VERSION "DIPBNNNYNNNNNNNNNNNNNNNNNNNNNNNNNNNNNNNNNN/4>*%%/4/'%**4NNN///"

NS_ :

BS_:

BU_: Gateway_1 Gateway_0

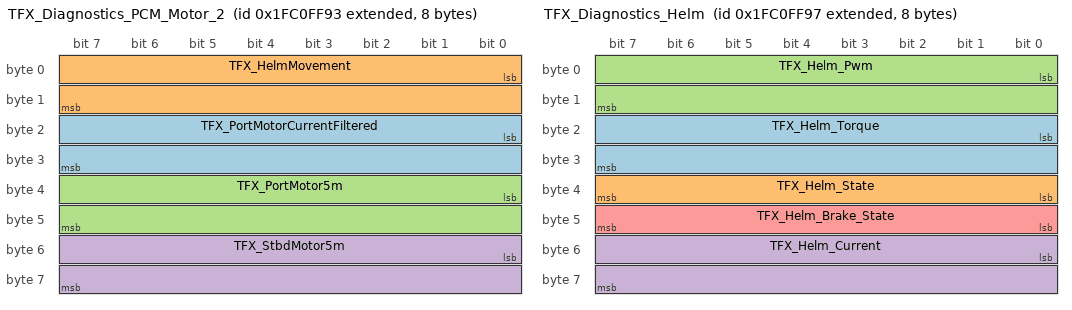
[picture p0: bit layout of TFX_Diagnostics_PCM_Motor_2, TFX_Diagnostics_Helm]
BO_ 2680225683 TFX_Diagnostics_PCM_Motor_2: 8 Vector__XXX
 SG_ TFX_PortMotorCurrentFiltered : 16|16@1- (0.1,0) [-3276.8|3276.7] "A" Vector__XXX
 SG_ TFX_HelmMovement : 0|16@1- (0.001,0) [-32.768|32.767] "°/ms" Vector__XXX
 SG_ TFX_PortMotor5m : 32|16@1- (1,0) [-500|500] "A^2" Vector__XXX
 SG_ TFX_StbdMotor5m : 48|16@1- (1,0) [-500|500] "A^2" Vector__XXX

BO_ 2680225680 TFX_Diagnostics_PCM_Power: 8 Vector__XXX
 SG_ TFX_PCM_Power_total : 32|32@1- (0.01,0) [0|0] "J" Vector__XXX
 SG_ TFX_PCM_Power : 0|32@1- (0.01,0) [0|1400] "W" Vector__XXX

BO_ 2680225687 TFX_Diagnostics_Helm: 8 Vector__XXX
 SG_ TFX_Helm_Torque : 16|16@1+ (0.01,0) [0|0] "in-lb" Vector__XXX
 SG_ TFX_Helm_State : 32|8@1+ (1,0) [0|0] "" Vector__XXX
 SG_ TFX_Helm_Pwm : 0|16@1+ (0.01,0) [0|0] "%" Vector__XXX
 SG_ TFX_Helm_Current : 48|16@1+ (0.001,0) [0|0] "A" Vector__XXX
 SG_ TFX_Helm_Brake_State : 40|8@1+ (1,0) [0|0] "" Vector__XXX

BO_ 2680225686 TFX_Diagnostics_Helm_Sensor: 8 Vector__XXX
 SG_ TFX_HelmSensor2_Sine : 32|16@1+ (1,0) [0|4096] "ADC" Vector__XXX
 SG_ TFX_HelmSensor2_Cosine : 48|16@1+ (1,0) [0|4096] "ADC" Vector__XXX
 SG_ TFX_HelmSensor1_Sine : 0|16@1+ (1,0) [0|4096] "ADC" Vector__XXX
 SG_ TFX_HelmSensor1_Cosine : 16|16@1+ (1,0) [0|4096] "ADC" Vector__XXX

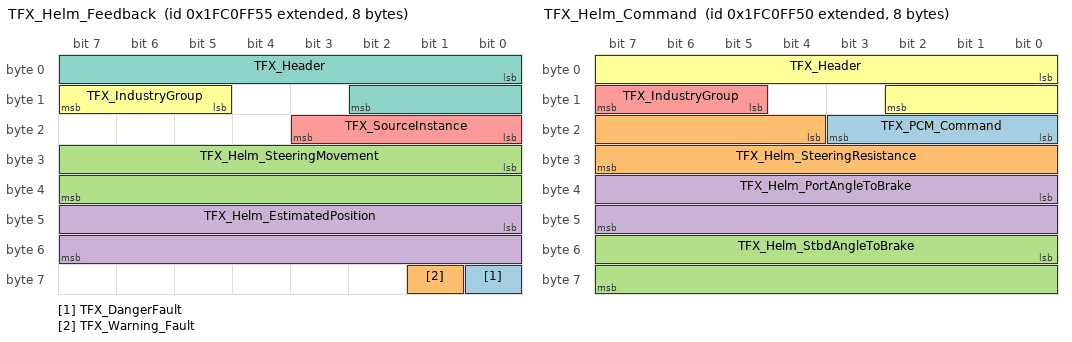
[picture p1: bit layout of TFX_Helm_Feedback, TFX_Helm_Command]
BO_ 2680225621 TFX_Helm_Feedback: 8 Vector__XXX
 SG_ TFX_DangerFault : 56|1@1+ (1,0) [0|0] "" Vector__XXX
 SG_ TFX_Warning_Fault : 57|1@1+ (1,0) [0|0] "" Vector__XXX
 SG_ TFX_Helm_SteeringMovement : 24|16@1- (0.01,0) [0|0] "°" Vector__XXX
 SG_ TFX_Helm_EstimatedPosition : 40|16@1- (0.1,0) [0|0] "°" Vector__XXX
 SG_ TFX_SourceInstance : 16|4@1+ (1,0) [0|0] "" Vector__XXX
 SG_ TFX_IndustryGroup : 13|3@1+ (1,0) [0|0] "" Vector__XXX
 SG_ TFX_Header : 0|11@1+ (1,0) [0|2047] "" Vector__XXX

BO_ 2680225616 TFX_Helm_Command: 8 Vector__XXX
 SG_ TFX_PCM_Command : 16|4@1+ (1,0) [0|0] "" Vector__XXX
 SG_ TFX_Helm_SteeringResistance : 20|12@1+ (0.1,0) [0|0] "%" Vector__XXX
 SG_ TFX_Helm_StbdAngleToBrake : 48|16@1- (0.1,0) [0|0] "°" Vector__XXX
 SG_ TFX_Helm_PortAngleToBrake : 32|16@1- (0.1,0) [0|0] "°" Vector__XXX
 SG_ TFX_IndustryGroup : 13|3@1+ (1,0) [0|0] "" Vector__XXX
 SG_ TFX_Header : 0|11@1+ (1,0) [0|2047] "" Vector__XXX

BO_ 2680225682 TFX_Diagnostics_PCM_Motor: 8 Vector__XXX
 SG_ TFX_PCM_StbdMotorPwm : 16|16@1- (0.01,0) [0|0] "%" Vector__XXX
 SG_ TFX_PCM_StbdMotorCurrent : 48|16@1- (0.01,0) [-327.68|327.67] "A" Vector__XXX
 SG_ TFX_PCM_PortMotorPwm : 0|16@1- (0.01,0) [0|0] "%" Vector__XXX
 SG_ TFX_PCM_PortMotorCurrent : 32|16@1- (0.01,0) [-327.68|327.67] "A" Vector__XXX

BO_ 2680225681 TFX_Diagnostics_PCM_Steering: 8 Vector__XXX
 SG_ TFX_PCM_StbdRudderFbk : 48|16@1- (0.01,0) [0|0] "°" Vector__XXX
 SG_ TFX_PCM_StbdRudderCmd : 16|16@1- (0.01,0) [0|0] "°" Vector__XXX
 SG_ TFX_PCM_PortRudderFbk : 32|16@1- (0.01,0) [0|0] "°" Vector__XXX
 SG_ TFX_PCM_PortRudderCmd : 0|16@1- (0.01,0) [0|0] "°" Vector__XXX

BO_ 2147610885 HeadingTrackControl: 21 Vector__XXX
 SG_ VesselHeading : 152|16@1+ (0.0001,0) [0|6.2831] "rad" Vector__XXX
 SG_ OffTrackLimit : 136|16@1- (1,0) [-32764|32764] "m" Vector__XXX
 SG_ RateOfTurnOrder : 120|16@1- (0.03,0) [-1|1] "rad/sec" Vector__XXX
 SG_ RadiusOfTurnOrder : 104|16@1- (1,0) [-32764|32764] "m" Vector__XXX
 SG_ OffHeadingLimit : 88|16@1+ (0.0001,0) [0|6.2831] "rad" Vector__XXX
 SG_ RudderLimit : 72|16@1+ (0.0057296,0) [0|50] "°" Vector__XXX
 SG_ Track : 56|16@1+ (0.0001,0) [0|6.2831] "rad" Vector__XXX
 SG_ HeadingToSteer : 40|16@1+ (0.0001,0) [0|6.2831] "rad" Vector__XXX
 SG_ CommandedRudderAngle : 24|16@1- (0.0001,0) [-3.415|3.1415] "rad" Vector__XXX
 SG_ CommandedRudderDirection : 21|3@1+ (1,0) [0|0] "" Vector__XXX
 SG_ HeadingReference : 14|2@1+ (1,0) [0|0] "" Vector__XXX
 SG_ TurnMode : 11|3@1+ (1,0) [0|0] "" Vector__XXX
 SG_ SteerigMode : 8|3@1+ (1,0) [0|0] "" Vector__XXX
 SG_ Override : 6|2@1+ (1,0) [0|0] "" Vector__XXX
 SG_ OffTrackLimitExceeded : 4|2@1+ (1,0) [0|0] "" Vector__XXX
 SG_ OffheadingLimitExceeded : 2|2@1+ (1,0) [0|0] "" Vector__XXX
 SG_ RudderLimitExceeded : 0|2@1+ (1,0) [0|0] "" Vector__XXX

BO_ 2680225679 TFX_Diagnostics_VC_SetPt_RPM: 8 Vector__XXX
 SG_ TFX_VC_RPMCmd_SCtr : 48|16@1+ (0.25,0) [0|6000] "RPM" Vector__XXX
 SG_ TFX_VC_RPMCmd_PCtr : 32|16@1+ (0.25,0) [0|6000] "RPM" Vector__XXX
 SG_ TFX_VC_RPMCmd_Stbd : 16|16@1+ (0.25,0) [0|6000] "RPM" Vector__XXX
 SG_ TFX_VC_RPMCmd_Port : 0|16@1+ (0.25,0) [0|6000] "RPM" Vector__XXX

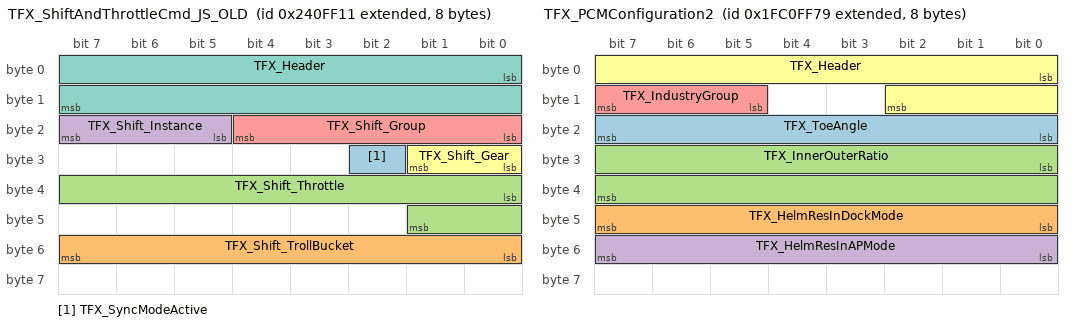
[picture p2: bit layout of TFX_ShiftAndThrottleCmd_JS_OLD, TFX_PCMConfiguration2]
BO_ 2185297681 TFX_ShiftAndThrottleCmd_JS_OLD: 8 Vector__XXX
 SG_ TFX_SyncModeActive : 26|1@1+ (1,0) [0|0] "" Vector__XXX
 SG_ TFX_Shift_TrollBucket : 48|8@1- (1,0) [0|0] "" Vector__XXX
 SG_ TFX_Shift_Throttle : 32|10@1+ (0.1,0) [0|0] "%" Vector__XXX
 SG_ TFX_Shift_Instance : 21|3@1+ (1,0) [0|0] "" Vector__XXX
 SG_ TFX_Shift_Group : 16|5@1+ (1,0) [0|0] "" Vector__XXX
 SG_ TFX_Shift_Gear : 24|2@1+ (1,0) [0|0] "" Vector__XXX
 SG_ TFX_Header : 0|16@1+ (1,0) [0|0] "" Vector__XXX

BO_ 2680225657 TFX_PCMConfiguration2: 8 Vector__XXX
 SG_ TFX_ToeAngle : 16|8@1- (0.1,0) [-12.8|12.7] "deg" Vector__XXX
 SG_ TFX_HelmResInDockMode : 40|8@1+ (1,0) [0|0] "" Vector__XXX
 SG_ TFX_InnerOuterRatio : 24|16@1+ (0.01,0) [0|655.35] "" Vector__XXX
 SG_ TFX_HelmResInAPMode : 48|8@1+ (1,0) [0|0] "" Vector__XXX
 SG_ TFX_IndustryGroup : 13|3@1+ (1,0) [0|0] "" Vector__XXX
 SG_ TFX_Header : 0|11@1+ (1,0) [0|2047] "" Vector__XXX

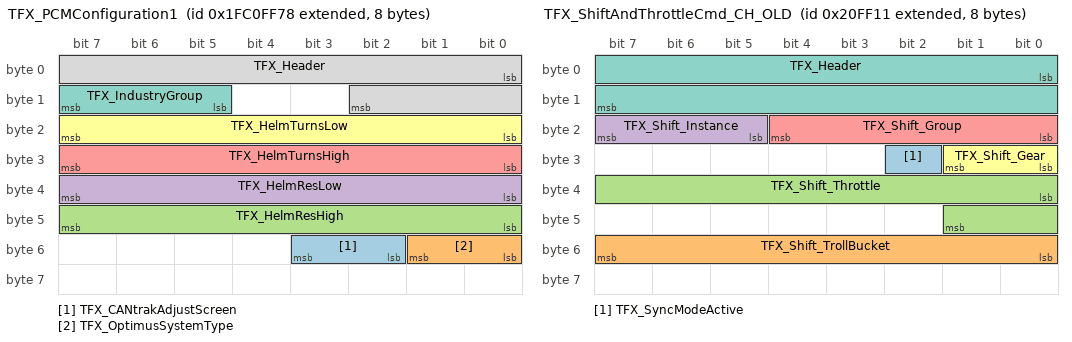
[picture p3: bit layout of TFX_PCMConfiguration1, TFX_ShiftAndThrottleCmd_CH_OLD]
BO_ 2680225656 TFX_PCMConfiguration1: 8 Vector__XXX
 SG_ TFX_CANtrakAdjustScreen : 50|2@1+ (1,0) [0|0] "" Vector__XXX
 SG_ TFX_OptimusSystemType : 48|2@1+ (1,0) [0|0] "" Vector__XXX
 SG_ TFX_HelmResHigh : 40|8@1+ (1,0) [0|0] "" Vector__XXX
 SG_ TFX_HelmResLow : 32|8@1+ (1,0) [0|0] "" Vector__XXX
 SG_ TFX_HelmTurnsHigh : 24|8@1+ (0.1,0) [0|25.5] "Turns" Vector__XXX
 SG_ TFX_HelmTurnsLow : 16|8@1+ (0.1,0) [0|25.5] "Turns" Vector__XXX
 SG_ TFX_IndustryGroup : 13|3@1+ (1,0) [0|0] "" Vector__XXX
 SG_ TFX_Header : 0|11@1+ (1,0) [0|2047] "" Vector__XXX

BO_ 2149646097 TFX_ShiftAndThrottleCmd_CH_OLD: 8 Vector__XXX
 SG_ TFX_SyncModeActive : 26|1@1+ (1,0) [0|0] "" Vector__XXX
 SG_ TFX_Shift_TrollBucket : 48|8@1- (1,0) [0|0] "" Vector__XXX
 SG_ TFX_Shift_Throttle : 32|10@1+ (0.1,0) [0|0] "%" Vector__XXX
 SG_ TFX_Shift_Instance : 21|3@1+ (1,0) [0|0] "" Vector__XXX
 SG_ TFX_Shift_Group : 16|5@1+ (1,0) [0|0] "" Vector__XXX
 SG_ TFX_Shift_Gear : 24|2@1+ (1,0) [0|0] "" Vector__XXX
 SG_ TFX_Header : 0|16@1+ (1,0) [0|0] "" Vector__XXX

BO_ 2680225678 TFX_Diagnostics_ClosedLoop: 8 Vector__XXX
 SG_ TFX_PrtRPMError : 0|16@1- (0.25,0) [-5000|5000] "RPM" Vector__XXX
 SG_ TFX_StbdThrtlAdjust : 48|16@1- (0.1,0) [0|100] "%" Vector__XXX
 SG_ TFX_StbdRPMError : 16|16@1- (0.25,0) [-5000|5000] "RPM" Vector__XXX
 SG_ TFX_PrtThrtlAdjust : 32|16@1- (0.1,0) [0|100] "%" Vector__XXX

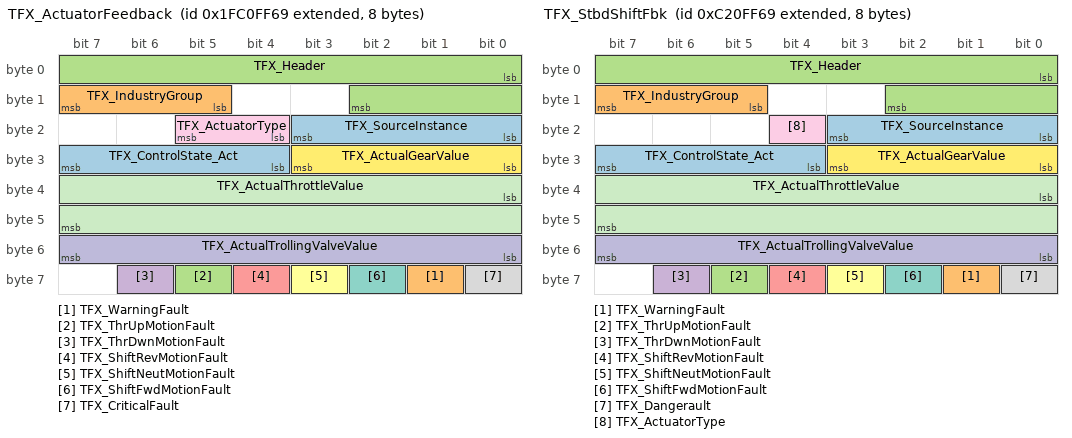
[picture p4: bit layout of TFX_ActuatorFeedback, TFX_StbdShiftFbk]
BO_ 2680225641 TFX_ActuatorFeedback: 8 Vector__XXX
 SG_ TFX_ControlState_Act : 28|4@1+ (1,0) [0|0] "" Vector__XXX
 SG_ TFX_WarningFault : 57|1@1+ (1,0) [0|0] "" Vector__XXX
 SG_ TFX_ThrUpMotionFault : 61|1@1+ (1,0) [0|0] "" Vector__XXX
 SG_ TFX_ThrDwnMotionFault : 62|1@1+ (1,0) [0|0] "" Vector__XXX
 SG_ TFX_ShiftRevMotionFault : 60|1@1+ (1,0) [0|0] "" Vector__XXX
 SG_ TFX_ShiftNeutMotionFault : 59|1@1+ (1,0) [0|0] "" Vector__XXX
 SG_ TFX_ShiftFwdMotionFault : 58|1@1+ (1,0) [0|0] "" Vector__XXX
 SG_ TFX_CriticalFault : 56|1@1+ (1,0) [0|0] "" Vector__XXX
 SG_ TFX_ActuatorType : 20|2@1+ (1,0) [0|3] "" Vector__XXX
 SG_ TFX_ActualTrollingValveValue : 48|8@1+ (1,0) [0|100] "%" Vector__XXX
 SG_ TFX_ActualThrottleValue : 32|16@1+ (0.1,0) [0|100] "%" Vector__XXX
 SG_ TFX_ActualGearValue : 24|4@1- (1,0) [0|0] "" Vector__XXX
 SG_ TFX_SourceInstance : 16|4@1+ (1,0) [0|0] "" Vector__XXX
 SG_ TFX_IndustryGroup : 13|3@1+ (1,0) [0|0] "" Vector__XXX
 SG_ TFX_Header : 0|11@1+ (1,0) [0|2047] "" Vector__XXX

BO_ 2350972777 TFX_StbdShiftFbk: 8 Vector__XXX
 SG_ TFX_ControlState_Act : 28|4@1+ (1,0) [0|0] "" Vector__XXX
 SG_ TFX_WarningFault : 57|1@1+ (1,0) [0|0] "" Vector__XXX
 SG_ TFX_ThrUpMotionFault : 61|1@1+ (1,0) [0|0] "" Vector__XXX
 SG_ TFX_ThrDwnMotionFault : 62|1@1+ (1,0) [0|0] "" Vector__XXX
 SG_ TFX_ShiftRevMotionFault : 60|1@1+ (1,0) [0|0] "" Vector__XXX
 SG_ TFX_ShiftNeutMotionFault : 59|1@1+ (1,0) [0|0] "" Vector__XXX
 SG_ TFX_ShiftFwdMotionFault : 58|1@1+ (1,0) [0|0] "" Vector__XXX
 SG_ TFX_Dangerault : 56|1@1+ (1,0) [0|0] "" Vector__XXX
 SG_ TFX_ActuatorType : 20|1@1+ (1,0) [0|0] "" Vector__XXX
 SG_ TFX_ActualTrollingValveValue : 48|8@1+ (1,0) [0|100] "%" Vector__XXX
 SG_ TFX_ActualThrottleValue : 32|16@1+ (0.1,0) [0|100] "%" Vector__XXX
 SG_ TFX_ActualGearValue : 24|4@1- (1,0) [0|2] "" Vector__XXX
 SG_ TFX_SourceInstance : 16|4@1+ (1,0) [0|0] "" Vector__XXX
 SG_ TFX_IndustryGroup : 13|3@1+ (1,0) [0|0] "" Vector__XXX
 SG_ TFX_Header : 0|11@1+ (1,0) [0|2047] "" Vector__XXX

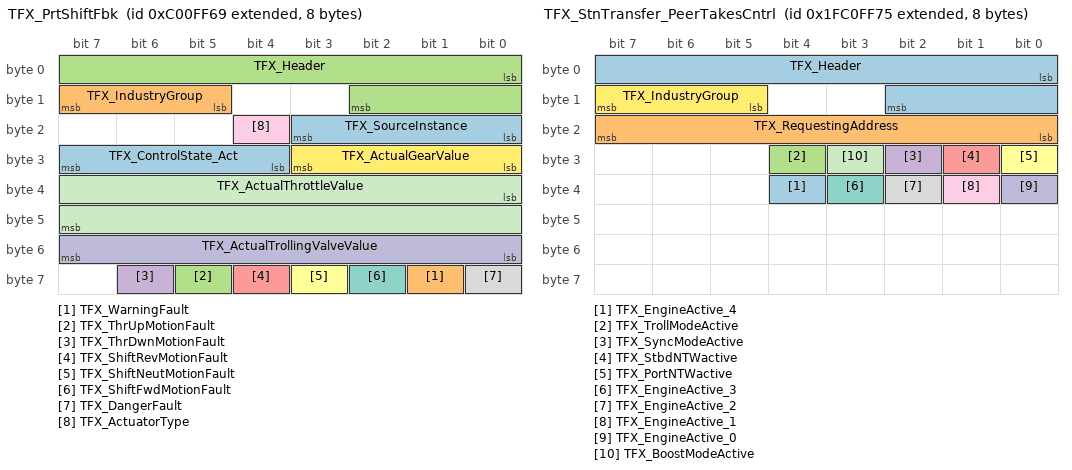
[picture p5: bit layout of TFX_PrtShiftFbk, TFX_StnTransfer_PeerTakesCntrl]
BO_ 2348875625 TFX_PrtShiftFbk: 8 Vector__XXX
 SG_ TFX_ControlState_Act : 28|4@1+ (1,0) [0|0] "" Vector__XXX
 SG_ TFX_WarningFault : 57|1@1+ (1,0) [0|0] "" Vector__XXX
 SG_ TFX_ThrUpMotionFault : 61|1@1+ (1,0) [0|0] "" Vector__XXX
 SG_ TFX_ThrDwnMotionFault : 62|1@1+ (1,0) [0|0] "" Vector__XXX
 SG_ TFX_ShiftRevMotionFault : 60|1@1+ (1,0) [0|0] "" Vector__XXX
 SG_ TFX_ShiftNeutMotionFault : 59|1@1+ (1,0) [0|0] "" Vector__XXX
 SG_ TFX_ShiftFwdMotionFault : 58|1@1+ (1,0) [0|0] "" Vector__XXX
 SG_ TFX_DangerFault : 56|1@1+ (1,0) [0|0] "" Vector__XXX
 SG_ TFX_ActuatorType : 20|1@1+ (1,0) [0|0] "" Vector__XXX
 SG_ TFX_ActualTrollingValveValue : 48|8@1+ (1,0) [0|100] "%" Vector__XXX
 SG_ TFX_ActualThrottleValue : 32|16@1+ (0.1,0) [0|100] "%" Vector__XXX
 SG_ TFX_ActualGearValue : 24|4@1- (1,0) [0|2] "" Vector__XXX
 SG_ TFX_SourceInstance : 16|4@1+ (1,0) [0|0] "" Vector__XXX
 SG_ TFX_IndustryGroup : 13|3@1+ (1,0) [0|0] "" Vector__XXX
 SG_ TFX_Header : 0|11@1+ (1,0) [0|2047] "" Vector__XXX

BO_ 2680225697 TFX_Diagnostics_ThrActs: 8 Vector__XXX
 SG_ TFX_StbdThrtlFbk : 48|16@1+ (0.1,0) [0|100] "%" Vector__XXX
 SG_ TFX_PrtThrtlFbk : 32|16@1+ (0.1,0) [0|100] "%" Vector__XXX
 SG_ TFX_StbdThrtlCmd : 16|16@1+ (0.1,0) [0|100] "%" Vector__XXX
 SG_ TFX_PrtThrtlCmd : 0|16@1+ (0.1,0) [0|100] "%" Vector__XXX

BO_ 2680225653 TFX_StnTransfer_PeerTakesCntrl: 8 Vector__XXX
 SG_ TFX_EngineActive_4 : 36|1@1+ (1,0) [0|0] "" Vector__XXX
 SG_ TFX_RequestingAddress : 16|8@1+ (1,0) [0|0] "" Vector__XXX
 SG_ TFX_TrollModeActive : 28|1@1+ (1,0) [0|0] "" Vector__XXX
 SG_ TFX_SyncModeActive : 26|1@1+ (1,0) [0|0] "" Vector__XXX
 SG_ TFX_StbdNTWactive : 25|1@1+ (1,0) [0|0] "" Vector__XXX
 SG_ TFX_PortNTWactive : 24|1@1+ (1,0) [0|0] "" Vector__XXX
 SG_ TFX_EngineActive_3 : 35|1@1+ (1,0) [0|0] "" Vector__XXX
 SG_ TFX_EngineActive_2 : 34|1@1+ (1,0) [0|0] "" Vector__XXX
 SG_ TFX_EngineActive_1 : 33|1@1+ (1,0) [0|0] "" Vector__XXX
 SG_ TFX_EngineActive_0 : 32|1@1+ (1,0) [0|0] "" Vector__XXX
 SG_ TFX_BoostModeActive : 27|1@1+ (1,0) [0|0] "" Vector__XXX
 SG_ TFX_IndustryGroup : 13|3@1+ (1,0) [0|0] "" Vector__XXX
 SG_ TFX_Header : 0|11@1+ (1,0) [0|2047] "" Vector__XXX

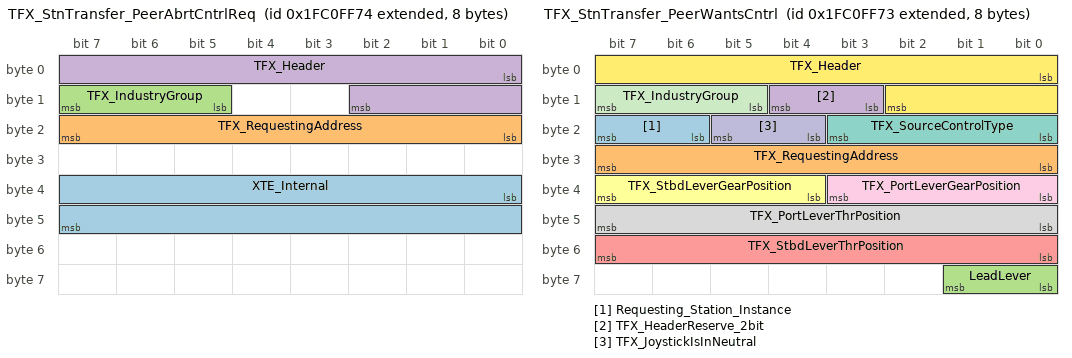
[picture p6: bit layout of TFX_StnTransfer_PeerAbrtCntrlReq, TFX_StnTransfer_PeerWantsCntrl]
BO_ 2680225652 TFX_StnTransfer_PeerAbrtCntrlReq: 8 Vector__XXX
 SG_ XTE_Internal : 32|16@1- (0.1,0) [0|200] "m" Vector__XXX
 SG_ TFX_RequestingAddress : 16|8@1+ (1,0) [0|0] "" Vector__XXX
 SG_ TFX_IndustryGroup : 13|3@1+ (1,0) [0|0] "" Vector__XXX
 SG_ TFX_Header : 0|11@1+ (1,0) [0|2047] "" Vector__XXX

BO_ 2680225651 TFX_StnTransfer_PeerWantsCntrl: 8 Vector__XXX
 SG_ Requesting_Station_Instance : 22|2@1+ (1,0) [0|0] "" Vector__XXX
 SG_ TFX_RequestingAddress : 24|8@1+ (1,0) [0|0] "" Vector__XXX
 SG_ LeadLever : 56|2@1+ (1,0) [0|0] "" Vector__XXX
 SG_ TFX_HeaderReserve_2bit : 11|2@1- (1,0) [0|0] "" Vector__XXX
 SG_ TFX_StbdLeverThrPosition : 48|8@1+ (1,0) [0|100] "%" Vector__XXX
 SG_ TFX_StbdLeverGearPosition : 36|4@1+ (1,0) [0|0] "" Vector__XXX
 SG_ TFX_SourceControlType : 16|4@1+ (1,0) [0|0] "" Vector__XXX
 SG_ TFX_PortLeverThrPosition : 40|8@1+ (1,0) [0|100] "%" Vector__XXX
 SG_ TFX_PortLeverGearPosition : 32|4@1+ (1,0) [0|0] "" Vector__XXX
 SG_ TFX_JoystickIsInNeutral : 20|2@1+ (1,0) [0|0] "" Vector__XXX
 SG_ TFX_IndustryGroup : 13|3@1+ (1,0) [0|0] "" Vector__XXX
 SG_ TFX_Header : 0|11@1+ (1,0) [0|2047] "" Vector__XXX

BO_ 2680225649 TFX_ActuatorStatus: 8 Vector__XXX
 SG_ TFX_TachometerSignalInvalid : 46|1@1+ (1,0) [0|0] "" Vector__XXX
 SG_ TFX_ShiftOutputFault_B : 45|1@1+ (1,0) [0|0] "" Vector__XXX
 SG_ TFX_ShiftOutputFault_A : 44|1@1+ (1,0) [0|0] "" Vector__XXX
 SG_ TFX_PosSensorShrtToGndFault : 39|1@1+ (1,0) [0|0] "" Vector__XXX
 SG_ TFX_PosSensorOpenFault : 40|1@1+ (1,0) [0|0] "" Vector__XXX
 SG_ TFX_PosSensorNotCalibratedFault : 41|1@1+ (1,0) [0|0] "" Vector__XXX
 SG_ TFX_MotorOverCurrentFault : 37|1@1+ (1,0) [0|0] "" Vector__XXX
 SG_ TFX_MotorOpenCircuitFault : 38|1@1+ (1,0) [0|0] "" Vector__XXX
 SG_ TFX_CHorJoystickHrtBtLoss : 47|1@1+ (1,0) [0|0] "" Vector__XXX
 SG_ TFX_BatteryVoltageTooLowFault : 42|1@1+ (1,0) [0|0] "" Vector__XXX
 SG_ TFX_BatteryVoltageTooHighFault : 43|1@1+ (1,0) [0|0] "" Vector__XXX
 SG_ TFX_ThrUpMotionFault : 35|1@1+ (1,0) [0|0] "" Vector__XXX
 SG_ TFX_ThrDwnMotionFault : 36|1@1+ (1,0) [0|0] "" Vector__XXX
 SG_ TFX_ShiftRevMotionFault : 34|1@1+ (1,0) [0|0] "" Vector__XXX
 SG_ TFX_ShiftNeutMotionFault : 33|1@1+ (1,0) [0|0] "" Vector__XXX
 SG_ TFX_ShiftFwdMotionFault : 32|1@1+ (1,0) [0|0] "" Vector__XXX
 SG_ TFX_ActuatorType : 20|1@1+ (1,0) [0|0] "" Vector__XXX
 SG_ TFX_ControlState : 24|4@1+ (1,0) [0|0] "" Vector__XXX
 SG_ TFX_SourceInstance : 16|4@1+ (1,0) [0|0] "" Vector__XXX
 SG_ TFX_IndustryGroup : 13|3@1+ (1,0) [0|0] "" Vector__XXX
 SG_ TFX_Header : 0|11@1+ (1,0) [0|2047] "" Vector__XXX

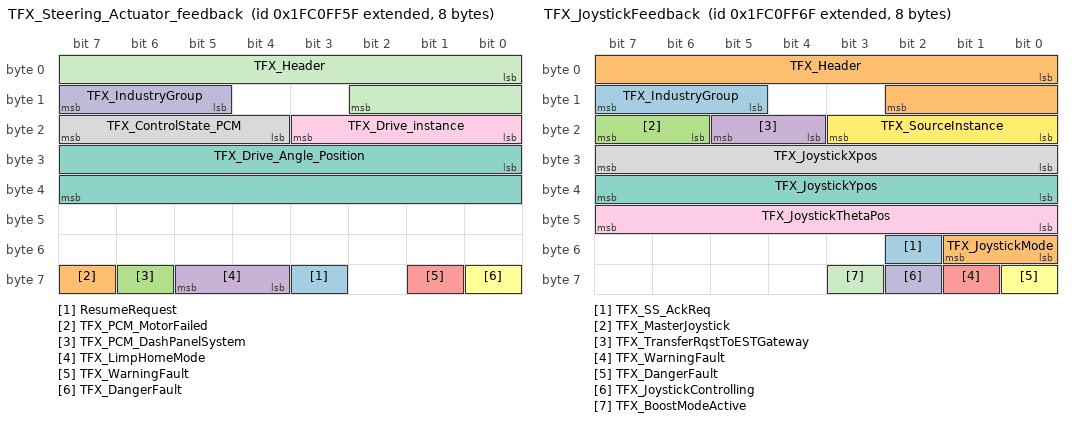
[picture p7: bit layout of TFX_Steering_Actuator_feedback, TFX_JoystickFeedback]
BO_ 2680225631 TFX_Steering_Actuator_feedback: 8 Vector__XXX
 SG_ ResumeRequest : 59|1@1+ (1,0) [0|1] "" Vector__XXX
 SG_ TFX_PCM_MotorFailed : 63|1@1+ (1,0) [0|0] "" Vector__XXX
 SG_ TFX_PCM_DashPanelSystem : 62|1@1+ (1,0) [0|0] "" Vector__XXX
 SG_ TFX_LimpHomeMode : 60|2@1+ (1,0) [0|0] "" Vector__XXX
 SG_ TFX_WarningFault : 57|1@1+ (1,0) [0|0] "" Vector__XXX
 SG_ TFX_DangerFault : 56|1@1+ (1,0) [0|0] "" Vector__XXX
 SG_ TFX_Drive_Angle_Position : 24|16@1- (0.01,0) [-30|30] "deg" Vector__XXX
 SG_ TFX_ControlState_PCM : 20|4@1+ (1,0) [0|0] "" Vector__XXX
 SG_ TFX_Drive_instance : 16|4@1+ (1,0) [0|0] "" Vector__XXX
 SG_ TFX_IndustryGroup : 13|3@1+ (1,0) [0|0] "" Vector__XXX
 SG_ TFX_Header : 0|11@1+ (1,0) [0|2047] "" Vector__XXX

BO_ 2680225647 TFX_JoystickFeedback: 8 Vector__XXX
 SG_ TFX_SS_AckReq : 50|1@1+ (1,0) [0|0] "" Vector__XXX
 SG_ TFX_JoystickMode : 48|2@1+ (1,0) [0|0] "" Vector__XXX
 SG_ TFX_MasterJoystick : 22|2@1+ (1,0) [0|0] "" Vector__XXX
 SG_ TFX_TransferRqstToESTGateway : 20|2@1+ (1,0) [0|3] "" Vector__XXX
 SG_ TFX_WarningFault : 57|1@1+ (1,0) [0|0] "" Vector__XXX
 SG_ TFX_DangerFault : 56|1@1+ (1,0) [0|0] "" Vector__XXX
 SG_ TFX_JoystickYpos : 32|8@1- (1,0) [-100|100] "%" Vector__XXX
 SG_ TFX_JoystickXpos : 24|8@1- (1,0) [-100|100] "%" Vector__XXX
 SG_ TFX_JoystickThetaPos : 40|8@1- (1,0) [-100|100] "%" Vector__XXX
 SG_ TFX_JoystickControlling : 58|1@1+ (1,0) [0|0] "" Vector__XXX
 SG_ TFX_BoostModeActive : 59|1@1+ (1,0) [0|0] "" Vector__XXX
 SG_ TFX_SourceInstance : 16|4@1+ (1,0) [0|0] "" Vector__XXX
 SG_ TFX_IndustryGroup : 13|3@1+ (1,0) [0|0] "" Vector__XXX
 SG_ TFX_Header : 0|11@1+ (1,0) [0|2047] "" Vector__XXX

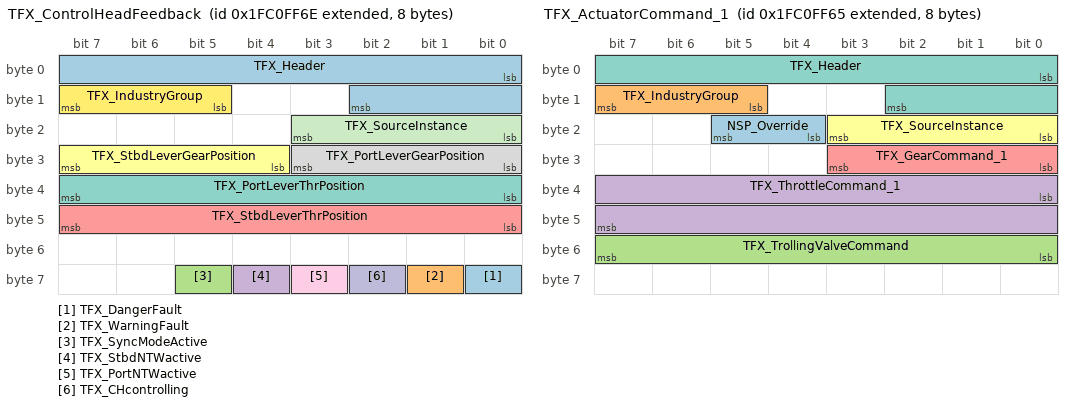
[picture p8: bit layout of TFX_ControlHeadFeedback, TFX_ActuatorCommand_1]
BO_ 2680225646 TFX_ControlHeadFeedback: 8 Vector__XXX
 SG_ TFX_DangerFault : 56|1@1+ (1,0) [0|0] "" Vector__XXX
 SG_ TFX_WarningFault : 57|1@1+ (1,0) [0|0] "" Vector__XXX
 SG_ TFX_SyncModeActive : 61|1@1+ (1,0) [0|0] "" Vector__XXX
 SG_ TFX_StbdNTWactive : 60|1@1+ (1,0) [0|0] "" Vector__XXX
 SG_ TFX_StbdLeverThrPosition : 40|8@1+ (1,0) [0|100] "%" Vector__XXX
 SG_ TFX_StbdLeverGearPosition : 28|4@1+ (1,0) [0|0] "" Vector__XXX
 SG_ TFX_PortLeverThrPosition : 32|8@1+ (1,0) [0|100] "%" Vector__XXX
 SG_ TFX_PortLeverGearPosition : 24|4@1+ (1,0) [0|0] "" Vector__XXX
 SG_ TFX_PortNTWactive : 59|1@1+ (1,0) [0|0] "" Vector__XXX
 SG_ TFX_CHcontrolling : 58|1@1+ (1,0) [0|0] "" Vector__XXX
 SG_ TFX_SourceInstance : 16|4@1+ (1,0) [0|0] "" Vector__XXX
 SG_ TFX_IndustryGroup : 13|3@1+ (1,0) [0|0] "" Vector__XXX
 SG_ TFX_Header : 0|11@1+ (1,0) [0|0] "" Vector__XXX

BO_ 2680225637 TFX_ActuatorCommand_1: 8 Vector__XXX
 SG_ NSP_Override : 20|2@1+ (1,0) [0|0] "" Vector__XXX
 SG_ TFX_IndustryGroup : 13|3@1+ (1,0) [0|0] "" Vector__XXX
 SG_ TFX_TrollingValveCommand : 48|8@1+ (1,0) [0|0] "%" Vector__XXX
 SG_ TFX_ThrottleCommand_1 : 32|16@1+ (0.1,0) [0|100] "%" Vector__XXX
 SG_ TFX_GearCommand_1 : 24|4@1+ (1,0) [0|2] "" Vector__XXX
 SG_ TFX_SourceInstance : 16|4@1+ (1,0) [0|15] "" Vector__XXX
 SG_ TFX_Header : 0|11@1+ (1,0) [0|2047] "" Vector__XXX

BO_ 2680225696 TFX_Diagnostics_ShftActs: 8 Vector__XXX
 SG_ TFX_StbdShftFbk : 24|8@1+ (1,0) [0|0] "" Vector__XXX
 SG_ TFX_PrtShftFbk : 16|8@1+ (1,0) [0|0] "" Vector__XXX
 SG_ TFX_StbdShftCmd : 8|8@1+ (1,0) [0|0] "" Vector__XXX
 SG_ TFX_PrtShftCmd : 0|8@1+ (1,0) [0|0] "" Vector__XXX

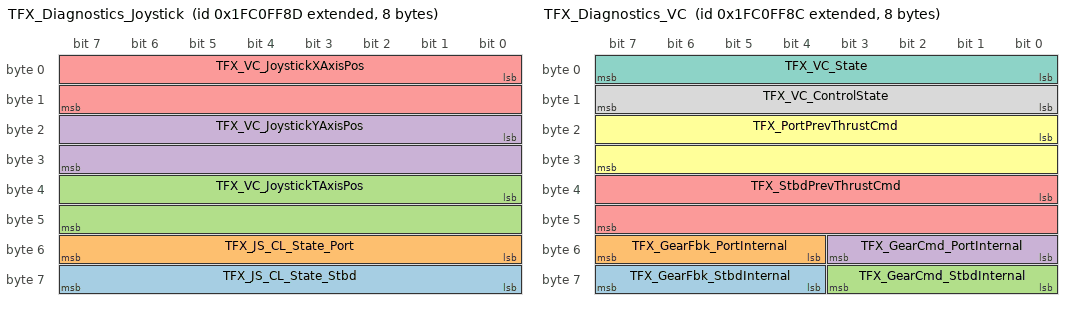
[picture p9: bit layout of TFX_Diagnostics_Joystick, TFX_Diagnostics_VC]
BO_ 2680225677 TFX_Diagnostics_Joystick: 8 Vector__XXX
 SG_ TFX_JS_CL_State_Stbd : 56|8@1+ (1,0) [0|0] "" Vector__XXX
 SG_ TFX_JS_CL_State_Port : 48|8@1+ (1,0) [0|0] "" Vector__XXX
 SG_ TFX_VC_JoystickTAxisPos : 32|16@1- (0.01,0) [-100|100] "%" Vector__XXX
 SG_ TFX_VC_JoystickYAxisPos : 16|16@1- (0.01,0) [-100|100] "%" Vector__XXX
 SG_ TFX_VC_JoystickXAxisPos : 0|16@1- (0.01,0) [-100|100] "%" Vector__XXX

BO_ 2680225676 TFX_Diagnostics_VC: 8 Vector__XXX
 SG_ TFX_GearFbk_StbdInternal : 60|4@1+ (1,0) [0|2] "" Vector__XXX
 SG_ TFX_GearFbk_PortInternal : 52|4@1+ (1,0) [0|2] "" Vector__XXX
 SG_ TFX_GearCmd_StbdInternal : 56|4@1+ (1,0) [0|2] "" Vector__XXX
 SG_ TFX_GearCmd_PortInternal : 48|4@1+ (1,0) [0|2] "" Vector__XXX
 SG_ TFX_StbdPrevThrustCmd : 32|16@1- (0.01,0) [-327.68|327.67] "%" Vector__XXX
 SG_ TFX_PortPrevThrustCmd : 16|16@1- (0.01,0) [-327.68|327.67] "%" Vector__XXX
 SG_ TFX_VC_State : 0|8@1+ (1,0) [0|0] "" Vector__XXX
 SG_ TFX_VC_ControlState : 8|8@1+ (1,0) [0|0] "" Vector__XXX

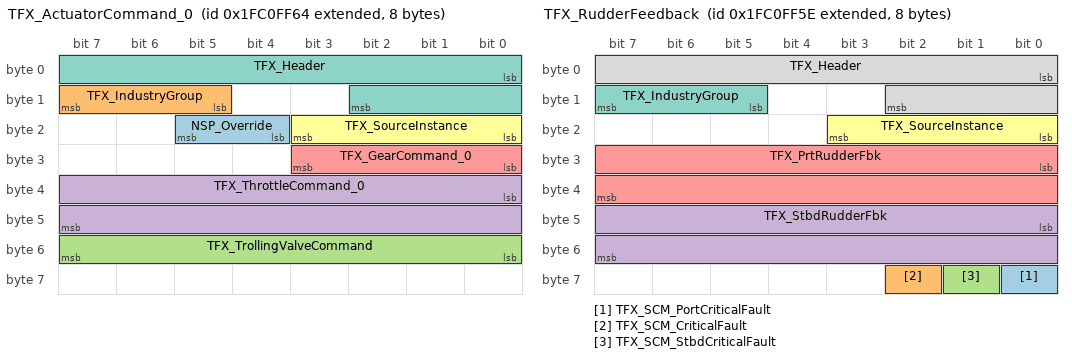
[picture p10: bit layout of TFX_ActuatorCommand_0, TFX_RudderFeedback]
BO_ 2680225636 TFX_ActuatorCommand_0: 8 Vector__XXX
 SG_ NSP_Override : 20|2@1+ (1,0) [0|0] "" Vector__XXX
 SG_ TFX_IndustryGroup : 13|3@1+ (1,0) [0|0] "" Vector__XXX
 SG_ TFX_TrollingValveCommand : 48|8@1+ (1,0) [0|0] "%" Vector__XXX
 SG_ TFX_ThrottleCommand_0 : 32|16@1+ (0.1,0) [0|100] "%" Vector__XXX
 SG_ TFX_GearCommand_0 : 24|4@1+ (1,0) [0|2] "" Vector__XXX
 SG_ TFX_SourceInstance : 16|4@1+ (1,0) [0|15] "" Vector__XXX
 SG_ TFX_Header : 0|11@1+ (1,0) [0|2047] "" Vector__XXX

BO_ 2680225630 TFX_RudderFeedback: 8 Vector__XXX
 SG_ TFX_SCM_PortCriticalFault : 56|1@1- (1,0) [0|0] "" Vector__XXX
 SG_ TFX_SCM_CriticalFault : 58|1@1- (1,0) [0|0] "" Vector__XXX
 SG_ TFX_SCM_StbdCriticalFault : 57|1@1- (1,0) [0|0] "" Vector__XXX
 SG_ TFX_StbdRudderFbk : 40|16@1- (0.01,0) [-30|30] "deg" Vector__XXX
 SG_ TFX_PrtRudderFbk : 24|16@1- (0.01,0) [-30|30] "deg" Vector__XXX
 SG_ TFX_SourceInstance : 16|4@1+ (1,0) [0|0] "" Vector__XXX
 SG_ TFX_IndustryGroup : 13|3@1+ (1,0) [0|0] "" Vector__XXX
 SG_ TFX_Header : 0|11@1+ (1,0) [0|0] "" Vector__XXX

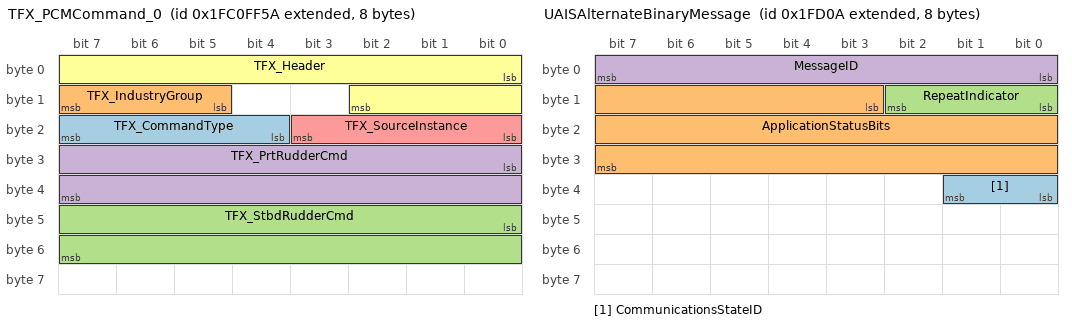
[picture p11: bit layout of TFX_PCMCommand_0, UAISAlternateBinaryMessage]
BO_ 2680225626 TFX_PCMCommand_0: 8 Vector__XXX
 SG_ TFX_CommandType : 20|4@1+ (1,0) [0|0] "" Vector__XXX
 SG_ TFX_IndustryGroup : 13|3@1+ (1,0) [0|0] "" Vector__XXX
 SG_ TFX_StbdRudderCmd : 40|16@1- (0.01,0) [-30|30] "deg" Vector__XXX
 SG_ TFX_PrtRudderCmd : 24|16@1- (0.01,0) [-30|30] "deg" Vector__XXX
 SG_ TFX_SourceInstance : 16|4@1+ (1,0) [0|0] "" Vector__XXX
 SG_ TFX_Header : 0|11@1+ (1,0) [0|0] "" Vector__XXX

BO_ 2147614226 VesselSpeedComponents: 12 Vector__XXX
 SG_ SternSpeedGroundRef : 80|16@1- (0.001,0) [-32.764|32.764] "m/s" Vector__XXX
 SG_ SternSpeedWaterRef : 64|16@1- (0.001,0) [-32.764|32.764] "m/s" Vector__XXX
 SG_ TransSpeedGroundRef : 48|16@1- (0.001,0) [-32.764|32.764] "m/s" Vector__XXX
 SG_ LongSpeedGroundRef : 32|16@1- (0.001,0) [-32.764|32.764] "m/s" Vector__XXX
 SG_ TransSpeedWaterRef : 16|16@1- (0.001,0) [-32.764|32.764] "m/s" Vector__XXX
 SG_ LongSpeedWaterRef : 0|16@1- (0.001,0) [-32.764|32.764] "m/s" Vector__XXX

BO_ 2147614225 DirectionData: 14 Vector__XXX
 SG_ DriftSpeed : 96|16@1+ (0.01,0) [0|655.32] "m/s" Vector__XXX
 SG_ CurrentFlowDirection : 80|16@1+ (0.0001,0) [0|6.2831] "rad" Vector__XXX
 SG_ Speed : 64|16@1+ (0.01,0) [0|655.32] "m/s" Vector__XXX
 SG_ Heading : 48|16@1+ (0.0001,0) [0|6.2831] "rad" Vector__XXX
 SG_ SpeedOverGround : 32|16@1+ (0.0001,0) [0|655.32] "m/s" Vector__XXX
 SG_ CourseOverGround : 16|16@1+ (0.0001,0) [0|6.2831] "rad" Vector__XXX
 SG_ SeqID : 8|8@1+ (1,0) [0|252] "" Vector__XXX
 SG_ SetCOGheadingRef : 4|2@1+ (1,0) [0|0] "" Vector__XXX
 SG_ DataMode : 0|4@1+ (1,0) [0|0] "" Vector__XXX

BO_ 2147614224 SmallCraftStatus: 8 Vector__XXX
 SG_ StarboardTrimTab : 8|8@1- (1,0) [-124|124] "%" Vector__XXX
 SG_ PortTrimTab : 0|8@1- (1,0) [-124|124] "%" Vector__XXX

BO_ 2147613972 MooredBuoyStationData: 42 Vector__XXX
 SG_ WaterTemperature : 256|16@1+ (0.01,0) [0|655.32] "degK" Vector__XXX
 SG_ AirTemperature : 240|16@1+ (0.01,0) [0|655.32] "degK" Vector__XXX
 SG_ PressureTendencyRate : 224|16@1- (10,0) [-327.64|327.64] "Pa/hr" Vector__XXX
 SG_ AtmosphericPressure : 208|16@1+ (100,0) [0|6553200] "Pa" Vector__XXX
 SG_ DominantWavePeriod : 192|16@1+ (0.01,0) [0|655.32] "seconds" Vector__XXX
 SG_ WaveHeight : 176|16@1+ (0.01,0) [0|655.32] "m" Vector__XXX
 SG_ WindGusts : 160|16@1+ (0.01,0) [0|655.32] "m/s" Vector__XXX
 SG_ WindReference : 152|3@1+ (1,0) [0|0] " " Vector__XXX
 SG_ WindDirection : 136|16@1+ (0.01,0) [0|6.2831] "rad" Vector__XXX
 SG_ WindSpeed : 120|16@1+ (0.01,0) [0|655.32] "m/s" Vector__XXX
 SG_ StationLocationLongitude : 88|32@1- (1E-007,0) [-180|180] "degrees" Vector__XXX
 SG_ StationLocationLatitude : 56|32@1- (1E-007,0) [-90|90] "degrees" Vector__XXX
 SG_ MeasurementTime : 24|32@1+ (0.0001,0) [0|86401] "seconds" Vector__XXX
 SG_ MeasurementDate : 8|16@1+ (1,0) [0|65532] "days" Vector__XXX
 SG_ Mode : 0|4@1+ (1,0) [0|0] "" Vector__XXX

BO_ 2147613971 MeteorologicalStationData: 49 Vector__XXX
 SG_ AirTemperature : 192|16@1+ (0.01,0) [0|655.32] "degK" Vector__XXX
 SG_ AtmosphericPressure : 176|16@1+ (100,0) [0|6553200] "Pa" Vector__XXX
 SG_ WindGusts : 160|16@1+ (0.01,0) [0|655.32] "m/s" Vector__XXX
 SG_ WindReference : 152|3@1+ (1,0) [0|0] " " Vector__XXX
 SG_ WindDirection : 136|16@1+ (0.01,0) [0|6.2831] "rad" Vector__XXX
 SG_ WindSpeed : 120|16@1+ (0.01,0) [0|655.32] "m/s" Vector__XXX
 SG_ StationLocationLongitude : 88|32@1- (1E-007,0) [-180|180] "degrees" Vector__XXX
 SG_ StationLocationLatitude : 56|32@1- (1E-007,0) [-90|90] "degrees" Vector__XXX
 SG_ MeasurementTime : 24|32@1+ (0.0001,0) [0|86401] "seconds" Vector__XXX
 SG_ MeasurementDate : 8|16@1+ (1,0) [0|65532] "days" Vector__XXX
 SG_ Mode : 0|4@1+ (1,0) [0|0] "" Vector__XXX

BO_ 2147613970 CurrentStationData: 48 Vector__XXX
 SG_ WaterTemperature : 184|16@1+ (0.01,0) [0|655.32] "degK" Vector__XXX
 SG_ CurrentFlowDirection : 168|16@1+ (0.0001,0) [0|6.2831] "rad" Vector__XXX
 SG_ CurrentSpeed : 152|16@1+ (0.01,0) [0|655.32] "m/s" Vector__XXX
 SG_ MeasurementDepth : 120|32@1+ (0.01,0) [0|429500] "m" Vector__XXX
 SG_ StationLocationLongitude : 88|32@1- (1E-007,0) [-180|180] "degrees" Vector__XXX
 SG_ StationLocationLatitude : 56|32@1- (1E-007,0) [-90|90] "degrees" Vector__XXX
 SG_ MeasurementTime : 24|32@1+ (0.0001,0) [0|86401] "seconds" Vector__XXX
 SG_ MeasurementDate : 8|16@1+ (1,0) [0|65532] "days" Vector__XXX
 SG_ State : 4|3@1+ (1,0) [0|0] "" Vector__XXX
 SG_ Mode : 0|4@1+ (1,0) [0|0] "" Vector__XXX

BO_ 2147613969 SalinityStationData: 44 Vector__XXX
 SG_ WaterTemperature : 152|16@1+ (0.01,0) [0|655.32] "degK" Vector__XXX
 SG_ Salinity : 120|32@1- (1,0) [0|0] "" Vector__XXX
 SG_ StationLocationLongitude : 88|32@1- (1E-007,0) [-180|180] "degrees" Vector__XXX
 SG_ StationLocationLatitude : 56|32@1- (1E-007,0) [-90|90] "degrees" Vector__XXX
 SG_ MeasurementTime : 24|32@1+ (0.0001,0) [0|86401] "seconds" Vector__XXX
 SG_ MeasurementDate : 8|16@1+ (1,0) [0|65532] "days" Vector__XXX
 SG_ Mode : 0|4@1+ (1,0) [0|0] "" Vector__XXX

BO_ 2147613968 TideStationData: 42 Vector__XXX
 SG_ TideLevelStandardDeviation : 136|16@1+ (0.01,0) [0|655.32] "m" Vector__XXX
 SG_ TideLevel : 120|16@1+ (0.001,0) [-32764|32764] "m" Vector__XXX
 SG_ StationLocationLongitude : 88|32@1- (1E-007,0) [-180|180] "degrees" Vector__XXX
 SG_ StationLocationLatitude : 56|32@1- (1E-007,0) [-90|90] "degrees" Vector__XXX
 SG_ MeasurementTime : 24|32@1+ (0.0001,0) [0|86401] "seconds" Vector__XXX
 SG_ MeasurementDate : 8|16@1+ (1,0) [0|65532] "days" Vector__XXX
 SG_ TideTendency : 4|2@1+ (1,0) [0|0] "" Vector__XXX
 SG_ Mode : 0|4@1+ (1,0) [0|0] "" Vector__XXX

BO_ 2147613962 UAISAlternateBinaryMessage: 8 Vector__XXX
 SG_ CommunicationsStateID : 32|2@1+ (1,0) [0|0] "" Vector__XXX
 SG_ ApplicationStatusBits : 11|21@1+ (1,0) [0|0] "" Vector__XXX
 SG_ RepeatIndicator : 8|3@1+ (1,0) [0|0] "" Vector__XXX
 SG_ MessageID : 0|8@1+ (1,0) [0|252] "" Vector__XXX

BO_ 2147613961 UAISVTSTargetMessage: 14 Vector__XXX
 SG_ TargetIDInternationMaritimeOrg : 80|32@1+ (1,0) [0|4294967292] "" Vector__XXX
 SG_ TargetIDMariMobileServiceID : 48|32@1+ (1,0) [0|4294967292] "" Vector__XXX
 SG_ SourceMariMobileServiceID : 16|32@1+ (1,0) [0|4294967292] "" Vector__XXX
 SG_ UAISSpareBitsA : 11|2@1+ (1,0) [0|0] "" Vector__XXX
 SG_ RepeatIndicator : 8|3@1+ (1,0) [0|0] "" Vector__XXX
 SG_ MessageID : 0|8@1+ (1,0) [0|252] "" Vector__XXX

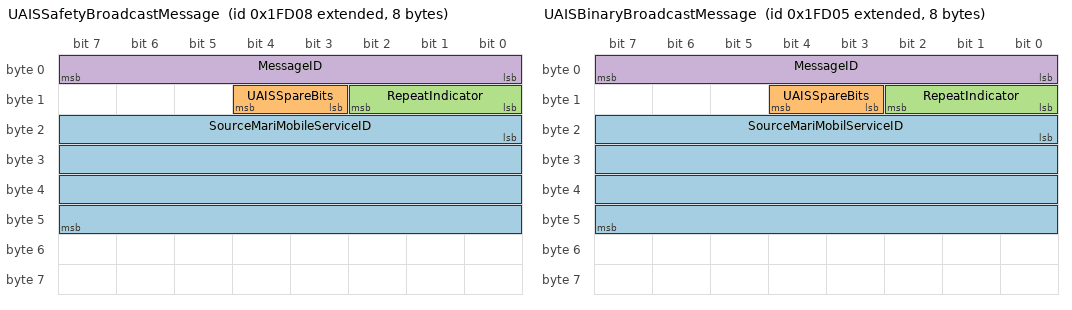
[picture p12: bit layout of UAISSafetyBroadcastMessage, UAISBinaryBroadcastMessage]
BO_ 2147613960 UAISSafetyBroadcastMessage: 8 Vector__XXX
 SG_ SourceMariMobileServiceID : 16|32@1+ (1,0) [0|4294967292] "" Vector__XXX
 SG_ UAISSpareBits : 11|2@1+ (1,0) [0|0] "" Vector__XXX
 SG_ RepeatIndicator : 8|3@1+ (1,0) [0|0] "" Vector__XXX
 SG_ MessageID : 0|8@1+ (1,0) [0|252] "" Vector__XXX

BO_ 2147613959 UAISAddressedSafetyTextMessage: 11 Vector__XXX
 SG_ DestinationMariMobileServiceID : 56|32@1+ (1,0) [0|0] "" Vector__XXX
 SG_ SequenceNumber : 48|8@1+ (1,0) [0|252] "" Vector__XXX
 SG_ SourceMariMobileServiceID : 16|32@1+ (1,0) [0|4294967292] "" Vector__XXX
 SG_ UAISSpareBits : 11|2@1+ (1,0) [0|0] "" Vector__XXX
 SG_ RepeatIndicator : 8|3@1+ (1,0) [0|0] "" Vector__XXX
 SG_ MessageID : 0|8@1+ (1,0) [0|252] "" Vector__XXX

BO_ 2147613958 EnvironmentalParameters: 8 Vector__XXX
 SG_ AtmosphericPressure : 40|16@1+ (100,0) [0|6553200] "Pa" Vector__XXX
 SG_ OutsideAmbientAirTemp : 24|16@1+ (0.01,0) [0|655.32] "degK" Vector__XXX
 SG_ WaterTemperature : 8|16@1+ (0.01,0) [0|655.32] "degK" Vector__XXX
 SG_ SID : 0|8@1+ (1,0) [0|252] "" Vector__XXX

BO_ 2147613957 UAISBinaryBroadcastMessage: 8 Vector__XXX
 SG_ SourceMariMobilServiceID : 16|32@1+ (1,0) [0|4294967292] "" Vector__XXX
 SG_ UAISSpareBits : 11|2@1+ (1,0) [0|0] "" Vector__XXX
 SG_ RepeatIndicator : 8|3@1+ (1,0) [0|0] "" Vector__XXX
 SG_ MessageID : 0|8@1+ (1,0) [0|252] "" Vector__XXX

BO_ 2147613956 UAISAdressedBinaryMessage: 11 Vector__XXX
 SG_ DestinationMariMobileServiceID : 56|32@1+ (1,0) [0|0] "" Vector__XXX
 SG_ SequenceID : 48|8@1+ (1,0) [0|252] "" Vector__XXX
 SG_ SouceMariMobileServiceID : 16|32@1+ (1,0) [0|0] "" Vector__XXX
 SG_ UAISSpareBits : 11|2@1+ (1,0) [0|0] "" Vector__XXX
 SG_ RepeatIndicator : 8|3@1+ (1,0) [0|0] "" Vector__XXX
 SG_ MessageID : 0|8@1+ (1,0) [0|0] "" Vector__XXX

BO_ 2147613955 UAISShipStaticVoyageInformation: 17 Vector__XXX
 SG_ ShipCallSignal7 : 128|8@1+ (1,0) [0|0] "" Vector__XXX
 SG_ ShipCallSignal6 : 120|8@1+ (1,0) [0|0] "" Vector__XXX
 SG_ ShipCallSignal5 : 112|8@1+ (1,0) [0|0] "" Vector__XXX
 SG_ ShipCallSignal4 : 104|8@1+ (1,0) [0|0] "" Vector__XXX
 SG_ ShipCallSignal3 : 96|8@1+ (1,0) [0|0] "" Vector__XXX
 SG_ ShipCallSignal2 : 88|8@1+ (1,0) [0|0] "" Vector__XXX
 SG_ ShipCallSignal1 : 80|8@1+ (1,0) [0|0] "" Vector__XXX
 SG_ InternationlMaritimeOrgNumber : 48|32@1+ (1,0) [0|4294967292] "" Vector__XXX
 SG_ UAISSpareBits : 43|2@1+ (1,0) [0|0] "" Vector__XXX
 SG_ RepeatIndicator : 40|3@1+ (1,0) [0|0] "" Vector__XXX
 SG_ MaritimeMobileServiceIDNumber : 8|32@1+ (1,0) [0|4294967292] "" Vector__XXX
 SG_ MessageID : 0|8@1+ (1,0) [0|252] "" Vector__XXX

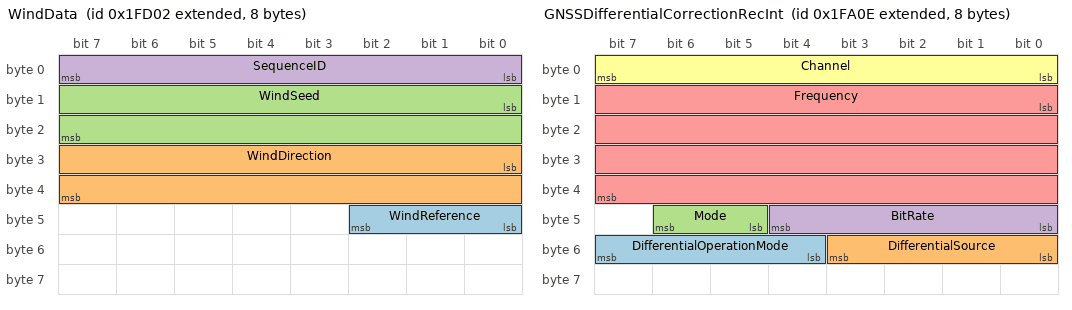
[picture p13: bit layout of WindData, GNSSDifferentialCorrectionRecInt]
BO_ 2147613954 WindData: 8 Vector__XXX
 SG_ WindReference : 40|3@1+ (1,0) [0|7] "" Vector__XXX
 SG_ WindDirection : 24|16@1+ (0.0001,0) [0|6.2831] "rad" Vector__XXX
 SG_ WindSeed : 8|16@1+ (0.01,0) [0|655.32] "m/s" Vector__XXX
 SG_ SequenceID : 0|8@1+ (1,0) [0|252] "" Vector__XXX

BO_ 2147613702 LoranCSignalData: 15 Vector__XXX
 SG_ StationASF : 88|32@1- (1E-009,0) [-2.14|2.14] "seconds" Vector__XXX
 SG_ StationECD : 56|32@1- (1E-009,0) [-2.14|2.14] "seconds" Vector__XXX
 SG_ StationSNR : 40|16@1- (0.01,0) [-327.64|327.64] "dB" Vector__XXX
 SG_ StationIdentifier : 32|8@1+ (1,0) [0|0] "" Vector__XXX
 SG_ GroupRepetitionRate : 0|32@1- (1E-009,0) [-2.14|2.14] "seconds" Vector__XXX

BO_ 2147613701 LoranCRangeData: 32 Vector__XXX
 SG_ Mode : 248|4@1+ (1,0) [0|0] "" Vector__XXX
 SG_ StationStatusZ : 244|4@1+ (1,0) [0|0] "" Vector__XXX
 SG_ StationStatusY : 240|4@1+ (1,0) [0|0] "" Vector__XXX
 SG_ StationStatusX : 236|4@1+ (1,0) [0|0] "" Vector__XXX
 SG_ StationStatusW : 232|4@1+ (1,0) [0|0] "" Vector__XXX
 SG_ StationStatusV : 228|4@1+ (1,0) [0|0] "" Vector__XXX
 SG_ StationStatusMaster : 224|4@1+ (1,0) [0|0] "" Vector__XXX
 SG_ ZSecondaryRange : 192|32@1- (1E-009,0) [-2.14|2.14] "seconds" Vector__XXX
 SG_ YSecondaryRange : 160|32@1- (1E-009,0) [-2.14|2.14] "seconds" Vector__XXX
 SG_ XSecondaryRange : 128|32@1- (1E-009,0) [-2.14|2.14] "seconds" Vector__XXX
 SG_ WSecondaryRange : 96|32@1- (1E-009,0) [-2.14|2.14] "seconds" Vector__XXX
 SG_ VSecondaryRange : 64|32@1- (1E-009,0) [-2.14|2.14] "seconds" Vector__XXX
 SG_ MasterRange : 32|32@1- (1E-009,0) [-2.14|2.14] "seconds" Vector__XXX
 SG_ GroupRepetitionInterval : 0|32@1- (1E-009,0) [-2.14|2.14] "seconds" Vector__XXX

BO_ 2147613700 LoranCTDData: 32 Vector__XXX
 SG_ Mode : 248|4@1+ (1,0) [0|0] "" Vector__XXX
 SG_ StationStatusZ : 244|4@1+ (1,0) [0|0] "" Vector__XXX
 SG_ StationStatusY : 240|4@1+ (1,0) [0|0] "" Vector__XXX
 SG_ StationStatusX : 236|4@1+ (1,0) [0|0] "" Vector__XXX
 SG_ StationStatusW : 232|4@1+ (1,0) [0|0] "" Vector__XXX
 SG_ StationStatusV : 228|4@1+ (1,0) [0|0] "" Vector__XXX
 SG_ StationStatusMaster : 224|4@1+ (1,0) [0|0] "" Vector__XXX
 SG_ ZSecondaryTD : 192|32@1- (1E-009,0) [-2.14|2.14] "seconds" Vector__XXX
 SG_ YSecondaryTD : 160|32@1- (1E-009,0) [-2.14|2.14] "seconds" Vector__XXX
 SG_ XSecondaryTD : 128|32@1- (1E-009,0) [-2.14|2.14] "seconds" Vector__XXX
 SG_ WSecondaryTD : 96|32@1- (1E-009,0) [-2.14|2.14] "seconds" Vector__XXX
 SG_ VSecondaryTD : 64|32@1- (1E-009,0) [-2.14|2.14] "seconds" Vector__XXX
 SG_ MasterRange : 32|32@1- (1E-009,0) [-2.14|2.14] "seconds" Vector__XXX
 SG_ GroupRepetitionInterval : 0|32@1- (1E-009,0) [-2.14|2.14] "seconds" Vector__XXX

BO_ 2147613456 DSCCallInformation: 21 Vector__XXX
 SG_ ProposedTxFrequencyChannel6 : 160|8@1+ (1,0) [0|0] "" Vector__XXX
 SG_ ProposedTxFrequencyChannel5 : 152|8@1+ (1,0) [0|0] "" Vector__XXX
 SG_ ProposedTxFrequencyChannel4 : 144|8@1+ (1,0) [0|0] "" Vector__XXX
 SG_ ProposedTxFrequencyChannel3 : 136|8@1+ (1,0) [0|0] "" Vector__XXX
 SG_ ProposedTxFrequencyChannel2 : 128|8@1+ (1,0) [0|0] "" Vector__XXX
 SG_ ProposedTxFrequencyChannel1 : 120|8@1+ (1,0) [0|0] "" Vector__XXX
 SG_ ProposedRxFrequencyChannel6 : 112|8@1+ (1,0) [0|0] "" Vector__XXX
 SG_ ProposedRxFrequencyChannel5 : 104|8@1+ (1,0) [0|0] "" Vector__XXX
 SG_ ProposedRxFrequencyChannel4 : 96|8@1+ (1,0) [0|0] "" Vector__XXX
 SG_ ProposedRxFrequencyChannel3 : 88|8@1+ (1,0) [0|0] "" Vector__XXX
 SG_ ProposedRxFrequencyChannel2 : 80|8@1+ (1,0) [0|0] "" Vector__XXX
 SG_ ProposedRxFrequencyChannel1 : 72|8@1+ (1,0) [0|0] "" Vector__XXX
 SG_ SubsequentCommunicationMode : 64|8@1+ (1,0) [0|0] "" Vector__XXX
 SG_ NatureOfDistress : 56|8@1+ (1,0) [0|0] "" Vector__XXX
 SG_ DSCMessageAddress5 : 48|8@1+ (1,0) [0|0] "" Vector__XXX
 SG_ DSCMessageAddress4 : 40|8@1+ (1,0) [0|0] "" Vector__XXX
 SG_ DSCMessageAddress3 : 32|8@1+ (1,0) [0|0] "" Vector__XXX
 SG_ DSCMessageAddress2 : 24|8@1+ (1,0) [0|0] "" Vector__XXX
 SG_ DSCMessageAddress1 : 16|8@1+ (1,0) [0|0] "" Vector__XXX
 SG_ DSCCategorySymbol : 8|8@1+ (1,0) [0|0] "" Vector__XXX
 SG_ DSCFormatSymbol : 0|8@1+ (1,0) [0|0] "" Vector__XXX

BO_ 2147613447 RadioFrequency: 19 Vector__XXX
 SG_ ChannelBandwidth : 136|16@1+ (1,0) [0|65532] "Hz" Vector__XXX
 SG_ Mode : 128|8@1+ (1,0) [0|0] "" Vector__XXX
 SG_ TxPower : 112|16@1+ (1,0) [0|65532] "Watts" Vector__XXX
 SG_ RadioChannel6 : 104|8@1+ (1,0) [0|0] "Hz" Vector__XXX
 SG_ RadioChannel5 : 96|8@1+ (1,0) [0|0] "Hz" Vector__XXX
 SG_ RadioChannel4 : 88|8@1+ (1,0) [0|0] "Hz" Vector__XXX
 SG_ RadioChannel3 : 80|8@1+ (1,0) [0|0] "Hz" Vector__XXX
 SG_ RadioChannel2 : 72|8@1+ (1,0) [0|0] "Hz" Vector__XXX
 SG_ RadioChannel1 : 64|8@1+ (1,0) [0|0] "Hz" Vector__XXX
 SG_ TxFrequency : 32|32@1+ (10,0) [0|327040] "Hz" Vector__XXX
 SG_ RxFrequency : 0|32@1+ (10,0) [0|327040] "Hz" Vector__XXX

BO_ 2147613204 GLONASSAlmanacData: 26 Vector__XXX
 SG_ tnAtau : 196|12@1+ (1,0) [0|0] "" Vector__XXX
 SG_ tcA : 168|28@1+ (1,0) [0|0] "" Vector__XXX
 SG_ inADelta : 144|24@1+ (1,0) [0|0] "" Vector__XXX
 SG_ nALambda : 120|24@1+ (1,0) [0|0] "" Vector__XXX
 SG_ tnA : 96|24@1+ (1,0) [0|0] "" Vector__XXX
 SG_ TnADelta : 72|24@1+ (1,0) [0|0] "" Vector__XXX
 SG_ nAOmega : 56|16@1+ (1,0) [0|0] "" Vector__XXX
 SG_ DOTDeltaTnA : 48|8@1+ (1,0) [0|0] "" Vector__XXX
 SG_ nAEpsilon : 32|16@1+ (1,0) [0|0] "" Vector__XXX
 SG_ HnA : 27|5@1+ (1,0) [0|0] "" Vector__XXX
 SG_ CnA : 26|1@1+ (1,0) [0|0] "" Vector__XXX
 SG_ NA : 8|16@1+ (1,0) [0|65532] "" Vector__XXX
 SG_ PRN : 0|8@1+ (1,0) [0|252] "" Vector__XXX

BO_ 2147613199 GNSSDiffCorrReceiverSignal: 20 Vector__XXX
 SG_ SatelliteServiceIDNumber : 144|16@1+ (1,0) [0|0] "" Vector__XXX
 SG_ TimeSinceLastSatDiffSync : 128|16@1+ (0.01,0) [0|655.32] "seconds" Vector__XXX
 SG_ DifferentialSource : 124|4@1+ (1,0) [0|0] "" Vector__XXX
 SG_ UsedAsCorrectionSource : 120|2@1+ (1,0) [0|0] "" Vector__XXX
 SG_ BitRate : 112|5@1+ (1,0) [0|0] "" Vector__XXX
 SG_ StationID : 100|12@1+ (1,0) [0|0] "" Vector__XXX
 SG_ StationType : 96|4@1+ (1,0) [0|0] "" Vector__XXX
 SG_ Frequency : 64|32@1- (10,0) [0|327040] "Hz" Vector__XXX
 SG_ SignalSNR : 48|16@1- (0.01,0) [-327.64|327.64] "dB" Vector__XXX
 SG_ SignalStrength : 16|32@1- (0.01,0) [-327.64|327.64] "uV/m" Vector__XXX
 SG_ Channel : 8|8@1+ (1,0) [0|252] "" Vector__XXX
 SG_ SID : 0|8@1+ (1,0) [0|252] "" Vector__XXX

BO_ 2147613198 GNSSDifferentialCorrectionRecInt: 8 Vector__XXX
 SG_ DifferentialOperationMode : 52|4@1+ (1,0) [0|0] "" Vector__XXX
 SG_ DifferentialSource : 48|4@1+ (1,0) [0|0] "" Vector__XXX
 SG_ Mode : 45|2@1+ (1,0) [0|0] "" Vector__XXX
 SG_ BitRate : 40|5@1+ (1,0) [0|0] "" Vector__XXX
 SG_ Frequency : 8|32@1+ (1,0) [0|327040] "Hz" Vector__XXX
 SG_ Channel : 0|8@1+ (1,0) [0|252] "" Vector__XXX

BO_ 2147613197 DGNSSCorrections: 16 Vector__XXX
 SG_ IOD : 120|8@1+ (1,0) [0|252] "" Vector__XXX
 SG_ UDRE : 104|16@1+ (0.01,0) [0|655.32] "m" Vector__XXX
 SG_ RRC : 88|16@1+ (0.0001,0) [-3.2764|3.2764] "m/s" Vector__XXX
 SG_ PRC : 56|32@1+ (0.0001,0) [-214700|214700] "m" Vector__XXX
 SG_ SatelliteID : 48|8@1+ (1,0) [0|252] "" Vector__XXX
 SG_ StationHealth : 40|4@1+ (1,0) [0|15] "" Vector__XXX
 SG_ TimeOfCorrections : 24|16@1+ (0.1,0) [0|6553.2] "sec" Vector__XXX
 SG_ ReferenceStationType : 20|4@1+ (1,0) [0|15] "" Vector__XXX
 SG_ ReferenceStationID : 8|12@1+ (1,0) [0|0] "" Vector__XXX
 SG_ SequenceID : 0|8@1+ (1,0) [0|252] "" Vector__XXX

BO_ 2147613195 GNSSPseudorangeErrorStatistic: 15 Vector__XXX
 SG_ StdDevAltitudeError : 104|16@1+ (0.01,0) [0|655.32] "m" Vector__XXX
 SG_ StdDevLongitudeError : 88|16@1+ (0.01,0) [0|655.32] "m" Vector__XXX
 SG_ StdDevLatitudeError : 72|16@1+ (0.01,0) [0|655.32] "m" Vector__XXX
 SG_ OrientationOfErrorEllipse : 56|16@1+ (0.0001,0) [0|6.2831] "rad" Vector__XXX
 SG_ StdDevMinorErrorEllipse : 40|16@1+ (0.01,0) [0|655.32] "m" Vector__XXX
 SG_ StdDevMajorErrorEllipse : 24|16@1+ (0.01,0) [0|655.32] "m" Vector__XXX
 SG_ RmsStdDevOfRangeInputs : 8|16@1+ (0.01,0) [0|655.32] "m" Vector__XXX
 SG_ SequenceID : 0|8@1+ (1,0) [0|252] "" Vector__XXX

BO_ 2147613194 GNSSRAIMSettings: 8 Vector__XXX
 SG_ PseudorangeResidualFilteringTime : 32|16@1+ (1,0) [0|65532] "sec" Vector__XXX
 SG_ ProbabilityOfMissedDetection : 24|8@1- (1,0) [-124|124] "%" Vector__XXX
 SG_ ProbabilityOfFalseAlarm : 16|8@1- (1,0) [-124|124] "%" Vector__XXX
 SG_ RadialPositionErrorMaxThresshold : 0|16@1+ (0.01,0) [0|655.32] "m" Vector__XXX

BO_ 2147613193 GNSSRAIMOutput: 13 Vector__XXX
 SG_ StdDeviationOfBias : 88|16@1+ (0.01,0) [-327.64|327.64] "m" Vector__XXX
 SG_ EstimateOfPseudorangeBias : 72|16@1+ (0.01,0) [-327.64|327.64] "m" Vector__XXX
 SG_ ProbatilityOfMissedDetection : 56|16@1+ (0.01,0) [-327.64|327.64] "m" Vector__XXX
 SG_ SVIDofMostLikelyFailedSat : 48|8@1+ (1,0) [0|252] "" Vector__XXX
 SG_ AltitudeExpectedError : 32|16@1+ (0.01,0) [-327.64|327.64] "m" Vector__XXX
 SG_ LatitudeExpectedError : 16|16@1+ (0.01,0) [-327.64|327.64] "m" Vector__XXX
 SG_ LatitudeExpectedError : 10|6@1+ (1,0) [0|0] "" Vector__XXX
 SG_ IntegrityFlag : 8|2@1+ (1,0) [0|3] "" Vector__XXX
 SG_ SequenceID : 0|8@1+ (1,0) [0|252] "" Vector__XXX

BO_ 2147613190 GNSSPseudorangeNoiseStatistics: 15 Vector__XXX
 SG_ STDAltitudeError : 104|16@1+ (0.01,0) [0|655.32] "m" Vector__XXX
 SG_ STDLongitudeError : 88|16@1+ (0.01,0) [0|655.32] "m" Vector__XXX
 SG_ STDLatitudeError : 72|16@1+ (0.01,0) [0|655.32] "m" Vector__XXX
 SG_ OrientationMajorAxis : 56|16@1+ (0.0001,0) [0|6.2831] "rad" Vector__XXX
 SG_ STDMinorAxis : 40|16@1+ (0.01,0) [0|655.32] "m" Vector__XXX
 SG_ STDMajorAxis : 24|16@1+ (0.01,0) [0|655.32] "m" Vector__XXX
 SG_ RMSOfPositionUncertainty : 8|16@1+ (0.01,0) [0|655.32] "m" Vector__XXX
 SG_ SID : 0|8@1+ (1,0) [0|252] "" Vector__XXX

BO_ 2147613189 GPSAlmanacData: 26 Vector__XXX
 SG_ ClockParameter2 : 195|11@1+ (1,0) [0|0] "" Vector__XXX
 SG_ ClockParameter1 : 184|11@1+ (1,0) [0|0] "" Vector__XXX
 SG_ MeanAnomaly : 160|24@1+ (1,0) [0|0] "" Vector__XXX
 SG_ LongitudeOfAscensionNode : 136|24@1+ (1,0) [0|0] "" Vector__XXX
 SG_ ArgumentOfPerigee : 112|24@1+ (1,0) [0|0] "" Vector__XXX
 SG_ RootSemiMajorAxis : 88|24@1+ (1,0) [0|0] "" Vector__XXX
 SG_ RateOfRightAscension : 72|16@1+ (1,0) [0|0] "" Vector__XXX
 SG_ InclinationAngle : 56|16@1+ (1,0) [0|0] "" Vector__XXX
 SG_ AlmanacReferenceTime : 48|8@1+ (1,0) [0|0] "" Vector__XXX
 SG_ Eccentricity : 32|16@1+ (1,0) [0|0] "" Vector__XXX
 SG_ SVHealthBits : 24|8@1+ (1,0) [0|0] "" Vector__XXX
 SG_ GPSWeekNumber : 8|16@1+ (1,0) [0|65532] "" Vector__XXX
 SG_ PRN : 0|8@1+ (1,0) [0|252] "" Vector__XXX

BO_ 2147613188 GNNSSatsInView: 24 Vector__XXX
 SG_ PNRStatus2 : 160|4@1+ (1,0) [0|0] "" Vector__XXX
 SG_ SNR2 : 144|16@1- (0.01,0) [-327.64|327.64] "dB" Vector__XXX
 SG_ Azimuth2 : 128|16@1+ (0.0001,0) [0|6.283] "rad" Vector__XXX
 SG_ Elevation2 : 112|16@1- (0.0001,0) [-3.14159|3.14159] "rad" Vector__XXX
 SG_ PRN2 : 104|8@1+ (1,0) [0|252] "" Vector__XXX
 SG_ PNRStatus1 : 96|4@1+ (1,0) [0|0] "" Vector__XXX
 SG_ RangeResiduals1 : 80|16@1+ (1E-005,0) [-21470|21470] "m" Vector__XXX
 SG_ SNR1 : 64|16@1- (0.01,0) [-327.64|327.64] "dB" Vector__XXX
 SG_ Azimuth1 : 48|16@1+ (0.0001,0) [0|6.283] "rad" Vector__XXX
 SG_ Elevation1 : 32|16@1- (0.0001,0) [-3.14159|3.14159] "rad" Vector__XXX
 SG_ NumberOfSVs : 16|8@1+ (1,0) [0|252] "" Vector__XXX
 SG_ Mode : 8|2@1+ (1,0) [0|3] "" Vector__XXX
 SG_ SID : 0|8@1+ (1,0) [0|250] "" Vector__XXX

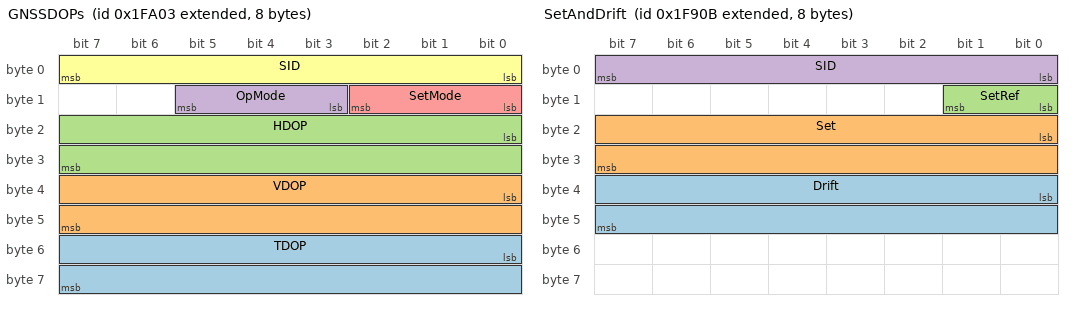
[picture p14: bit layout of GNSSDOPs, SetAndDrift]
BO_ 2147613187 GNSSDOPs: 8 Vector__XXX
 SG_ TDOP : 48|16@1- (0.01,0) [-327.64|327.64] "" Vector__XXX
 SG_ VDOP : 32|16@1- (0.01,0) [-327.64|327.64] "" Vector__XXX
 SG_ HDOP : 16|16@1- (0.01,0) [-327.64|327.64] "" Vector__XXX
 SG_ OpMode : 11|3@1+ (1,0) [0|0] "" Vector__XXX
 SG_ SetMode : 8|3@1+ (1,0) [0|0] "" Vector__XXX
 SG_ SID : 0|8@1+ (1,0) [0|250] "" Vector__XXX

BO_ 2147613186 GNNSControlStatus: 16 Vector__XXX
 SG_ UseAntennaAltitudeFor2DMode : 120|2@1+ (1,0) [0|3] "" Vector__XXX
 SG_ AntennaAltitudeFor2DMode : 88|32@1- (0.01,0) [-21470000|21470000] "m" Vector__XXX
 SG_ MaxCorrectionAge : 72|16@1+ (0.01,0) [0|655.32] "seconds" Vector__XXX
 SG_ PositionVelocityFilter : 70|2@1+ (1,0) [0|0] "" Vector__XXX
 SG_ DGNSSMode : 67|3@1+ (1,0) [0|0] "" Vector__XXX
 SG_ GNNSMode : 64|3@1+ (1,0) [0|0] "" Vector__XXX
 SG_ SNRMask : 48|16@1- (0.01,0) [-327.64|327.64] "dB" Vector__XXX
 SG_ PDOPSwitch : 32|16@1- (0.01,0) [-327.64|327.64] "" Vector__XXX
 SG_ PDOPMask : 16|16@1- (0.01,0) [-327.64|327.64] "" Vector__XXX
 SG_ SVElevation : 0|16@1- (0.0001,0) [-6.2831|6.2831] "rad" Vector__XXX

BO_ 2147612950 BearingAndDistanceBetweenMarks: 17 Vector__XXX
 SG_ DestinationMarkId : 104|32@1+ (1,0) [0|4294967292] "" Vector__XXX
 SG_ OriginMarkId : 72|32@1+ (1,0) [0|4294967292] "" Vector__XXX
 SG_ DestinationMarkType : 68|4@1+ (1,0) [0|15] "" Vector__XXX
 SG_ OriginMarkType : 64|4@1+ (1,0) [0|15] "" Vector__XXX
 SG_ Distance : 32|32@1+ (0.01,0) [0|429500000] "" Vector__XXX
 SG_ Bearing_OrigToDest : 16|16@1+ (0.0001,0) [0|6.2831] "rad" Vector__XXX
 SG_ CalculationType : 10|2@1- (1,0) [0|0] "" Vector__XXX
 SG_ BearingRef : 8|2@1+ (1,0) [0|0] "" Vector__XXX
 SG_ SID : 0|8@1+ (1,0) [0|250] "" Vector__XXX

BO_ 2147612949 TimeToFromMark: 10 Vector__XXX
 SG_ MarkID : 48|32@1+ (1,0) [0|4294967292] "" Vector__XXX
 SG_ MarkType : 40|4@1+ (1,0) [0|0] "" Vector__XXX
 SG_ TimeElapsed : 8|32@1- (0.001,0) [0|2148000] "seconds" Vector__XXX
 SG_ SID : 0|8@1+ (1,0) [0|252] "" Vector__XXX

BO_ 2147612939 SetAndDrift: 8 Vector__XXX
 SG_ Drift : 32|16@1+ (0.01,0) [0|655.32] "m/s" Vector__XXX
 SG_ Set : 16|16@1+ (0.0001,0) [0|6.2831] "rad" Vector__XXX
 SG_ SetRef : 8|2@1+ (1,0) [0|0] "" Vector__XXX
 SG_ SID : 0|8@1+ (1,0) [0|252] "" Vector__XXX

BO_ 2147612932 NavigationData: 34 Vector__XXX
 SG_ WaypointClosingVelocity : 256|16@1+ (0.01,0) [0|655.32] "m/s" Vector__XXX
 SG_ DestWaypointLongitude : 224|32@1- (1E-007,0) [-180|180] "deg" Vector__XXX
 SG_ DestWaypointLatitude : 192|32@1- (1E-007,0) [-90|90] "deg" Vector__XXX
 SG_ DestWaypointNumber : 160|32@1+ (1,0) [0|2704] "" Vector__XXX
 SG_ OrigWaypointNumber : 128|32@1+ (1,0) [0|2704] "" Vector__XXX
 SG_ Bearing_PosToDest : 112|16@1+ (0.0001,0) [0|6.2831] "rad" Vector__XXX
 SG_ Bearing_OrigToDest : 96|16@1+ (0.0001,0) [0|6.2831] "rad" Vector__XXX
 SG_ ETADate : 80|16@1+ (1,0) [0|65532] "days" Vector__XXX
 SG_ ETA_Time : 48|32@1+ (0.0001,0) [0|86401] "seconds" Vector__XXX
 SG_ CalculationType : 46|2@1+ (1,0) [0|0] "" Vector__XXX
 SG_ ArrivalCircleEnterd : 44|2@1+ (1,0) [0|0] "" Vector__XXX
 SG_ PerpendCrossed : 42|2@1+ (1,0) [0|0] "" Vector__XXX
 SG_ CourseBearingRef : 40|2@1+ (1,0) [0|0] "" Vector__XXX
 SG_ DistanceToDestWaypoint : 8|32@1+ (0.01,0) [0|429500] "m" Vector__XXX
 SG_ SID : 0|8@1+ (1,0) [0|252] "" Vector__XXX

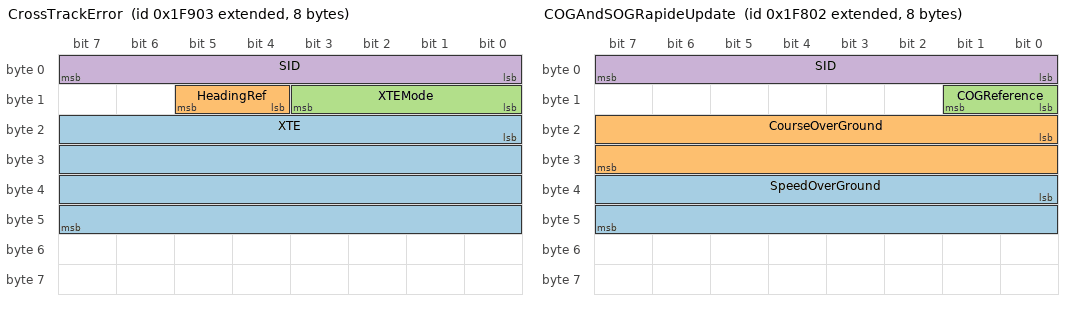
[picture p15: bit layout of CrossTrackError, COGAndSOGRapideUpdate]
BO_ 2147612931 CrossTrackError: 8 Vector__XXX
 SG_ XTE : 16|32@1- (0.01,0) [-21470000|21470000] "m" Vector__XXX
 SG_ HeadingRef : 12|2@1+ (1,0) [0|0] "" Vector__XXX
 SG_ XTEMode : 8|4@1+ (1,0) [0|0] "" Vector__XXX
 SG_ SID : 0|8@1+ (1,0) [0|252] "" Vector__XXX

BO_ 2147612693 UserDatumSettings: 40 Vector__XXX
 SG_ DatumName : 288|32@1+ (1,0) [0|0] "" Vector__XXX
 SG_ EllipsoidFlateningInverse : 256|32@1- (0.01,0) [0|0] "m" Vector__XXX
 SG_ EllipsoidSemiMajorAxis : 224|32@1- (1,0) [-21470000|21470000] "" Vector__XXX
 SG_ Scale : 192|32@1- (1,0) [0|0] "" Vector__XXX
 SG_ RotationZ : 160|32@1- (1,0) [0|0] "rad" Vector__XXX
 SG_ RotationY : 128|32@1- (1,0) [0|0] "rad" Vector__XXX
 SG_ RotationX : 96|32@1- (1,0) [0|0] "rad" Vector__XXX
 SG_ DeltaZ : 64|32@1- (0.01,0) [-21470000|21470000] "m" Vector__XXX
 SG_ DeltaY : 32|32@1- (0.01,0) [-21470000|21470000] "m" Vector__XXX
 SG_ DeltaX : 0|32@1- (0.01,0) [-21470000|21470000] "m" Vector__XXX

BO_ 2147612692 Datum: 20 Vector__XXX
 SG_ ReferenceDatum : 128|32@1- (1,0) [0|0] " " Vector__XXX
 SG_ DeltaAltitude : 96|32@1- (0.01,0) [-21470000|21470000] "m" Vector__XXX
 SG_ DeltaLongitude : 64|32@1- (1E-007,0) [-180|180] "deg" Vector__XXX
 SG_ DeltaLatitude : 32|32@1- (1E-007,0) [-90|90] "deg" Vector__XXX
 SG_ LocalDatum : 0|32@1+ (1,0) [0|0] "" Vector__XXX

BO_ 2147612681 TimeAndDate: 8 Vector__XXX
 SG_ LocalOffsetMinutes : 48|16@1- (1,0) [-32764|32764] "minutes" Vector__XXX
 SG_ TimeOfDay : 16|32@1+ (0.0001,0) [0|86401] "seconds" Vector__XXX
 SG_ Date : 0|16@1+ (1,0) [0|65532] "day" Vector__XXX

BO_ 2147612677 GNNSPositionData: 51 Vector__XXX
 SG_ AgeOfDGNSSRefStation2 : 392|16@1+ (0.01,0) [0|655.32] "seconds" Vector__XXX
 SG_ RefStationId2 : 380|12@1+ (1,0) [0|0] "" Vector__XXX
 SG_ RefStationType2 : 376|4@1+ (1,0) [0|0] "" Vector__XXX
 SG_ AgeOfDGNSSRefStation1 : 360|16@1+ (0.01,0) [0|655.32] "seconds" Vector__XXX
 SG_ RefStationId1 : 348|12@1+ (1,0) [0|0] "" Vector__XXX
 SG_ RefStationType1 : 344|4@1+ (1,0) [0|0] "" Vector__XXX
 SG_ NumberOfReferenceStations : 336|8@1+ (1,0) [0|252] "" Vector__XXX
 SG_ GeoidalSeparation : 304|32@1- (0.01,0) [-21470000|21470000] "m" Vector__XXX
 SG_ PDOP : 288|16@1- (0.01,0) [-327.64|327.64] "" Vector__XXX
 SG_ HDOP : 272|16@1- (0.01,0) [-327.64|327.64] "" Vector__XXX
 SG_ NumberOfSVs : 264|8@1+ (1,0) [0|252] "" Vector__XXX
 SG_ GNSSIntegrity : 256|2@1+ (1,0) [0|3] "" Vector__XXX
 SG_ MethodGNSS : 252|4@1+ (1,0) [0|15] "" Vector__XXX
 SG_ TypeOfSystem : 248|4@1+ (1,0) [0|15] "" Vector__XXX
 SG_ AltitudeHigh : 216|32@1- (4294.967295,0) [-1705215488|1705215488] "m" Vector__XXX
 SG_ AltitudeLow : 184|32@1+ (1E-006,0) [0|4294] "m" Vector__XXX
 SG_ LongitudeHigh : 152|32@1- (4.29497E-007,0) [-180|180] "deg" Vector__XXX
 SG_ LatitudeLow : 56|32@1+ (1E-016,0) [0|4.294E-007] "deg" Vector__XXX
 SG_ LatitudeHigh : 88|32@1- (4.29497E-007,0) [-90|90] "deg" Vector__XXX
 SG_ LongitudeLow : 120|32@1+ (1E-016,0) [0|4.294E-007] "deg" Vector__XXX
 SG_ PositionTime : 24|32@1+ (0.0001,0) [0|86401] "seconds" Vector__XXX
 SG_ PositionDate : 8|16@1+ (1,0) [0|65532] "days" Vector__XXX
 SG_ SID : 0|8@1+ (1,0) [0|252] "" Vector__XXX

BO_ 2147612674 COGAndSOGRapideUpdate: 8 Vector__XXX
 SG_ SpeedOverGround : 32|16@1+ (0.01944,0) [0|1274.0004] "kts" Vector__XXX
 SG_ CourseOverGround : 16|16@1+ (0.00573,0) [0|375.51555] "deg" Vector__XXX
 SG_ COGReference : 8|2@1+ (1,0) [0|0] "" Vector__XXX
 SG_ SID : 0|8@1+ (1,0) [0|252] "" Vector__XXX

BO_ 2147612673 PositionRapidUpdate: 8 Vector__XXX
 SG_ Longitude : 32|32@1- (1E-007,0) [-180|180] "deg" Vector__XXX
 SG_ Latitude : 0|32@1- (1E-007,0) [-180|180] "deg" Vector__XXX

BO_ 2147612173 UAISUTCTimeAndDateReport: 24 Vector__XXX
 SG_ ChannelNumber : 176|16@1+ (1,0) [-32764|32764] "" Vector__XXX
 SG_ UAISSpareBits : 164|12@1+ (1,0) [0|0] "" Vector__XXX
 SG_ CommunicationState : 160|4@1+ (1,0) [0|0] "" Vector__XXX
 SG_ Latitude : 128|32@1- (1E-007,0) [-90|90] "deg" Vector__XXX
 SG_ Longitude : 96|32@1- (1E-007,0) [-180|180] "deg" Vector__XXX
 SG_ Date : 80|16@1+ (1,0) [0|65532] "day" Vector__XXX
 SG_ TimeOfDay : 48|32@1+ (0.0001,0) [0|86401] "seconds" Vector__XXX
 SG_ MaritimeMobileServiceIDNumber : 16|32@1+ (1,0) [0|4294967292] "" Vector__XXX
 SG_ PositionAccuracy : 15|1@1+ (1,0) [0|0] "" Vector__XXX
 SG_ RepeatIndicator : 12|3@1+ (1,0) [0|0] "" Vector__XXX
 SG_ ElectronicPositionFixingDevice : 8|4@1+ (1,0) [0|0] "" Vector__XXX
 SG_ MessageID : 0|8@1+ (1,0) [0|252] "" Vector__XXX

BO_ 2147612172 UAISPositionReport: 29 Vector__XXX
 SG_ ChannelNumber : 216|16@1- (1,0) [-32764|32764] "" Vector__XXX
 SG_ UAISReserveBits : 213|3@1+ (1,0) [0|0] "" Vector__XXX
 SG_ PositionalMode : 209|4@1+ (1,0) [0|0] "" Vector__XXX
 SG_ RepeatIndicator : 206|3@1+ (1,0) [0|0] "" Vector__XXX
 SG_ RegionalApplicationID : 202|4@1+ (1,0) [0|0] "" Vector__XXX
 SG_ CommunicationsState : 198|4@1+ (1,0) [0|0] "" Vector__XXX
 SG_ HeadingSource : 194|4@1+ (1,0) [0|0] "" Vector__XXX
 SG_ HeadingReference : 192|2@1+ (1,0) [0|0] "" Vector__XXX
 SG_ TimeOfDay : 160|32@1+ (0.0001,0) [0|86401] "seconds" Vector__XXX
 SG_ Heading : 144|16@1+ (0.0001,0) [0|6.2831] "rad" Vector__XXX
 SG_ CourseOverGround : 128|16@1+ (0.0001,0) [0|6.2831] "rad" Vector__XXX
 SG_ Latitude : 96|32@1- (1E-007,0) [-90|90] "deg" Vector__XXX
 SG_ Longitude : 64|32@1- (1E-007,0) [-180|180] "deg" Vector__XXX
 SG_ RateOfTurn : 48|16@1- (0.0003125,0) [-1|1] "rad/sec" Vector__XXX
 SG_ PositionAccuracy : 47|1@1+ (1,0) [0|0] "" Vector__XXX
 SG_ NavigationStatus : 44|3@1+ (1,0) [0|0] "" Vector__XXX
 SG_ DataAvailable : 42|2@1+ (1,0) [0|0] "" Vector__XXX
 SG_ DataTerminalEquipmentAvailable : 40|2@1+ (1,0) [0|0] "" Vector__XXX
 SG_ MaritimeMobileServiceIdNumber : 8|32@1+ (1,0) [0|4294967292] "" Vector__XXX
 SG_ MessageID : 0|8@1+ (1,0) [0|252] "" Vector__XXX

BO_ 2147612168 TrackedTargetData: 30 Vector__XXX
 SG_ ReferenceTarget : 224|16@1+ (1,0) [0|65532] "" Vector__XXX
 SG_ Name : 208|16@1+ (1,0) [0|65532] "" Vector__XXX
 SG_ UTCofFix : 176|32@1+ (0.0001,0) [0|65532] "" Vector__XXX
 SG_ TCPA : 144|32@1+ (0.001,0) [-2148000|2148000] "s" Vector__XXX
 SG_ CPA : 112|32@1+ (0.01,0) [-2.147|2.147] "m" Vector__XXX
 SG_ Speed : 96|16@1+ (0.01,0) [0|655.32] "m/s" Vector__XXX
 SG_ Course : 80|16@1+ (0.0001,0) [0|6.2831] "rad" Vector__XXX
 SG_ Distance : 48|32@1+ (0.01,0) [-21470000|21470000] "m" Vector__XXX
 SG_ Bearing : 32|16@1+ (0.0001,0) [0|6.2831] "rad" Vector__XXX
 SG_ BearingReference : 28|2@1+ (1,0) [0|3] "" Vector__XXX
 SG_ Acquision : 27|1@1+ (1,0) [0|0] "" Vector__XXX
 SG_ ReportedTarget : 26|1@1+ (1,0) [0|1] "" Vector__XXX
 SG_ TrackStatus : 24|2@1+ (1,0) [0|3] "" Vector__XXX
 SG_ TargetId : 8|16@1+ (1,0) [0|65532] "" Vector__XXX
 SG_ SequenceID : 0|8@1+ (1,0) [0|252] "" Vector__XXX

BO_ 2147611923 DistanceLog: 14 Vector__XXX
 SG_ DistanceSinceLastReset : 80|32@1+ (1,0) [0|32704] "m" Vector__XXX
 SG_ TotalCumulativeDistance : 48|32@1+ (1,0) [0|32704] "" Vector__XXX
 SG_ MeasurementTime : 16|32@1+ (0.0001,0) [0|86401] "s" Vector__XXX
 SG_ MeasurementDate : 0|16@1+ (1,0) [0|65532] "" Vector__XXX

BO_ 2147611915 WaterDepth: 8 Vector__XXX
 SG_ Offset : 40|16@1- (0.001,0) [-32.764|32.764] "m" Vector__XXX
 SG_ WaterDepthTransducer : 8|32@1+ (0.01,0) [0|429500] "m" Vector__XXX
 SG_ SID : 0|8@1+ (1,0) [0|252] "" Vector__XXX

BO_ 2147611907 Speed: 8 Vector__XXX
 SG_ SpeedGroundReferenced : 24|16@1+ (0.01,0) [0|655.32] "m/s" Vector__XXX
 SG_ SpeedWaterReferenced : 8|16@1+ (0.01,0) [0|655.32] "m/s" Vector__XXX
 SG_ SID : 0|8@1+ (1,0) [0|252] "" Vector__XXX

BO_ 2147611156 BatteryStatus: 8 Vector__XXX
 SG_ BatteryCaseTemp : 40|16@1+ (0.01,0) [0|655.32] "degK" Vector__XXX
 SG_ BatteryCurrent : 24|16@1- (0.1,0) [-3276.4|3276.4] "Amps" Vector__XXX
 SG_ BatteryPotential : 8|16@1- (0.1,0) [-327.64|327.64] "Volts" Vector__XXX
 SG_ BatteryInstance : 0|8@1+ (1,0) [0|252] "" Vector__XXX

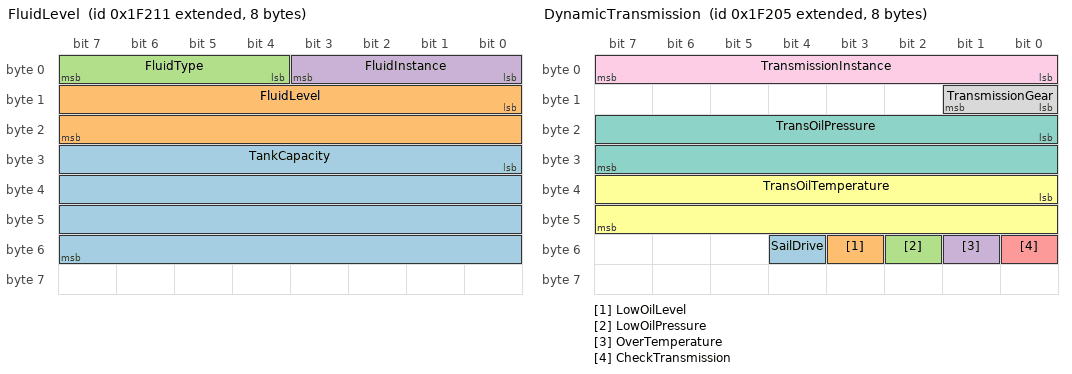
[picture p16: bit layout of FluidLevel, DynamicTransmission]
BO_ 2147611153 FluidLevel: 8 Vector__XXX
 SG_ TankCapacity : 24|32@1+ (0.0001,0) [0|0] "m3" Vector__XXX
 SG_ FluidLevel : 8|16@1+ (0.004,0) [-124|124] "%" Vector__XXX
 SG_ FluidType : 4|4@1+ (1,0) [0|15] "" Vector__XXX
 SG_ FluidInstance : 0|4@1+ (1,0) [0|15] "" Vector__XXX

BO_ 2147611150 SwitchBankControl: 8 Vector__XXX
 SG_ Switch28 : 62|2@1+ (1,0) [0|3] "" Vector__XXX
 SG_ Switch27 : 60|2@1+ (1,0) [0|3] "" Vector__XXX
 SG_ Switch26 : 58|2@1+ (1,0) [0|3] "" Vector__XXX
 SG_ Switch25 : 56|2@1+ (1,0) [0|3] "" Vector__XXX
 SG_ Switch24 : 54|2@1+ (1,0) [0|3] "" Vector__XXX
 SG_ Switch23 : 52|2@1+ (1,0) [0|3] "" Vector__XXX
 SG_ Switch22 : 50|2@1+ (1,0) [0|3] "" Vector__XXX
 SG_ Switch21 : 48|2@1+ (1,0) [0|3] "" Vector__XXX
 SG_ Switch20 : 46|2@1+ (1,0) [0|3] "" Vector__XXX
 SG_ Switch19 : 44|2@1+ (1,0) [0|3] "" Vector__XXX
 SG_ Switch18 : 42|2@1+ (1,0) [0|3] "" Vector__XXX
 SG_ Switch17 : 40|2@1+ (1,0) [0|3] "" Vector__XXX
 SG_ Switch16 : 38|2@1+ (1,0) [0|3] "" Vector__XXX
 SG_ Switch15 : 36|2@1+ (1,0) [0|3] "" Vector__XXX
 SG_ Switch14 : 34|2@1+ (1,0) [0|3] "" Vector__XXX
 SG_ Switch13 : 32|2@1+ (1,0) [0|3] "" Vector__XXX
 SG_ Switch12 : 30|2@1+ (1,0) [0|3] "" Vector__XXX
 SG_ Switch11 : 28|2@1+ (1,0) [0|3] "" Vector__XXX
 SG_ Switch10 : 26|2@1+ (1,0) [0|3] "" Vector__XXX
 SG_ Switch9 : 24|2@1+ (1,0) [0|3] "" Vector__XXX
 SG_ Switch8 : 22|2@1+ (1,0) [0|3] "" Vector__XXX
 SG_ Switch7 : 20|2@1+ (1,0) [0|3] "" Vector__XXX
 SG_ Switch6 : 18|2@1+ (1,0) [0|3] "" Vector__XXX
 SG_ Switch5 : 16|2@1+ (1,0) [0|3] "" Vector__XXX
 SG_ Switch4 : 14|2@1+ (1,0) [0|3] "" Vector__XXX
 SG_ Switch3 : 12|2@1+ (1,0) [0|3] "" Vector__XXX
 SG_ Switch2 : 10|2@1+ (1,0) [0|3] "" Vector__XXX
 SG_ Switch1 : 8|2@1+ (1,0) [0|3] "" Vector__XXX
 SG_ SwitchBankInstance : 0|8@1+ (1,0) [0|0] "" Vector__XXX

BO_ 2147611149 BinarySwitchBankStatus: 8 Vector__XXX
 SG_ Indicator28 : 62|2@1+ (1,0) [0|1] "" Vector__XXX
 SG_ Indicator27 : 60|2@1+ (1,0) [0|1] "" Vector__XXX
 SG_ Indicator26 : 58|2@1+ (1,0) [0|1] "" Vector__XXX
 SG_ Indicator25 : 56|2@1+ (1,0) [0|1] "" Vector__XXX
 SG_ Indicator24 : 54|2@1+ (1,0) [0|1] "" Vector__XXX
 SG_ Indicator23 : 52|2@1+ (1,0) [0|1] "" Vector__XXX
 SG_ Indicator22 : 50|2@1+ (1,0) [0|1] "" Vector__XXX
 SG_ Indicator21 : 48|2@1+ (1,0) [0|1] "" Vector__XXX
 SG_ Indicator20 : 46|2@1+ (1,0) [0|1] "" Vector__XXX
 SG_ Indicator19 : 44|2@1+ (1,0) [0|1] "" Vector__XXX
 SG_ Indicator18 : 42|2@1+ (1,0) [0|1] "" Vector__XXX
 SG_ Indicator17 : 40|2@1+ (1,0) [0|1] "" Vector__XXX
 SG_ Indicator16 : 38|2@1+ (1,0) [0|1] "" Vector__XXX
 SG_ Indicator15 : 36|2@1+ (1,0) [0|1] "" Vector__XXX
 SG_ Indicator14 : 34|2@1+ (1,0) [0|1] "" Vector__XXX
 SG_ Indicator13 : 32|2@1+ (1,0) [0|1] "" Vector__XXX
 SG_ Indicator12 : 30|2@1+ (1,0) [0|1] "" Vector__XXX
 SG_ Indicator11 : 28|2@1+ (1,0) [0|1] "" Vector__XXX
 SG_ Indicator10 : 26|2@1+ (1,0) [0|1] "" Vector__XXX
 SG_ Indicator9 : 24|2@1+ (1,0) [0|1] "" Vector__XXX
 SG_ Indicator8 : 22|2@1+ (1,0) [0|1] "" Vector__XXX
 SG_ Indicator7 : 20|2@1+ (1,0) [0|1] "" Vector__XXX
 SG_ Indicator6 : 18|2@1+ (1,0) [0|1] "" Vector__XXX
 SG_ Indicator5 : 16|2@1+ (1,0) [0|1] "" Vector__XXX
 SG_ Indicator4 : 14|2@1+ (1,0) [0|1] "" Vector__XXX
 SG_ Indicator3 : 12|2@1+ (1,0) [0|1] "" Vector__XXX
 SG_ Indicator2 : 10|2@1+ (1,0) [0|1] "" Vector__XXX
 SG_ Indicator1 : 8|2@1+ (1,0) [0|1] "" Vector__XXX
 SG_ IndicatorBankInstance : 0|8@1+ (1,0) [0|0] "" Vector__XXX

BO_ 2147611146 EngineParameters: 8 Vector__XXX
 SG_ VIN : 24|16@1+ (1,0) [0|0] "" Vector__XXX
 SG_ RatedEngineSpeed : 8|16@1+ (0.25,0) [0|16383] "rpm" Vector__XXX
 SG_ EngineInstance : 0|8@1+ (1,0) [0|255] "" Vector__XXX

BO_ 2147611145 TripParameters: 8 Vector__XXX
 SG_ TripFuelUsed : 40|16@1+ (0.001,0) [0|65.532] "cu m" Vector__XXX
 SG_ TripRunTime : 8|32@1+ (0.001,0) [0|4295000] "seconds" Vector__XXX
 SG_ EngineInstance : 0|8@1+ (1,0) [0|255] "" Vector__XXX

BO_ 2147611141 DynamicTransmission: 8 Vector__XXX
 SG_ SailDrive : 52|1@1+ (1,0) [0|1] "" Vector__XXX
 SG_ LowOilLevel : 51|1@1+ (1,0) [0|1] "" Vector__XXX
 SG_ LowOilPressure : 50|1@1+ (1,0) [0|1] "" Vector__XXX
 SG_ OverTemperature : 49|1@1+ (1,0) [0|1] "" Vector__XXX
 SG_ CheckTransmission : 48|1@1+ (1,0) [0|1] "" Vector__XXX
 SG_ TransOilTemperature : 32|16@1+ (0.1,0) [0|6553.2] "degK" Vector__XXX
 SG_ TransOilPressure : 16|16@1+ (100,0) [0|6553200] "Pa" Vector__XXX
 SG_ TransmissionGear : 8|2@1+ (1,0) [0|3] "" Vector__XXX
 SG_ TransmissionInstance : 0|8@1+ (1,0) [0|255] "" Vector__XXX

BO_ 2147611137 EngineParameterDynamic: 22 Vector__XXX
 SG_ EngineEmergencyStopMode : 175|1@1+ (1,0) [0|1] "" Vector__XXX
 SG_ ThrottlePositionSensor : 174|1@1+ (1,0) [0|1] "" Vector__XXX
 SG_ EGRSystem : 173|1@1+ (1,0) [0|1] "" Vector__XXX
 SG_ RevLimitExceeded : 172|1@1+ (1,0) [0|1] "" Vector__XXX
 SG_ HightBoostPressure : 171|1@1+ (1,0) [0|1] "" Vector__XXX
 SG_ PreheatIndicator : 170|1@1+ (1,0) [0|1] "" Vector__XXX
 SG_ ChargeIndicator : 169|1@1+ (1,0) [0|1] "" Vector__XXX
 SG_ WaterInFuel : 168|1@1+ (1,0) [0|1] "" Vector__XXX
 SG_ WaterFlow : 167|1@1+ (1,0) [0|1] "" Vector__XXX
 SG_ LowCoolantLevel : 166|1@1+ (1,0) [0|1] "" Vector__XXX
 SG_ LowSystemVoltage : 165|1@1+ (1,0) [0|1] "" Vector__XXX
 SG_ LowFuelPressure : 164|1@1+ (1,0) [0|1] "" Vector__XXX
 SG_ LowOilLevel : 163|1@1+ (1,0) [0|1] "" Vector__XXX
 SG_ LowOilPressure : 162|1@1+ (1,0) [0|1] "" Vector__XXX
 SG_ OverTemperature : 161|1@1+ (1,0) [0|1] "" Vector__XXX
 SG_ CheckEngine : 160|1@1+ (1,0) [0|1] "" Vector__XXX
 SG_ EngineTiltTrime : 152|8@1+ (1,0) [-124|124] "%" Vector__XXX
 SG_ FuelPressure : 136|16@1+ (100,0) [0|6553200] "Pa" Vector__XXX
 SG_ EngineCoolantPressure : 120|16@1+ (100,0) [0|6553200] "Pa" Vector__XXX
 SG_ TotalEngineHours : 88|32@1+ (1,0) [0|32704000] "seconds" Vector__XXX
 SG_ FuelRate : 72|16@1- (0.0001,0) [-3.2764|3.2764] "cu-m/hr" Vector__XXX
 SG_ AlternatorPotential : 56|16@1- (0.1,0) [-327.64|327.64] "Volts" Vector__XXX
 SG_ EngineCoolantTemp : 40|16@1+ (0.01,0) [0|655.32] "degK" Vector__XXX
 SG_ EngineOilTemp : 24|16@1+ (0.1,0) [0|6553.2] "degK" Vector__XXX
 SG_ EngineOilPressure : 8|16@1+ (100,0) [0|6553200] "Pa" Vector__XXX
 SG_ EngineInstance : 0|8@1+ (1,0) [0|255] "" Vector__XXX

BO_ 2147611136 EngineParametersRapidUpdate: 8 Vector__XXX
 SG_ EngineTiltTrim : 40|8@1- (1,0) [0|0] "%" Vector__XXX
 SG_ EngineBoostPressure : 24|16@1+ (100,0) [0|6553200] "Pa" Vector__XXX
 SG_ EngineSpeed : 8|16@1+ (0.25,0) [0|16383] "RPM" Vector__XXX
 SG_ EngineInstance : 0|8@1+ (1,0) [0|255] "" Vector__XXX

BO_ 2147610905 Attitude: 8 Vector__XXX
 SG_ Roll : 40|16@1- (0.00573,0) [-187.76064|187.75491] "deg" Vector__XXX
 SG_ Pitch : 24|16@1- (0.00573,0) [-187.76064|187.75491] "deg" Vector__XXX
 SG_ Yaw : 8|16@1+ (0.00573,0) [0|375.51555] "deg" Vector__XXX
 SG_ SID : 0|8@1+ (1,0) [0|250] "" Vector__XXX

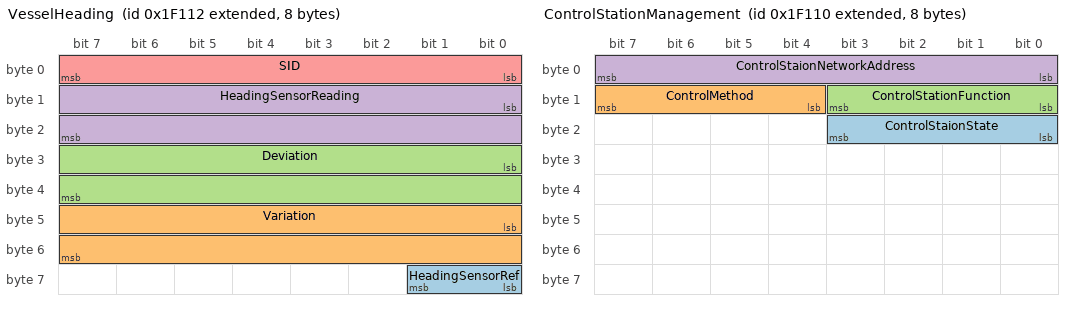
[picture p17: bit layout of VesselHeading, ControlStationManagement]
BO_ 2147610898 VesselHeading: 8 Vector__XXX
 SG_ HeadingSensorRef : 56|2@1+ (1,0) [0|3] "" Vector__XXX
 SG_ Variation : 40|16@1- (0.00573,0) [-187.76064|187.75491] "deg" Vector__XXX
 SG_ Deviation : 24|16@1- (0.00573,0) [-187.76064|187.75491] "deg" Vector__XXX
 SG_ HeadingSensorReading : 8|16@1+ (0.00573,0) [0|375.51555] "deg" Vector__XXX
 SG_ SID : 0|8@1+ (1,0) [0|252] "" Vector__XXX

BO_ 2147610896 ControlStationManagement: 8 Vector__XXX
 SG_ ControlStaionState : 16|4@1+ (1,0) [0|0] "" Vector__XXX
 SG_ ControlMethod : 12|4@1+ (1,0) [0|0] "" Vector__XXX
 SG_ ControlStationFunction : 8|4@1+ (1,0) [0|0] "" Vector__XXX
 SG_ ControlStaionNetworkAddress : 0|8@1+ (1,0) [0|0] "" Vector__XXX

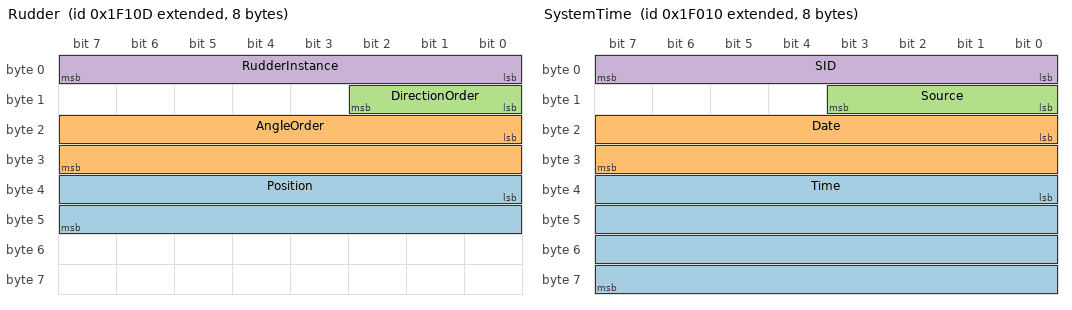
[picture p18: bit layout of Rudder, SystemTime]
BO_ 2147610893 Rudder: 8 Vector__XXX
 SG_ Position : 32|16@1- (0.0057296,0) [-50|50] "deg" Vector__XXX
 SG_ AngleOrder : 16|16@1- (0.0057296,0) [-50|50] "deg" Vector__XXX
 SG_ DirectionOrder : 8|3@1+ (1,0) [0|7] "" Vector__XXX
 SG_ RudderInstance : 0|8@1+ (1,0) [0|255] "" Vector__XXX

BO_ 2147610646 ConfigurationInformation: 38 Vector__XXX

BO_ 2147610644 ProductInformation: 134 Vector__XXX
 SG_ ProdInfo_SwVerCode_8 : 519|32@0- (1,0) [0|0] "" Vector__XXX
 SG_ ProdInfo_SwVerCode_7 : 487|32@0- (1,0) [0|0] "" Vector__XXX
 SG_ ProdInfo_SwVerCode_6 : 455|32@0- (1,0) [0|0] "" Vector__XXX
 SG_ ProdInfo_SwVerCode_5 : 423|32@0- (1,0) [0|0] "" Vector__XXX
 SG_ ProdInfo_SwVerCode_4 : 391|32@0- (1,0) [0|0] "" Vector__XXX
 SG_ ProdInfo_SwVerCode_3 : 359|32@0- (1,0) [0|0] "" Vector__XXX
 SG_ ProdInfo_SwVerCode_2 : 327|32@0- (1,0) [0|0] "" Vector__XXX
 SG_ ProdInfo_SwVerCode_1 : 295|32@0- (1,0) [0|0] "" Vector__XXX
 SG_ ProdInfo_SerialNum_8 : 1031|32@0- (1,0) [0|0] "" Vector__XXX
 SG_ ProdInfo_SerialNum_7 : 999|32@0- (1,0) [0|0] "" Vector__XXX
 SG_ ProdInfo_SerialNum_6 : 967|32@0- (1,0) [0|0] "" Vector__XXX
 SG_ ProdInfo_SerialNum_5 : 935|32@0- (1,0) [0|0] "" Vector__XXX
 SG_ ProdInfo_SerialNum_4 : 903|32@0- (1,0) [0|0] "" Vector__XXX
 SG_ ProdInfo_SerialNum_3 : 871|32@0- (1,0) [0|0] "" Vector__XXX
 SG_ ProdInfo_SerialNum_2 : 839|32@0- (1,0) [0|0] "" Vector__XXX
 SG_ ProdInfo_SerialNum_1 : 807|32@0- (1,0) [0|0] "" Vector__XXX
 SG_ ProdInfo_N2KCertLev : 1063|8@0- (1,0) [0|0] "" Vector__XXX
 SG_ ProdInfo_ModelVer_8 : 775|32@0- (1,0) [0|0] "" Vector__XXX
 SG_ ProdInfo_ModelVer_7 : 743|32@0- (1,0) [0|0] "" Vector__XXX
 SG_ ProdInfo_ModelVer_6 : 711|32@0- (1,0) [0|0] "" Vector__XXX
 SG_ ProdInfo_ModelVer_5 : 679|32@0- (1,0) [0|0] "" Vector__XXX
 SG_ ProdInfo_ModelVer_4 : 647|32@0- (1,0) [0|0] "" Vector__XXX
 SG_ ProdInfo_ModelVer_3 : 615|32@0- (1,0) [0|0] "" Vector__XXX
 SG_ ProdInfo_ModelVer_2 : 583|32@0- (1,0) [0|0] "" Vector__XXX
 SG_ ProdInfo_ModelVer_1 : 551|32@0- (1,0) [0|0] "" Vector__XXX
 SG_ ProdInfo_ModelID_8 : 263|32@0- (1,0) [0|0] "" Vector__XXX
 SG_ ProdInfo_ModelID_7 : 231|32@0- (1,0) [0|0] "" Vector__XXX
 SG_ ProdInfo_ModelID_6 : 199|32@0- (1,0) [0|0] "" Vector__XXX
 SG_ ProdInfo_ModelID_5 : 167|32@0- (1,0) [0|0] "" Vector__XXX
 SG_ ProdInfo_LoadEquiv : 1071|8@0- (1,0) [0|0] "" Vector__XXX
 SG_ ProdInfo_ModelID_4 : 135|32@0- (1,0) [0|0] "" Vector__XXX
 SG_ ProdInfo_ModelID_3 : 103|32@0- (1,0) [0|0] "" Vector__XXX
 SG_ ProdInfo_ModelID_2 : 71|32@0- (1,0) [0|0] "" Vector__XXX
 SG_ ProdInfo_ModelID_1 : 39|32@0- (1,0) [0|0] "" Vector__XXX
 SG_ ManufacturersProductCode : 16|16@1+ (1,0) [0|0] "" Vector__XXX
 SG_ NMEA2000Version : 0|16@1+ (1,0) [0|0] "" Vector__XXX

BO_ 2147610640 SystemTime: 8 Vector__XXX
 SG_ Time : 32|32@1+ (0.0001,0) [0|86401] "seconds" Vector__XXX
 SG_ Date : 16|16@1+ (1,0) [0|65532] "days" Vector__XXX
 SG_ Source : 8|4@1+ (1,0) [0|0] "" Vector__XXX
 SG_ SID : 0|8@1+ (1,0) [0|250] "" Vector__XXX

BO_ 2147610112 TxRxPGNListGroupFunction: 8 Vector__XXX
 SG_ FirstPGNSupported : 8|24@1- (1,0) [0|0] "" Vector__XXX
 SG_ TransmittedPGNGroupFunctionCode : 0|8@1- (1,0) [0|0] "" Vector__XXX

BO_ 2147609856 ReqComAckGroup: 15 Vector__XXX
 SG_ ValueofFirstRequestedParameter m0 : 96|8@1+ (1,0) [0|0] "" Vector__XXX
 SG_ FieldNumofReqParameter m0 : 88|8@1+ (1,0) [0|0] "" Vector__XXX
 SG_ NumPairsofReqParametersToFollow m0 : 80|8@1+ (1,0) [0|0] "" Vector__XXX
 SG_ TransmissionIntervalOffset m0 : 64|16@1+ (0.01,0) [0|0] "" Vector__XXX
 SG_ ValueOfFirstCommandParameter m1 : 56|8@1+ (1,0) [0|0] "" Vector__XXX
 SG_ FieldNumFirstCommandParameter m1 : 48|8@1+ (1,0) [0|0] "" Vector__XXX
 SG_ FirstParameterErrorCode m2 : 48|4@1+ (1,0) [0|0] "" Vector__XXX
 SG_ NumPairsCommandedParamFollow m1 : 40|8@1+ (1,0) [0|0] "" Vector__XXX
 SG_ NumberOfParameters m2 : 40|8@1+ (1,0) [0|252] "" Vector__XXX
 SG_ TransmissionIntervalErrorCode m2 : 36|4@1- (1,0) [0|0] "" Vector__XXX
 SG_ TransmissionInterval m0 : 32|32@1+ (0.001,0) [0|0] "" Vector__XXX
 SG_ PrioritySetting m1 : 32|4@1- (1,0) [0|0] "" Vector__XXX
 SG_ PGNErrorCode m2 : 32|4@1+ (1,0) [0|15] "" Vector__XXX
 SG_ CommandedPGN m1 : 8|24@1+ (1,0) [0|0] "" Vector__XXX
 SG_ RequestedPGN m0 : 8|24@1+ (1,0) [0|0] "" Vector__XXX
 SG_ AcknowledgedPGN m2 : 8|24@1+ (1,0) [0|0] "" Vector__XXX
 SG_ GroupFunctionCode M : 0|8@1+ (1,0) [0|0] "" Vector__XXX

BO_ 2147609088 RequestPGN2: 3 Vector__XXX
 SG_ RequestedPGN : 0|24@1+ (1,0) [0|16777200] "" Vector__XXX

BO_ 2147548888 CommandedAddress: 9 Vector__XXX
 SG_ AddressAssignment : 64|8@1+ (1,0) [0|255] "" Vector__XXX
 SG_ SelfConfigurableAddress : 63|1@1+ (1,0) [0|0] "" Vector__XXX
 SG_ IndustryGroup : 60|3@1+ (1,0) [0|0] "" Vector__XXX
 SG_ DeviceClassInstance : 56|4@1+ (1,0) [0|0] "" Vector__XXX
 SG_ DeviceClass : 49|7@1+ (1,0) [0|0] "" Vector__XXX
 SG_ Function : 40|8@1+ (1,0) [0|0] "" Vector__XXX
 SG_ FunctionInstance : 35|5@1+ (1,0) [0|0] "" Vector__XXX
 SG_ ECUInstance : 32|3@1+ (1,0) [0|0] "" Vector__XXX
 SG_ ManufacturerCode : 21|11@1+ (1,0) [0|0] "" Vector__XXX
 SG_ IdentityNumber : 0|21@1+ (1,0) [0|0] "" Vector__XXX

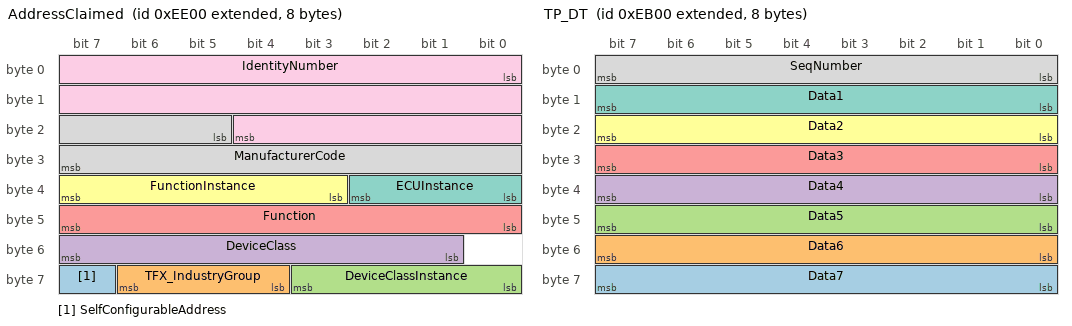
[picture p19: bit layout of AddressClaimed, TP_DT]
BO_ 2147544576 AddressClaimed: 8 Gateway_0
 SG_ SelfConfigurableAddress : 63|1@1+ (1,0) [0|0] "" Vector__XXX
 SG_ TFX_IndustryGroup : 60|3@1+ (1,0) [0|0] "" Vector__XXX
 SG_ DeviceClassInstance : 56|4@1+ (1,0) [0|0] "" Vector__XXX
 SG_ DeviceClass : 49|7@1+ (1,0) [0|0] "" Vector__XXX
 SG_ Function : 40|8@1+ (1,0) [0|0] "" Vector__XXX
 SG_ FunctionInstance : 35|5@1+ (1,0) [0|0] "" Vector__XXX
 SG_ ECUInstance : 32|3@1+ (1,0) [0|0] "" Vector__XXX
 SG_ ManufacturerCode : 21|11@1+ (1,0) [0|0] "" Vector__XXX
 SG_ IdentityNumber : 0|21@1+ (1,0) [0|0] "" Vector__XXX

BO_ 2147544064 TP_CM: 8 Vector__XXX
 SG_ PGNumber : 40|24@1+ (1,0) [0|0] "" Vector__XXX
 SG_ RtsNoPackets m16 : 24|8@1+ (1,0) [0|255] "" Vector__XXX
 SG_ AckNoPackets m19 : 24|8@1+ (1,0) [0|255] "" Vector__XXX
 SG_ NextPacket m17 : 16|8@1+ (1,0) [0|255] "" Vector__XXX
 SG_ RtsMsgSize m16 : 8|16@1+ (1,0) [0|1785] "" Vector__XXX
 SG_ SendPackets m17 : 8|8@1+ (1,0) [0|255] "" Vector__XXX
 SG_ AckMsgSize m19 : 8|16@1+ (1,0) [0|1785] "" Vector__XXX
 SG_ ControlByte M : 0|8@1+ (1,0) [0|255] "" Vector__XXX

BO_ 2147543808 TP_DT: 8 Vector__XXX
 SG_ Data7 : 56|8@1+ (1,0) [0|0] "" Vector__XXX
 SG_ Data6 : 48|8@1+ (1,0) [0|0] "" Vector__XXX
 SG_ Data5 : 40|8@1+ (1,0) [0|0] "" Vector__XXX
 SG_ Data4 : 32|8@1+ (1,0) [0|0] "" Vector__XXX
 SG_ Data3 : 24|8@1+ (1,0) [0|0] "" Vector__XXX
 SG_ Data2 : 16|8@1+ (1,0) [0|0] "" Vector__XXX
 SG_ Data1 : 8|8@1+ (1,0) [0|0] "" Vector__XXX
 SG_ SeqNumber : 0|8@1+ (1,0) [0|255] "" Vector__XXX

BO_ 2147543552 RequestPGN: 3 Vector__XXX
 SG_ RqstedPGN : 0|24@1+ (1,0) [0|16777200] "" Vector__XXX

BO_ 2147543040 ACKN: 8 Vector__XXX
 SG_ PGNumber : 40|24@1+ (1,0) [0|0] "" Vector__XXX
 SG_ CtrlByte : 0|8@1+ (1,0) [0|0] "" Vector__XXX

BO_TX_BU_ 2147544576 : Gateway_1,Gateway_0;

EV_ ev_Stbd_Gear: 0 [0|0] "" 0 1 DUMMY_NODE_VECTOR0 Vector__XXX;

EV_ ev_Port_Gear: 0 [0|0] "" 0 2 DUMMY_NODE_VECTOR0 Vector__XXX;

EV_ ev_Stbd_Rpm: 0 [0|0] "RPM" 0 3 DUMMY_NODE_VECTOR0 Vector__XXX;

EV_ ev_Port_Rpm: 0 [0|0] "RPM" 0 4 DUMMY_NODE_VECTOR0 Vector__XXX;

EV_ ev_Stbd_Lps: 1 [0|0] "V" 0 5 DUMMY_NODE_VECTOR0 Vector__XXX;

EV_ ev_Port_Lps: 1 [0|0] "V" 0 6 DUMMY_NODE_VECTOR0 Vector__XXX;
CM_ BO_ 2147610885 "Sends command to, and receives data from, heading control system.";
CM_ BO_ 2147614226 "This PGN provides a single transmission that accurately describes the speed of a vessel by component vectors.";
CM_ BO_ 2147614225 "The purpose of this PNG is to group three fundamental vectors related to vessel motion,
-speed and heading referenced to the water
-speed and course referenced to ground
-current speed and flow direction";
CM_ BO_ 2147614224 "Provides data on various small craft control surfaces and speed through the water.";
CM_ BO_ 2147613962 "Universal automatic indentification system (U.AIS) periodic alternate message.";
CM_ BO_ 2147613961 "Universal automatic identification system (U.AIS) VTS targets message.";
CM_ BO_ 2147613960 "Universal automatic identification system (U.AIS) safety related broadcast message.";
CM_ BO_ 2147613959 "Universal automatic identification system (U.AIS) adressed safety related message.";
CM_ BO_ 2147613958 "Local atmospheric environmental conditions.";
CM_ BO_ 2147613957 "Universal automatic identification system (U.AIS) binary broadcast message.";
CM_ BO_ 2147613956 "Universal automatic idenfication system (U.AIS) adressed binary message. This message conveys
application specific binary data.";
CM_ BO_ 2147613955 "Universal automatic identification system (U.AIS) ship static and voyage related date message.";
CM_ BO_ 2147613954 "Direction an dspeed of wind.";
CM_ BO_ 2147613700 "This provides time difference (TD) lines of position of Loran-C signals relative to a single group repetition interval.";
CM_ BO_ 2147613456 "This PGN provides digital selective calling (DSC) data according to ITU m.493-9 with optional expansion
according to ITU M.821-1.";
CM_ BO_ 2147613447 "This PGN provides status and control for a radiotelephone, connected to a NMEA2000 network.";
CM_ BO_ 2147613204 "THis PGN provides a singel transmission that contains relevant almanac data for GLONASS products.";
CM_ BO_ 2147613199 "GNSS differential correction receiver status tagged by sequence ID.";
CM_ BO_ 2147613198 "GNSS common differential correction receiver parameter status.";
CM_ BO_ 2147613197 "This PGN provides a means to pass differential GNSS corrections between NMEA2000 devices.";
CM_ BO_ 2147613195 "This parameter group is used to support receiver autonomous integrity monitoring (RAIM).";
CM_ BO_ 2147613194 "This PGN is used to report the control parameters for a GNSS receiver autonomous integrity monitoring (RAIM) process.";
CM_ BO_ 2147613193 "This PGN is used to provide the output from a GNSS receiver's receiver autonomoues intergrity monitoring (RAIM) process.";
CM_ BO_ 2147613190 "GNSS pseudorange measurement noise statistics can be translated in the postion domain in order to give
statistical measures of the quality of the position solution.";
CM_ BO_ 2147613188 "GNSS information of current satellites in vie tagged by sequence ID.";
CM_ SG_ 2147613188 Azimuth2 "Degrees clockwise relative to true north.";
CM_ SG_ 2147613188 Azimuth1 "Degrees clockwise relative to true north.";
CM_ SG_ 2147613188 Mode "Range residual used in position calculation or range residuals were calculated after the position.";
CM_ BO_ 2147613187 "This PGN provides a single transmission containing GNSS sttus and dilution of precision components (DOP)
that indicate the contribution of satellite geometry to the overall positioning error.";
CM_ BO_ 2147613186 "129817";
CM_ BO_ 2147612950 "Bearing and distance from origin mark to the destination mark, calculated at the origin mark,
for any two arbitrary generic marks.";
CM_ SG_ 2147612950 DestinationMarkType "Destination mark type";
CM_ SG_ 2147612950 OriginMarkType "Origin mark type";
CM_ BO_ 2147612949 "Time to go to or elapsed from a generic mark, that by be non-fixed.";
CM_ BO_ 2147612939 "The set and drift effect on the vessel is the direction and the speed of a current.";
CM_ BO_ 2147612932 "This PGN provides essential navigation data for a route following.";
CM_ SG_ 2147612932 DistanceToDestWaypoint "Distance to destination waypoint";
CM_ BO_ 2147612931 "This PGN provides the magnitude of position error perpendicular to the desired course.";
CM_ BO_ 2147612693 "Transformation parameters for converting from WGS-84 to other datums.";
CM_ SG_ 2147612693 DatumName "4-character code for the datum currently being output for the position solution.";
CM_ BO_ 2147612692 "Local geodetic datum and datum offets from a reference point.";
CM_ BO_ 2147612681 "This PGN has a single transmission that provides:
-UTC time
-UTC date
-Local offset";
CM_ BO_ 2147612677 "This PGN conveys a comprehensive set of global navigation satellite system (GNSS) parameters,
including position information";
CM_ SG_ 2147612677 PDOP "Position (?) Dilution of Position";
CM_ SG_ 2147612677 HDOP "Horizontal Dilution Of Precision";
CM_ SG_ 2147612677 GNSSIntegrity "GNSS Integrity";
CM_ SG_ 2147612677 MethodGNSS "Quality GNSS";
CM_ SG_ 2147612677 TypeOfSystem "Type of system";
CM_ BO_ 2147612674 "Thie PGN is a singe fram PGN that provides course over ground (COG)
and speed over ground (SOG).";
CM_ BO_ 2147612173 "Universal automatic identification system (U.AIS) time and date report message.";
CM_ BO_ 2147612172 "Universal automatic identification system (U.AIS) position report message.";
CM_ BO_ 2147612168 "Message for reporting status and target data from tracking radar external devices.";
CM_ BO_ 2147611923 "This PGN provides the cumulative voyage distance traveled since the last reset.";
CM_ BO_ 2147611915 "Water depth relative to the transducer and offset of the measuring transducer.";
CM_ BO_ 2147611907 "The purpose of this PGN is to provide a singel transmission that describes the motion of a vessel.";
CM_ SG_ 2147611907 SpeedGroundReferenced "Speed ground referenced";
CM_ SG_ 2147611907 SpeedWaterReferenced "Speed water referenced";
CM_ BO_ 2147611156 "Provides parametric data for a specific battery, indicated by the battery instance field.";
CM_ BO_ 2147611153 "Fluid level contains an instance number, level of fluid, and type of fluid.";
CM_ SG_ 2147611153 FluidType "Type of fluid";
CM_ BO_ 2147611150 "Universal command to multiple banks of two-state devices";
CM_ BO_ 2147611149 "Universal status report for multible banks of two-state indicators.";
CM_ BO_ 2147611146 "Provides identification information and rated engine speed for the engine indicated by the engine instance field.";
CM_ BO_ 2147611145 "Trip engine hours and fuel consumption";
CM_ BO_ 2147611141 "Used to provide the operational state and internal operating parameters of a specific transmission,
indicated by the transmission.";
CM_ SG_ 2147611141 TransmissionGear "Transmission gear";
CM_ SG_ 2147611141 TransmissionInstance "Transmission instance";
CM_ BO_ 2147611137 "Used to provide real-time operational data and status relevant to a specific engine, indicated
by the engine instance field.";
CM_ BO_ 2147611136 "Provides data with a high update rate for a specific engine in a single frame message.";
CM_ BO_ 2147610905 "This PGN provides a single transmission that describes the position of a vessel relative to both horzontal
and vertical planes.";
CM_ BO_ 2147610898 "Heading sensor value with a flag for true or magnetic.";
CM_ BO_ 2147610893 "Rudder order command in direction or angle with current rudder angle reading.";
CM_ BO_ 2147610644 "130585";
CM_ BO_ 2147610640 "The purpose of this PGN is twofold:
-To provide a regular transmission of UTC time and date
-To provide syschronism for measurement data";
CM_ BO_ 2147548888 "IOS11783 defined this message to provide a mechanism for assigning a network address to a node.";
CM_ SG_ 2147548888 AddressAssignment "Network address";
CM_ BO_ 2147544576 "Address Claim";
CM_ BO_ 2147544064 "ISO11783 defines this group function PGN as part of the transpor tprotocol method used for transmitting
messages that have 9 or more data bytes.";
CM_ BO_ 2147543552 "ISO 11783 defines this message to provide a method for requesting the trnasmission of a PGN from a network device.";
BA_DEF_ BO_  "J1939PGDp" INT 0 1;
BA_DEF_ BO_  "J1939PGRepetitionType" ENUM  "always","when active","on request";
BA_DEF_ BO_  "J1939PGRepetitionCycle" INT 0 65535;
BA_DEF_ SG_  "SigType" STRING ;
BA_DEF_ BO_  "J1939PGPrio" INT 0 7;
BA_DEF_ BO_  "J1939PGDest" INT 0 255;
BA_DEF_ BO_  "SingleFrame" INT 0 1;
BA_DEF_DEF_  "J1939PGDp" 0;
BA_DEF_DEF_  "J1939PGRepetitionType" "always";
BA_DEF_DEF_  "J1939PGRepetitionCycle" 1000;
BA_DEF_DEF_  "SigType" "";
BA_DEF_DEF_  "J1939PGPrio" 6;
BA_DEF_DEF_  "J1939PGDest" 255;
BA_DEF_DEF_  "SingleFrame" 0;
BA_ "SingleFrame" BO_ 2680225683 1;
BA_ "SingleFrame" BO_ 2680225680 1;
BA_ "SingleFrame" BO_ 2680225687 1;
BA_ "SingleFrame" BO_ 2680225686 1;
BA_ "SingleFrame" BO_ 2680225621 1;
BA_ "J1939PGPrio" BO_ 2680225616 2;
BA_ "SingleFrame" BO_ 2680225616 1;
BA_ "SingleFrame" BO_ 2680225682 1;
BA_ "SingleFrame" BO_ 2680225681 1;
BA_ "J1939PGDp" BO_ 2147610885 1;
BA_ "J1939PGRepetitionCycle" BO_ 2147610885 250;
BA_ "J1939PGPrio" BO_ 2147610885 2;
BA_ "SingleFrame" BO_ 2680225679 1;
BA_ "SingleFrame" BO_ 2185297681 1;
BA_ "J1939PGRepetitionCycle" BO_ 2680225657 50;
BA_ "SingleFrame" BO_ 2680225657 1;
BA_ "J1939PGRepetitionCycle" BO_ 2680225656 50;
BA_ "SingleFrame" BO_ 2680225656 1;
BA_ "SingleFrame" BO_ 2149646097 1;
BA_ "J1939PGPrio" BO_ 2680225678 3;
BA_ "SingleFrame" BO_ 2680225678 1;
BA_ "J1939PGRepetitionCycle" BO_ 2680225641 10;
BA_ "J1939PGPrio" BO_ 2680225641 3;
BA_ "SingleFrame" BO_ 2680225641 1;
BA_ "J1939PGRepetitionCycle" BO_ 2350972777 10;
BA_ "J1939PGPrio" BO_ 2350972777 3;
BA_ "SingleFrame" BO_ 2350972777 1;
BA_ "J1939PGRepetitionCycle" BO_ 2348875625 10;
BA_ "J1939PGPrio" BO_ 2348875625 3;
BA_ "SingleFrame" BO_ 2348875625 1;
BA_ "J1939PGPrio" BO_ 2680225697 3;
BA_ "SingleFrame" BO_ 2680225697 1;
BA_ "J1939PGRepetitionCycle" BO_ 2680225653 10;
BA_ "J1939PGPrio" BO_ 2680225653 5;
BA_ "SingleFrame" BO_ 2680225653 1;
BA_ "J1939PGRepetitionCycle" BO_ 2680225652 10;
BA_ "J1939PGPrio" BO_ 2680225652 5;
BA_ "SingleFrame" BO_ 2680225652 1;
BA_ "J1939PGRepetitionCycle" BO_ 2680225651 10;
BA_ "J1939PGPrio" BO_ 2680225651 5;
BA_ "SingleFrame" BO_ 2680225651 1;
BA_ "J1939PGRepetitionCycle" BO_ 2680225649 10;
BA_ "J1939PGPrio" BO_ 2680225649 7;
BA_ "SingleFrame" BO_ 2680225649 1;
BA_ "J1939PGRepetitionCycle" BO_ 2680225631 10;
BA_ "J1939PGPrio" BO_ 2680225631 2;
BA_ "SingleFrame" BO_ 2680225631 1;
BA_ "J1939PGRepetitionCycle" BO_ 2680225647 10;
BA_ "J1939PGPrio" BO_ 2680225647 5;
BA_ "SingleFrame" BO_ 2680225647 1;
BA_ "SingleFrame" BO_ 2680225646 1;
BA_ "J1939PGRepetitionCycle" BO_ 2680225637 10;
BA_ "J1939PGPrio" BO_ 2680225637 2;
BA_ "SingleFrame" BO_ 2680225637 1;
BA_ "J1939PGPrio" BO_ 2680225696 3;
BA_ "SingleFrame" BO_ 2680225696 1;
BA_ "J1939PGPrio" BO_ 2680225677 3;
BA_ "J1939PGRepetitionCycle" BO_ 2680225677 50;
BA_ "SingleFrame" BO_ 2680225677 1;
BA_ "J1939PGPrio" BO_ 2680225676 3;
BA_ "J1939PGRepetitionCycle" BO_ 2680225676 50;
BA_ "SingleFrame" BO_ 2680225676 1;
BA_ "SingleFrame" BO_ 2680225636 1;
BA_ "J1939PGRepetitionCycle" BO_ 2680225636 10;
BA_ "J1939PGPrio" BO_ 2680225636 2;
BA_ "SingleFrame" BO_ 2680225630 1;
BA_ "J1939PGRepetitionCycle" BO_ 2680225630 10;
BA_ "J1939PGPrio" BO_ 2680225630 3;
BA_ "SingleFrame" BO_ 2680225626 1;
BA_ "J1939PGRepetitionCycle" BO_ 2680225626 10;
BA_ "J1939PGPrio" BO_ 2680225626 3;
BA_ "J1939PGDp" BO_ 2147614226 1;
BA_ "J1939PGPrio" BO_ 2147614226 2;
BA_ "J1939PGRepetitionCycle" BO_ 2147614226 250;
BA_ "J1939PGDp" BO_ 2147614225 1;
BA_ "J1939PGPrio" BO_ 2147614225 3;
BA_ "J1939PGDp" BO_ 2147614224 1;
BA_ "SingleFrame" BO_ 2147614224 1;
BA_ "J1939PGPrio" BO_ 2147614224 2;
BA_ "J1939PGRepetitionCycle" BO_ 2147614224 200;
BA_ "J1939PGDp" BO_ 2147613972 1;
BA_ "J1939PGDp" BO_ 2147613971 1;
BA_ "J1939PGDp" BO_ 2147613970 1;
BA_ "J1939PGDp" BO_ 2147613969 1;
BA_ "J1939PGDp" BO_ 2147613968 1;
BA_ "J1939PGDp" BO_ 2147613962 1;
BA_ "J1939PGPrio" BO_ 2147613962 3;
BA_ "J1939PGPrio" BO_ 2147613961 3;
BA_ "J1939PGDp" BO_ 2147613960 1;
BA_ "J1939PGPrio" BO_ 2147613960 3;
BA_ "J1939PGDp" BO_ 2147613959 1;
BA_ "J1939PGPrio" BO_ 2147613959 3;
BA_ "J1939PGDp" BO_ 2147613958 1;
BA_ "SingleFrame" BO_ 2147613958 1;
BA_ "J1939PGPrio" BO_ 2147613958 5;
BA_ "J1939PGRepetitionCycle" BO_ 2147613958 500;
BA_ "J1939PGDp" BO_ 2147613957 1;
BA_ "J1939PGPrio" BO_ 2147613957 3;
BA_ "J1939PGDp" BO_ 2147613956 1;
BA_ "J1939PGPrio" BO_ 2147613956 3;
BA_ "J1939PGDp" BO_ 2147613955 1;
BA_ "J1939PGPrio" BO_ 2147613955 3;
BA_ "J1939PGDp" BO_ 2147613954 1;
BA_ "J1939PGPrio" BO_ 2147613954 2;
BA_ "SingleFrame" BO_ 2147613954 1;
BA_ "J1939PGRepetitionCycle" BO_ 2147613954 100;
BA_ "J1939PGDp" BO_ 2147613702 1;
BA_ "J1939PGPrio" BO_ 2147613702 3;
BA_ "J1939PGDp" BO_ 2147613701 1;
BA_ "J1939PGPrio" BO_ 2147613701 3;
BA_ "J1939PGDp" BO_ 2147613700 1;
BA_ "J1939PGPrio" BO_ 2147613700 3;
BA_ "J1939PGDp" BO_ 2147613456 1;
BA_ "J1939PGPrio" BO_ 2147613456 4;
BA_ "J1939PGDp" BO_ 2147613447 1;
BA_ "J1939PGPrio" BO_ 2147613447 3;
BA_ "J1939PGDp" BO_ 2147613204 1;
BA_ "J1939PGDp" BO_ 2147613199 1;
BA_ "J1939PGDp" BO_ 2147613198 1;
BA_ "SingleFrame" BO_ 2147613198 1;
BA_ "J1939PGDp" BO_ 2147613197 1;
BA_ "J1939PGDp" BO_ 2147613195 1;
BA_ "J1939PGDp" BO_ 2147613194 1;
BA_ "SingleFrame" BO_ 2147613194 1;
BA_ "J1939PGDp" BO_ 2147613193 1;
BA_ "J1939PGDp" BO_ 2147613190 1;
BA_ "J1939PGDp" BO_ 2147613189 1;
BA_ "J1939PGDp" BO_ 2147613188 1;
BA_ "J1939PGDp" BO_ 2147613187 1;
BA_ "SingleFrame" BO_ 2147613187 1;
BA_ "J1939PGDp" BO_ 2147613186 1;
BA_ "J1939PGDp" BO_ 2147612950 1;
BA_ "J1939PGDp" BO_ 2147612949 1;
BA_ "J1939PGPrio" BO_ 2147612949 3;
BA_ "J1939PGDp" BO_ 2147612939 1;
BA_ "SingleFrame" BO_ 2147612939 1;
BA_ "J1939PGPrio" BO_ 2147612939 3;
BA_ "J1939PGDp" BO_ 2147612932 1;
BA_ "J1939PGPrio" BO_ 2147612932 3;
BA_ "J1939PGDp" BO_ 2147612931 1;
BA_ "SingleFrame" BO_ 2147612931 1;
BA_ "J1939PGPrio" BO_ 2147612931 3;
BA_ "J1939PGDp" BO_ 2147612693 1;
BA_ "J1939PGDp" BO_ 2147612692 1;
BA_ "J1939PGRepetitionCycle" BO_ 2147612692 10000;
BA_ "J1939PGDp" BO_ 2147612681 1;
BA_ "SingleFrame" BO_ 2147612681 1;
BA_ "J1939PGPrio" BO_ 2147612681 3;
BA_ "J1939PGDp" BO_ 2147612677 1;
BA_ "J1939PGPrio" BO_ 2147612677 3;
BA_ "J1939PGDp" BO_ 2147612674 1;
BA_ "SingleFrame" BO_ 2147612674 1;
BA_ "J1939PGPrio" BO_ 2147612674 3;
BA_ "J1939PGRepetitionCycle" BO_ 2147612674 250;
BA_ "J1939PGDp" BO_ 2147612673 1;
BA_ "SingleFrame" BO_ 2147612673 1;
BA_ "J1939PGPrio" BO_ 2147612673 2;
BA_ "J1939PGRepetitionCycle" BO_ 2147612673 100;
BA_ "J1939PGDp" BO_ 2147612173 1;
BA_ "J1939PGPrio" BO_ 2147612173 3;
BA_ "J1939PGDp" BO_ 2147612172 1;
BA_ "J1939PGPrio" BO_ 2147612172 3;
BA_ "J1939PGDp" BO_ 2147612168 1;
BA_ "J1939PGPrio" BO_ 2147612168 2;
BA_ "J1939PGDp" BO_ 2147611923 1;
BA_ "J1939PGDp" BO_ 2147611915 1;
BA_ "SingleFrame" BO_ 2147611915 1;
BA_ "J1939PGPrio" BO_ 2147611915 3;
BA_ "J1939PGDp" BO_ 2147611907 1;
BA_ "SingleFrame" BO_ 2147611907 1;
BA_ "J1939PGPrio" BO_ 2147611907 2;
BA_ "J1939PGDp" BO_ 2147611156 1;
BA_ "SingleFrame" BO_ 2147611156 1;
BA_ "J1939PGRepetitionCycle" BO_ 2147611156 1500;
BA_ "J1939PGDp" BO_ 2147611153 1;
BA_ "SingleFrame" BO_ 2147611153 1;
BA_ "J1939PGRepetitionCycle" BO_ 2147611153 2500;
BA_ "J1939PGDp" BO_ 2147611150 1;
BA_ "SingleFrame" BO_ 2147611150 1;
BA_ "J1939PGPrio" BO_ 2147611150 3;
BA_ "J1939PGDp" BO_ 2147611149 1;
BA_ "SingleFrame" BO_ 2147611149 1;
BA_ "J1939PGPrio" BO_ 2147611149 3;
BA_ "J1939PGDp" BO_ 2147611146 1;
BA_ "J1939PGPrio" BO_ 2147611146 5;
BA_ "J1939PGDp" BO_ 2147611145 1;
BA_ "SingleFrame" BO_ 2147611145 1;
BA_ "J1939PGPrio" BO_ 2147611145 5;
BA_ "J1939PGDp" BO_ 2147611141 1;
BA_ "SingleFrame" BO_ 2147611141 1;
BA_ "J1939PGPrio" BO_ 2147611141 2;
BA_ "J1939PGRepetitionCycle" BO_ 2147611141 100;
BA_ "J1939PGDp" BO_ 2147611137 1;
BA_ "J1939PGPrio" BO_ 2147611137 2;
BA_ "J1939PGDp" BO_ 2147611136 1;
BA_ "J1939PGPrio" BO_ 2147611136 2;
BA_ "SingleFrame" BO_ 2147611136 1;
BA_ "J1939PGDp" BO_ 2147610905 1;
BA_ "SingleFrame" BO_ 2147610905 1;
BA_ "J1939PGPrio" BO_ 2147610905 3;
BA_ "J1939PGDp" BO_ 2147610898 1;
BA_ "SingleFrame" BO_ 2147610898 1;
BA_ "J1939PGPrio" BO_ 2147610898 2;
BA_ "J1939PGRepetitionCycle" BO_ 2147610898 100;
BA_ "J1939PGDp" BO_ 2147610896 1;
BA_ "SingleFrame" BO_ 2147610896 1;
BA_ "J1939PGPrio" BO_ 2147610896 3;
BA_ "J1939PGDp" BO_ 2147610893 1;
BA_ "SingleFrame" BO_ 2147610893 1;
BA_ "J1939PGPrio" BO_ 2147610893 3;
BA_ "J1939PGRepetitionCycle" BO_ 2147610893 100;
BA_ "J1939PGDp" BO_ 2147610646 1;
BA_ "J1939PGDp" BO_ 2147610644 1;
BA_ "J1939PGDp" BO_ 2147610640 1;
BA_ "SingleFrame" BO_ 2147610640 1;
BA_ "J1939PGPrio" BO_ 2147610640 3;
BA_ "J1939PGDp" BO_ 2147610112 1;
BA_ "SingleFrame" BO_ 2147610112 1;
BA_ "J1939PGDp" BO_ 2147609856 1;
BA_ "J1939PGPrio" BO_ 2147609856 3;
BA_ "J1939PGDp" BO_ 2147609088 1;
BA_ "SingleFrame" BO_ 2147609088 1;
BA_ "SingleFrame" BO_ 2147548888 1;
BA_ "SingleFrame" BO_ 2147544576 1;
BA_ "SingleFrame" BO_ 2147544064 1;
BA_ "J1939PGPrio" BO_ 2147544064 7;
BA_ "SingleFrame" BO_ 2147543808 1;
BA_ "J1939PGPrio" BO_ 2147543808 7;
BA_ "SingleFrame" BO_ 2147543552 1;
BA_ "SingleFrame" BO_ 2147543040 1;
BA_ "SigType" SG_ 2680225621 TFX_IndustryGroup "SPECIFIC";
BA_ "SigType" SG_ 2680225616 TFX_IndustryGroup "SPECIFIC";
BA_ "SigType" SG_ 2147610885 VesselHeading "RANGE";
BA_ "SigType" SG_ 2147610885 OffTrackLimit "RANGE";
BA_ "SigType" SG_ 2147610885 RateOfTurnOrder "RANGE";
BA_ "SigType" SG_ 2147610885 RadiusOfTurnOrder "RANGE";
BA_ "SigType" SG_ 2147610885 OffHeadingLimit "RANGE";
BA_ "SigType" SG_ 2147610885 RudderLimit "RANGE";
BA_ "SigType" SG_ 2147610885 Track "RANGE";
BA_ "SigType" SG_ 2147610885 HeadingToSteer "RANGE";
BA_ "SigType" SG_ 2147610885 CommandedRudderAngle "RANGE";
BA_ "SigType" SG_ 2147610885 CommandedRudderDirection "DISCRETE";
BA_ "SigType" SG_ 2147610885 HeadingReference "DISCRETE";
BA_ "SigType" SG_ 2147610885 TurnMode "DISCRETE";
BA_ "SigType" SG_ 2147610885 SteerigMode "DISCRETE";
BA_ "SigType" SG_ 2147610885 Override "DISCRETE";
BA_ "SigType" SG_ 2147610885 OffTrackLimitExceeded "DISCRETE";
BA_ "SigType" SG_ 2147610885 OffheadingLimitExceeded "DISCRETE";
BA_ "SigType" SG_ 2147610885 RudderLimitExceeded "DISCRETE";
BA_ "SigType" SG_ 2680225679 TFX_VC_RPMCmd_SCtr "RANGE";
BA_ "SigType" SG_ 2680225679 TFX_VC_RPMCmd_PCtr "RANGE";
BA_ "SigType" SG_ 2680225679 TFX_VC_RPMCmd_Stbd "RANGE";
BA_ "SigType" SG_ 2680225679 TFX_VC_RPMCmd_Port "RANGE";
BA_ "SigType" SG_ 2680225657 TFX_IndustryGroup "SPECIFIC";
BA_ "SigType" SG_ 2680225656 TFX_IndustryGroup "SPECIFIC";
BA_ "SigType" SG_ 2680225678 TFX_PrtRPMError "*";
BA_ "SigType" SG_ 2680225678 TFX_StbdRPMError "*";
BA_ "SigType" SG_ 2680225641 TFX_IndustryGroup "SPECIFIC";
BA_ "SigType" SG_ 2350972777 TFX_IndustryGroup "SPECIFIC";
BA_ "SigType" SG_ 2348875625 TFX_IndustryGroup "SPECIFIC";
BA_ "SigType" SG_ 2680225653 TFX_IndustryGroup "SPECIFIC";
BA_ "SigType" SG_ 2680225652 TFX_IndustryGroup "SPECIFIC";
BA_ "SigType" SG_ 2680225651 TFX_IndustryGroup "SPECIFIC";
BA_ "SigType" SG_ 2680225649 TFX_IndustryGroup "SPECIFIC";
BA_ "SigType" SG_ 2680225631 ResumeRequest "DISCRETE";
BA_ "SigType" SG_ 2680225631 TFX_IndustryGroup "SPECIFIC";
BA_ "SigType" SG_ 2680225647 TFX_IndustryGroup "SPECIFIC";
BA_ "SigType" SG_ 2680225646 TFX_IndustryGroup "SPECIFIC";
BA_ "SigType" SG_ 2680225637 TFX_IndustryGroup "SPECIFIC";
BA_ "SigType" SG_ 2680225636 TFX_IndustryGroup "SPECIFIC";
BA_ "SigType" SG_ 2680225630 TFX_StbdRudderFbk "RANGE";
BA_ "SigType" SG_ 2680225630 TFX_PrtRudderFbk "RANGE";
BA_ "SigType" SG_ 2680225630 TFX_IndustryGroup "SPECIFIC";
BA_ "SigType" SG_ 2680225626 TFX_IndustryGroup "SPECIFIC";
BA_ "SigType" SG_ 2680225626 TFX_StbdRudderCmd "RANGE";
BA_ "SigType" SG_ 2680225626 TFX_PrtRudderCmd "RANGE";
BA_ "SigType" SG_ 2147614226 SternSpeedGroundRef "RANGE";
BA_ "SigType" SG_ 2147614226 SternSpeedWaterRef "RANGE";
BA_ "SigType" SG_ 2147614226 TransSpeedGroundRef "RANGE";
BA_ "SigType" SG_ 2147614226 LongSpeedGroundRef "RANGE";
BA_ "SigType" SG_ 2147614226 TransSpeedWaterRef "RANGE";
BA_ "SigType" SG_ 2147614226 LongSpeedWaterRef "RANGE";
BA_ "SigType" SG_ 2147614225 DriftSpeed "RANGE";
BA_ "SigType" SG_ 2147614225 CurrentFlowDirection "RANGE";
BA_ "SigType" SG_ 2147614225 Speed "RANGE";
BA_ "SigType" SG_ 2147614225 Heading "RANGE";
BA_ "SigType" SG_ 2147614225 SpeedOverGround "RANGE";
BA_ "SigType" SG_ 2147614225 CourseOverGround "RANGE";
BA_ "SigType" SG_ 2147614225 SeqID "SPECIFIC";
BA_ "SigType" SG_ 2147614225 SetCOGheadingRef "DISCRETE";
BA_ "SigType" SG_ 2147614225 DataMode "DISCRETE";
BA_ "SigType" SG_ 2147614224 StarboardTrimTab "RANGE";
BA_ "SigType" SG_ 2147614224 PortTrimTab "RANGE";
BA_ "SigType" SG_ 2147613972 WaterTemperature "RANGE";
BA_ "SigType" SG_ 2147613972 AirTemperature "RANGE";
BA_ "SigType" SG_ 2147613972 PressureTendencyRate "RANGE";
BA_ "SigType" SG_ 2147613972 AtmosphericPressure "RANGE";
BA_ "SigType" SG_ 2147613972 DominantWavePeriod "RANGE";
BA_ "SigType" SG_ 2147613972 WaveHeight "RANGE";
BA_ "SigType" SG_ 2147613972 WindGusts "RANGE";
BA_ "SigType" SG_ 2147613972 WindReference "DISCRETE";
BA_ "SigType" SG_ 2147613972 WindDirection "RANGE";
BA_ "SigType" SG_ 2147613972 WindSpeed "RANGE";
BA_ "SigType" SG_ 2147613972 StationLocationLongitude "RANGE";
BA_ "SigType" SG_ 2147613972 StationLocationLatitude "RANGE";
BA_ "SigType" SG_ 2147613972 MeasurementTime "RANGE";
BA_ "SigType" SG_ 2147613972 MeasurementDate "RANGE";
BA_ "SigType" SG_ 2147613972 Mode "DISCRETE";
BA_ "SigType" SG_ 2147613971 AirTemperature "RANGE";
BA_ "SigType" SG_ 2147613971 AtmosphericPressure "RANGE";
BA_ "SigType" SG_ 2147613971 WindGusts "RANGE";
BA_ "SigType" SG_ 2147613971 WindReference "DISCRETE";
BA_ "SigType" SG_ 2147613971 WindDirection "RANGE";
BA_ "SigType" SG_ 2147613971 WindSpeed "RANGE";
BA_ "SigType" SG_ 2147613971 StationLocationLongitude "RANGE";
BA_ "SigType" SG_ 2147613971 StationLocationLatitude "RANGE";
BA_ "SigType" SG_ 2147613971 MeasurementTime "RANGE";
BA_ "SigType" SG_ 2147613971 MeasurementDate "RANGE";
BA_ "SigType" SG_ 2147613971 Mode "DISCRETE";
BA_ "SigType" SG_ 2147613970 WaterTemperature "RANGE";
BA_ "SigType" SG_ 2147613970 CurrentFlowDirection "RANGE";
BA_ "SigType" SG_ 2147613970 CurrentSpeed "RANGE";
BA_ "SigType" SG_ 2147613970 MeasurementDepth "RANGE";
BA_ "SigType" SG_ 2147613970 StationLocationLongitude "RANGE";
BA_ "SigType" SG_ 2147613970 StationLocationLatitude "RANGE";
BA_ "SigType" SG_ 2147613970 MeasurementTime "RANGE";
BA_ "SigType" SG_ 2147613970 MeasurementDate "RANGE";
BA_ "SigType" SG_ 2147613970 State "DISCRETE";
BA_ "SigType" SG_ 2147613970 Mode "DISCRETE";
BA_ "SigType" SG_ 2147613969 WaterTemperature "RANGE";
BA_ "SigType" SG_ 2147613969 Salinity "RANGE";
BA_ "SigType" SG_ 2147613969 StationLocationLongitude "RANGE";
BA_ "SigType" SG_ 2147613969 StationLocationLatitude "RANGE";
BA_ "SigType" SG_ 2147613969 MeasurementTime "RANGE";
BA_ "SigType" SG_ 2147613969 MeasurementDate "RANGE";
BA_ "SigType" SG_ 2147613969 Mode "DISCRETE";
BA_ "SigType" SG_ 2147613968 TideLevelStandardDeviation "RANGE";
BA_ "SigType" SG_ 2147613968 TideLevel "RANGE";
BA_ "SigType" SG_ 2147613968 StationLocationLongitude "RANGE";
BA_ "SigType" SG_ 2147613968 StationLocationLatitude "RANGE";
BA_ "SigType" SG_ 2147613968 MeasurementTime "RANGE";
BA_ "SigType" SG_ 2147613968 MeasurementDate "RANGE";
BA_ "SigType" SG_ 2147613968 TideTendency "DISCRETE";
BA_ "SigType" SG_ 2147613968 Mode "DISCRETE";
BA_ "SigType" SG_ 2147613962 CommunicationsStateID "DISCRETE";
BA_ "SigType" SG_ 2147613962 ApplicationStatusBits "SPECIFIC";
BA_ "SigType" SG_ 2147613962 RepeatIndicator "DISCRETE";
BA_ "SigType" SG_ 2147613962 MessageID "SPECIFIC";
BA_ "SigType" SG_ 2147613961 TargetIDInternationMaritimeOrg "RANGE";
BA_ "SigType" SG_ 2147613961 TargetIDMariMobileServiceID "RANGE";
BA_ "SigType" SG_ 2147613961 SourceMariMobileServiceID "RANGE";
BA_ "SigType" SG_ 2147613961 UAISSpareBitsA "DISCRETE";
BA_ "SigType" SG_ 2147613961 RepeatIndicator "DISCRETE";
BA_ "SigType" SG_ 2147613961 MessageID "SPECIFIC";
BA_ "SigType" SG_ 2147613960 SourceMariMobileServiceID "RANGE";
BA_ "SigType" SG_ 2147613960 UAISSpareBits "DISCRETE";
BA_ "SigType" SG_ 2147613960 RepeatIndicator "DISCRETE";
BA_ "SigType" SG_ 2147613960 MessageID "SPECIFIC";
BA_ "SigType" SG_ 2147613959 DestinationMariMobileServiceID "RANGE";
BA_ "SigType" SG_ 2147613959 SequenceNumber "RANGE";
BA_ "SigType" SG_ 2147613959 SourceMariMobileServiceID "RANGE";
BA_ "SigType" SG_ 2147613959 UAISSpareBits "DISCRETE";
BA_ "SigType" SG_ 2147613959 RepeatIndicator "DISCRETE";
BA_ "SigType" SG_ 2147613959 MessageID "SPECIFIC";
BA_ "SigType" SG_ 2147613958 AtmosphericPressure "RANGE";
BA_ "SigType" SG_ 2147613958 OutsideAmbientAirTemp "RANGE";
BA_ "SigType" SG_ 2147613958 WaterTemperature "RANGE";
BA_ "SigType" SG_ 2147613958 SID "SPECIFIC";
BA_ "SigType" SG_ 2147613957 SourceMariMobilServiceID "RANGE";
BA_ "SigType" SG_ 2147613957 UAISSpareBits "DISCRETE";
BA_ "SigType" SG_ 2147613957 RepeatIndicator "DISCRETE";
BA_ "SigType" SG_ 2147613957 MessageID "SPECIFIC";
BA_ "SigType" SG_ 2147613956 DestinationMariMobileServiceID "SPECIFIC";
BA_ "SigType" SG_ 2147613956 SequenceID "RANGE";
BA_ "SigType" SG_ 2147613956 SouceMariMobileServiceID "RANGE";
BA_ "SigType" SG_ 2147613956 UAISSpareBits "DISCRETE";
BA_ "SigType" SG_ 2147613956 RepeatIndicator "DISCRETE";
BA_ "SigType" SG_ 2147613956 MessageID "SPECIFIC";
BA_ "SigType" SG_ 2147613955 ShipCallSignal7 "SPECIFIC";
BA_ "SigType" SG_ 2147613955 ShipCallSignal6 "SPECIFIC";
BA_ "SigType" SG_ 2147613955 ShipCallSignal5 "SPECIFIC";
BA_ "SigType" SG_ 2147613955 ShipCallSignal4 "SPECIFIC";
BA_ "SigType" SG_ 2147613955 ShipCallSignal3 "SPECIFIC";
BA_ "SigType" SG_ 2147613955 ShipCallSignal2 "SPECIFIC";
BA_ "SigType" SG_ 2147613955 ShipCallSignal1 "SPECIFIC";
BA_ "SigType" SG_ 2147613955 InternationlMaritimeOrgNumber "RANGE";
BA_ "SigType" SG_ 2147613955 UAISSpareBits "DISCRETE";
BA_ "SigType" SG_ 2147613955 RepeatIndicator "DISCRETE";
BA_ "SigType" SG_ 2147613955 MaritimeMobileServiceIDNumber "RANGE";
BA_ "SigType" SG_ 2147613955 MessageID "SPECIFIC";
BA_ "SigType" SG_ 2147613954 WindReference "DISCRETE";
BA_ "SigType" SG_ 2147613954 WindDirection "RANGE";
BA_ "SigType" SG_ 2147613954 WindSeed "RANGE";
BA_ "SigType" SG_ 2147613954 SequenceID "RANGE";
BA_ "SigType" SG_ 2147613702 StationASF "RANGE";
BA_ "SigType" SG_ 2147613702 StationECD "RANGE";
BA_ "SigType" SG_ 2147613702 StationSNR "RANGE";
BA_ "SigType" SG_ 2147613702 StationIdentifier "SPECIFIC";
BA_ "SigType" SG_ 2147613702 GroupRepetitionRate "RANGE";
BA_ "SigType" SG_ 2147613701 Mode "DISCRETE";
BA_ "SigType" SG_ 2147613701 StationStatusZ "DISCRETE";
BA_ "SigType" SG_ 2147613701 StationStatusY "DISCRETE";
BA_ "SigType" SG_ 2147613701 StationStatusX "DISCRETE";
BA_ "SigType" SG_ 2147613701 StationStatusW "DISCRETE";
BA_ "SigType" SG_ 2147613701 StationStatusV "DISCRETE";
BA_ "SigType" SG_ 2147613701 StationStatusMaster "DISCRETE";
BA_ "SigType" SG_ 2147613701 ZSecondaryRange "RANGE";
BA_ "SigType" SG_ 2147613701 YSecondaryRange "RANGE";
BA_ "SigType" SG_ 2147613701 XSecondaryRange "RANGE";
BA_ "SigType" SG_ 2147613701 WSecondaryRange "RANGE";
BA_ "SigType" SG_ 2147613701 VSecondaryRange "RANGE";
BA_ "SigType" SG_ 2147613701 MasterRange "RANGE";
BA_ "SigType" SG_ 2147613701 GroupRepetitionInterval "RANGE";
BA_ "SigType" SG_ 2147613700 Mode "DISCRETE";
BA_ "SigType" SG_ 2147613700 StationStatusZ "DISCRETE";
BA_ "SigType" SG_ 2147613700 StationStatusY "DISCRETE";
BA_ "SigType" SG_ 2147613700 StationStatusX "DISCRETE";
BA_ "SigType" SG_ 2147613700 StationStatusW "DISCRETE";
BA_ "SigType" SG_ 2147613700 StationStatusV "DISCRETE";
BA_ "SigType" SG_ 2147613700 StationStatusMaster "DISCRETE";
BA_ "SigType" SG_ 2147613700 ZSecondaryTD "RANGE";
BA_ "SigType" SG_ 2147613700 YSecondaryTD "RANGE";
BA_ "SigType" SG_ 2147613700 XSecondaryTD "RANGE";
BA_ "SigType" SG_ 2147613700 WSecondaryTD "RANGE";
BA_ "SigType" SG_ 2147613700 VSecondaryTD "RANGE";
BA_ "SigType" SG_ 2147613700 MasterRange "RANGE";
BA_ "SigType" SG_ 2147613700 GroupRepetitionInterval "RANGE";
BA_ "SigType" SG_ 2147613456 ProposedTxFrequencyChannel6 "RANGE";
BA_ "SigType" SG_ 2147613456 ProposedTxFrequencyChannel5 "RANGE";
BA_ "SigType" SG_ 2147613456 ProposedTxFrequencyChannel4 "RANGE";
BA_ "SigType" SG_ 2147613456 ProposedTxFrequencyChannel3 "RANGE";
BA_ "SigType" SG_ 2147613456 ProposedTxFrequencyChannel2 "RANGE";
BA_ "SigType" SG_ 2147613456 ProposedTxFrequencyChannel1 "RANGE";
BA_ "SigType" SG_ 2147613456 ProposedRxFrequencyChannel6 "RANGE";
BA_ "SigType" SG_ 2147613456 ProposedRxFrequencyChannel5 "RANGE";
BA_ "SigType" SG_ 2147613456 ProposedRxFrequencyChannel4 "RANGE";
BA_ "SigType" SG_ 2147613456 ProposedRxFrequencyChannel3 "RANGE";
BA_ "SigType" SG_ 2147613456 ProposedRxFrequencyChannel2 "RANGE";
BA_ "SigType" SG_ 2147613456 ProposedRxFrequencyChannel1 "RANGE";
BA_ "SigType" SG_ 2147613456 SubsequentCommunicationMode "RANGE";
BA_ "SigType" SG_ 2147613456 NatureOfDistress "RANGE";
BA_ "SigType" SG_ 2147613456 DSCMessageAddress5 "RANGE";
BA_ "SigType" SG_ 2147613456 DSCMessageAddress4 "RANGE";
BA_ "SigType" SG_ 2147613456 DSCMessageAddress3 "RANGE";
BA_ "SigType" SG_ 2147613456 DSCMessageAddress2 "RANGE";
BA_ "SigType" SG_ 2147613456 DSCMessageAddress1 "RANGE";
BA_ "SigType" SG_ 2147613456 DSCCategorySymbol "RANGE";
BA_ "SigType" SG_ 2147613456 DSCFormatSymbol "RANGE";
BA_ "SigType" SG_ 2147613447 ChannelBandwidth "RANGE";
BA_ "SigType" SG_ 2147613447 Mode "SPECIFIC";
BA_ "SigType" SG_ 2147613447 TxPower "RANGE";
BA_ "SigType" SG_ 2147613447 RadioChannel6 "RANGE";
BA_ "SigType" SG_ 2147613447 RadioChannel5 "RANGE";
BA_ "SigType" SG_ 2147613447 RadioChannel4 "RANGE";
BA_ "SigType" SG_ 2147613447 RadioChannel3 "RANGE";
BA_ "SigType" SG_ 2147613447 RadioChannel2 "RANGE";
BA_ "SigType" SG_ 2147613447 RadioChannel1 "RANGE";
BA_ "SigType" SG_ 2147613447 TxFrequency "RANGE";
BA_ "SigType" SG_ 2147613447 RxFrequency "RANGE";
BA_ "SigType" SG_ 2147613204 tnAtau "RANGE";
BA_ "SigType" SG_ 2147613204 tcA "RANGE";
BA_ "SigType" SG_ 2147613204 inADelta "RANGE";
BA_ "SigType" SG_ 2147613204 nALambda "RANGE";
BA_ "SigType" SG_ 2147613204 tnA "RANGE";
BA_ "SigType" SG_ 2147613204 TnADelta "RANGE";
BA_ "SigType" SG_ 2147613204 nAOmega "SPECIFIC";
BA_ "SigType" SG_ 2147613204 DOTDeltaTnA "SPECIFIC";
BA_ "SigType" SG_ 2147613204 nAEpsilon "RANGE";
BA_ "SigType" SG_ 2147613204 HnA "DISCRETE";
BA_ "SigType" SG_ 2147613204 CnA "DISCRETE";
BA_ "SigType" SG_ 2147613204 NA "RANGE";
BA_ "SigType" SG_ 2147613204 PRN "SPECIFIC";
BA_ "SigType" SG_ 2147613199 SatelliteServiceIDNumber "SPECIFIC";
BA_ "SigType" SG_ 2147613199 TimeSinceLastSatDiffSync "RANGE";
BA_ "SigType" SG_ 2147613199 DifferentialSource "DISCRETE";
BA_ "SigType" SG_ 2147613199 UsedAsCorrectionSource "DISCRETE";
BA_ "SigType" SG_ 2147613199 BitRate "DISCRETE";
BA_ "SigType" SG_ 2147613199 StationID "SPECIFIC";
BA_ "SigType" SG_ 2147613199 StationType "DISCRETE";
BA_ "SigType" SG_ 2147613199 Frequency "RANGE";
BA_ "SigType" SG_ 2147613199 SignalSNR "RANGE";
BA_ "SigType" SG_ 2147613199 SignalStrength "RANGE";
BA_ "SigType" SG_ 2147613199 Channel "RANGE";
BA_ "SigType" SG_ 2147613199 SID "SPECIFIC";
BA_ "SigType" SG_ 2147613198 DifferentialOperationMode "DISCRETE";
BA_ "SigType" SG_ 2147613198 DifferentialSource "DISCRETE";
BA_ "SigType" SG_ 2147613198 Mode "DISCRETE";
BA_ "SigType" SG_ 2147613198 BitRate "DISCRETE";
BA_ "SigType" SG_ 2147613198 Frequency "RANGE";
BA_ "SigType" SG_ 2147613198 Channel "SPECIFIC";
BA_ "SigType" SG_ 2147613197 IOD "RANGE";
BA_ "SigType" SG_ 2147613197 UDRE "RANGE";
BA_ "SigType" SG_ 2147613197 RRC "SPECIFIC";
BA_ "SigType" SG_ 2147613197 PRC "RANGE";
BA_ "SigType" SG_ 2147613197 SatelliteID "RANGE";
BA_ "SigType" SG_ 2147613197 StationHealth "DISCRETE";
BA_ "SigType" SG_ 2147613197 TimeOfCorrections "RANGE";
BA_ "SigType" SG_ 2147613197 ReferenceStationType "DISCRETE";
BA_ "SigType" SG_ 2147613197 ReferenceStationID "SPECIFIC";
BA_ "SigType" SG_ 2147613197 SequenceID "RANGE";
BA_ "SigType" SG_ 2147613195 StdDevAltitudeError "RANGE";
BA_ "SigType" SG_ 2147613195 StdDevLongitudeError "RANGE";
BA_ "SigType" SG_ 2147613195 StdDevLatitudeError "RANGE";
BA_ "SigType" SG_ 2147613195 OrientationOfErrorEllipse "RANGE";
BA_ "SigType" SG_ 2147613195 StdDevMinorErrorEllipse "RANGE";
BA_ "SigType" SG_ 2147613195 StdDevMajorErrorEllipse "RANGE";
BA_ "SigType" SG_ 2147613195 RmsStdDevOfRangeInputs "RANGE";
BA_ "SigType" SG_ 2147613195 SequenceID "RANGE";
BA_ "SigType" SG_ 2147613194 PseudorangeResidualFilteringTime "RANGE";
BA_ "SigType" SG_ 2147613194 ProbabilityOfMissedDetection "RANGE";
BA_ "SigType" SG_ 2147613194 ProbabilityOfFalseAlarm "RANGE";
BA_ "SigType" SG_ 2147613194 RadialPositionErrorMaxThresshold "RANGE";
BA_ "SigType" SG_ 2147613193 StdDeviationOfBias "RANGE";
BA_ "SigType" SG_ 2147613193 EstimateOfPseudorangeBias "RANGE";
BA_ "SigType" SG_ 2147613193 ProbatilityOfMissedDetection "RANGE";
BA_ "SigType" SG_ 2147613193 SVIDofMostLikelyFailedSat "RANGE";
BA_ "SigType" SG_ 2147613193 AltitudeExpectedError "RANGE";
BA_ "SigType" SG_ 2147613193 LatitudeExpectedError "DISCRETE";
BA_ "SigType" SG_ 2147613193 IntegrityFlag "DISCRETE";
BA_ "SigType" SG_ 2147613193 SequenceID "RANGE";
BA_ "SigType" SG_ 2147613190 STDAltitudeError "RANGE";
BA_ "SigType" SG_ 2147613190 STDLongitudeError "RANGE";
BA_ "SigType" SG_ 2147613190 STDLatitudeError "RANGE";
BA_ "SigType" SG_ 2147613190 OrientationMajorAxis "RANGE";
BA_ "SigType" SG_ 2147613190 STDMinorAxis "RANGE";
BA_ "SigType" SG_ 2147613190 STDMajorAxis "RANGE";
BA_ "SigType" SG_ 2147613190 RMSOfPositionUncertainty "RANGE";
BA_ "SigType" SG_ 2147613190 SID "SPECIFIC";
BA_ "SigType" SG_ 2147613189 ClockParameter2 "SPECIFIC";
BA_ "SigType" SG_ 2147613189 ClockParameter1 "SPECIFIC";
BA_ "SigType" SG_ 2147613189 MeanAnomaly "RANGE";
BA_ "SigType" SG_ 2147613189 LongitudeOfAscensionNode "RANGE";
BA_ "SigType" SG_ 2147613189 ArgumentOfPerigee "RANGE";
BA_ "SigType" SG_ 2147613189 RootSemiMajorAxis "RANGE";
BA_ "SigType" SG_ 2147613189 RateOfRightAscension "RANGE";
BA_ "SigType" SG_ 2147613189 InclinationAngle "RANGE";
BA_ "SigType" SG_ 2147613189 AlmanacReferenceTime "RANGE";
BA_ "SigType" SG_ 2147613189 Eccentricity "RANGE";
BA_ "SigType" SG_ 2147613189 SVHealthBits "SPECIFIC";
BA_ "SigType" SG_ 2147613189 GPSWeekNumber "RANGE";
BA_ "SigType" SG_ 2147613189 PRN "SPECIFIC";
BA_ "SigType" SG_ 2147613188 PNRStatus2 "DISCRETE";
BA_ "SigType" SG_ 2147613188 SNR2 "RANGE";
BA_ "SigType" SG_ 2147613188 Azimuth2 "RANGE";
BA_ "SigType" SG_ 2147613188 Elevation2 "RANGE";
BA_ "SigType" SG_ 2147613188 PRN2 "SPECIFIC";
BA_ "SigType" SG_ 2147613188 PNRStatus1 "DISCRETE";
BA_ "SigType" SG_ 2147613188 RangeResiduals1 "RANGE";
BA_ "SigType" SG_ 2147613188 SNR1 "RANGE";
BA_ "SigType" SG_ 2147613188 Azimuth1 "RANGE";
BA_ "SigType" SG_ 2147613188 Elevation1 "RANGE";
BA_ "SigType" SG_ 2147613188 NumberOfSVs "SPECIFIC";
BA_ "SigType" SG_ 2147613188 Mode "DISCRETE";
BA_ "SigType" SG_ 2147613188 SID "SPECIFIC";
BA_ "SigType" SG_ 2147613187 TDOP "RANGE";
BA_ "SigType" SG_ 2147613187 VDOP "RANGE";
BA_ "SigType" SG_ 2147613187 HDOP "RANGE";
BA_ "SigType" SG_ 2147613187 OpMode "DISCRETE";
BA_ "SigType" SG_ 2147613187 SetMode "DISCRETE";
BA_ "SigType" SG_ 2147613187 SID "DISCRETE";
BA_ "SigType" SG_ 2147613186 UseAntennaAltitudeFor2DMode "DISCRETE";
BA_ "SigType" SG_ 2147613186 AntennaAltitudeFor2DMode "RANGE";
BA_ "SigType" SG_ 2147613186 MaxCorrectionAge "RANGE";
BA_ "SigType" SG_ 2147613186 PositionVelocityFilter "DISCRETE";
BA_ "SigType" SG_ 2147613186 DGNSSMode "DISCRETE";
BA_ "SigType" SG_ 2147613186 GNNSMode "DISCRETE";
BA_ "SigType" SG_ 2147613186 SNRMask "RANGE";
BA_ "SigType" SG_ 2147613186 PDOPSwitch "RANGE";
BA_ "SigType" SG_ 2147613186 PDOPMask "RANGE";
BA_ "SigType" SG_ 2147613186 SVElevation "RANGE";
BA_ "SigType" SG_ 2147612950 DestinationMarkId "RANGE";
BA_ "SigType" SG_ 2147612950 OriginMarkId "RANGE";
BA_ "SigType" SG_ 2147612950 DestinationMarkType "DISCRETE";
BA_ "SigType" SG_ 2147612950 OriginMarkType "DISCRETE";
BA_ "SigType" SG_ 2147612950 Distance "RANGE";
BA_ "SigType" SG_ 2147612950 Bearing_OrigToDest "RANGE";
BA_ "SigType" SG_ 2147612950 CalculationType "DISCRETE";
BA_ "SigType" SG_ 2147612950 BearingRef "DISCRETE";
BA_ "SigType" SG_ 2147612950 SID "DISCRETE";
BA_ "SigType" SG_ 2147612949 MarkID "RANGE";
BA_ "SigType" SG_ 2147612949 MarkType "DISCRETE";
BA_ "SigType" SG_ 2147612949 TimeElapsed "RANGE";
BA_ "SigType" SG_ 2147612949 SID "SPECIFIC";
BA_ "SigType" SG_ 2147612939 Drift "RANGE";
BA_ "SigType" SG_ 2147612939 Set "RANGE";
BA_ "SigType" SG_ 2147612939 SetRef "DISCRETE";
BA_ "SigType" SG_ 2147612939 SID "SPECIFIC";
BA_ "SigType" SG_ 2147612932 WaypointClosingVelocity "RANGE";
BA_ "SigType" SG_ 2147612932 DestWaypointLongitude "RANGE";
BA_ "SigType" SG_ 2147612932 DestWaypointLatitude "RANGE";
BA_ "SigType" SG_ 2147612932 DestWaypointNumber "RANGE";
BA_ "SigType" SG_ 2147612932 OrigWaypointNumber "RANGE";
BA_ "SigType" SG_ 2147612932 Bearing_PosToDest "RANGE";
BA_ "SigType" SG_ 2147612932 Bearing_OrigToDest "RANGE";
BA_ "SigType" SG_ 2147612932 ETADate "RANGE";
BA_ "SigType" SG_ 2147612932 ETA_Time "RANGE";
BA_ "SigType" SG_ 2147612932 CalculationType "DISCRETE";
BA_ "SigType" SG_ 2147612932 ArrivalCircleEnterd "DISCRETE";
BA_ "SigType" SG_ 2147612932 PerpendCrossed "DISCRETE";
BA_ "SigType" SG_ 2147612932 CourseBearingRef "DISCRETE";
BA_ "SigType" SG_ 2147612932 DistanceToDestWaypoint "RANGE";
BA_ "SigType" SG_ 2147612932 SID "SPECIFIC";
BA_ "SigType" SG_ 2147612931 XTE "RANGE";
BA_ "SigType" SG_ 2147612931 HeadingRef "DISCRETE";
BA_ "SigType" SG_ 2147612931 XTEMode "DISCRETE";
BA_ "SigType" SG_ 2147612931 SID "SPECIFIC";
BA_ "SigType" SG_ 2147612693 DatumName "SPECIFIC";
BA_ "SigType" SG_ 2147612693 EllipsoidFlateningInverse "RANGE";
BA_ "SigType" SG_ 2147612693 EllipsoidSemiMajorAxis "RANGE";
BA_ "SigType" SG_ 2147612693 Scale "RANGE";
BA_ "SigType" SG_ 2147612693 RotationZ "RANGE";
BA_ "SigType" SG_ 2147612693 RotationY "RANGE";
BA_ "SigType" SG_ 2147612693 RotationX "RANGE";
BA_ "SigType" SG_ 2147612693 DeltaZ "RANGE";
BA_ "SigType" SG_ 2147612693 DeltaY "RANGE";
BA_ "SigType" SG_ 2147612693 DeltaX "RANGE";
BA_ "SigType" SG_ 2147612692 ReferenceDatum "SPECIFIC";
BA_ "SigType" SG_ 2147612692 DeltaAltitude "RANGE";
BA_ "SigType" SG_ 2147612692 DeltaLongitude "RANGE";
BA_ "SigType" SG_ 2147612692 DeltaLatitude "RANGE";
BA_ "SigType" SG_ 2147612692 LocalDatum "RANGE";
BA_ "SigType" SG_ 2147612681 LocalOffsetMinutes "RANGE";
BA_ "SigType" SG_ 2147612681 TimeOfDay "RANGE";
BA_ "SigType" SG_ 2147612681 Date "RANGE";
BA_ "SigType" SG_ 2147612677 AgeOfDGNSSRefStation2 "RANGE";
BA_ "SigType" SG_ 2147612677 RefStationId2 "SPECIFIC";
BA_ "SigType" SG_ 2147612677 RefStationType2 "DISCRETE";
BA_ "SigType" SG_ 2147612677 AgeOfDGNSSRefStation1 "RANGE";
BA_ "SigType" SG_ 2147612677 RefStationId1 "SPECIFIC";
BA_ "SigType" SG_ 2147612677 RefStationType1 "DISCRETE";
BA_ "SigType" SG_ 2147612677 NumberOfReferenceStations "SPECIFIC";
BA_ "SigType" SG_ 2147612677 GeoidalSeparation "RANGE";
BA_ "SigType" SG_ 2147612677 PDOP "RANGE";
BA_ "SigType" SG_ 2147612677 HDOP "RANGE";
BA_ "SigType" SG_ 2147612677 NumberOfSVs "SPECIFIC";
BA_ "SigType" SG_ 2147612677 GNSSIntegrity "DISCRETE";
BA_ "SigType" SG_ 2147612677 MethodGNSS "DISCRETE";
BA_ "SigType" SG_ 2147612677 TypeOfSystem "DISCRETE";
BA_ "SigType" SG_ 2147612677 AltitudeHigh "SPECIFIC";
BA_ "SigType" SG_ 2147612677 AltitudeLow "SPECIFIC";
BA_ "SigType" SG_ 2147612677 LongitudeHigh "RANGE";
BA_ "SigType" SG_ 2147612677 LatitudeLow "RANGE";
BA_ "SigType" SG_ 2147612677 LatitudeHigh "RANGE";
BA_ "SigType" SG_ 2147612677 LongitudeLow "RANGE";
BA_ "SigType" SG_ 2147612677 PositionTime "RANGE";
BA_ "SigType" SG_ 2147612677 PositionDate "RANGE";
BA_ "SigType" SG_ 2147612677 SID "SPECIFIC";
BA_ "SigType" SG_ 2147612674 SpeedOverGround "RANGE";
BA_ "SigType" SG_ 2147612674 CourseOverGround "RANGE";
BA_ "SigType" SG_ 2147612674 COGReference "DISCRETE";
BA_ "SigType" SG_ 2147612674 SID "SPECIFIC";
BA_ "SigType" SG_ 2147612673 Longitude "RANGE";
BA_ "SigType" SG_ 2147612673 Latitude "RANGE";
BA_ "SigType" SG_ 2147612173 ChannelNumber "RANGE";
BA_ "SigType" SG_ 2147612173 UAISSpareBits "SPECIFIC";
BA_ "SigType" SG_ 2147612173 CommunicationState "DISCRETE";
BA_ "SigType" SG_ 2147612173 Latitude "RANGE";
BA_ "SigType" SG_ 2147612173 Longitude "RANGE";
BA_ "SigType" SG_ 2147612173 Date "RANGE";
BA_ "SigType" SG_ 2147612173 TimeOfDay "RANGE";
BA_ "SigType" SG_ 2147612173 MaritimeMobileServiceIDNumber "RANGE";
BA_ "SigType" SG_ 2147612173 PositionAccuracy "DISCRETE";
BA_ "SigType" SG_ 2147612173 RepeatIndicator "DISCRETE";
BA_ "SigType" SG_ 2147612173 ElectronicPositionFixingDevice "DISCRETE";
BA_ "SigType" SG_ 2147612173 MessageID "SPECIFIC";
BA_ "SigType" SG_ 2147612172 ChannelNumber "RANGE";
BA_ "SigType" SG_ 2147612172 UAISReserveBits "DISCRETE";
BA_ "SigType" SG_ 2147612172 PositionalMode "DISCRETE";
BA_ "SigType" SG_ 2147612172 RepeatIndicator "DISCRETE";
BA_ "SigType" SG_ 2147612172 RegionalApplicationID "DISCRETE";
BA_ "SigType" SG_ 2147612172 CommunicationsState "DISCRETE";
BA_ "SigType" SG_ 2147612172 HeadingSource "DISCRETE";
BA_ "SigType" SG_ 2147612172 HeadingReference "DISCRETE";
BA_ "SigType" SG_ 2147612172 TimeOfDay "RANGE";
BA_ "SigType" SG_ 2147612172 Heading "RANGE";
BA_ "SigType" SG_ 2147612172 CourseOverGround "RANGE";
BA_ "SigType" SG_ 2147612172 Latitude "RANGE";
BA_ "SigType" SG_ 2147612172 Longitude "RANGE";
BA_ "SigType" SG_ 2147612172 RateOfTurn "RANGE";
BA_ "SigType" SG_ 2147612172 PositionAccuracy "DISCRETE";
BA_ "SigType" SG_ 2147612172 NavigationStatus "DISCRETE";
BA_ "SigType" SG_ 2147612172 DataAvailable "DISCRETE";
BA_ "SigType" SG_ 2147612172 DataTerminalEquipmentAvailable "DISCRETE";
BA_ "SigType" SG_ 2147612172 MaritimeMobileServiceIdNumber "SPECIFIC";
BA_ "SigType" SG_ 2147612172 MessageID "SPECIFIC";
BA_ "SigType" SG_ 2147612168 ReferenceTarget "RANGE";
BA_ "SigType" SG_ 2147612168 Name "RANGE";
BA_ "SigType" SG_ 2147612168 UTCofFix "RANGE";
BA_ "SigType" SG_ 2147612168 TCPA "RANGE";
BA_ "SigType" SG_ 2147612168 CPA "RANGE";
BA_ "SigType" SG_ 2147612168 Speed "RANGE";
BA_ "SigType" SG_ 2147612168 Course "RANGE";
BA_ "SigType" SG_ 2147612168 Distance "RANGE";
BA_ "SigType" SG_ 2147612168 Bearing "RANGE";
BA_ "SigType" SG_ 2147612168 BearingReference "DISCRETE";
BA_ "SigType" SG_ 2147612168 Acquision "DISCRETE";
BA_ "SigType" SG_ 2147612168 ReportedTarget "DISCRETE";
BA_ "SigType" SG_ 2147612168 TrackStatus "DISDRETE";
BA_ "SigType" SG_ 2147612168 TargetId "RANGE";
BA_ "SigType" SG_ 2147612168 SequenceID "RANGE";
BA_ "SigType" SG_ 2147611923 DistanceSinceLastReset "RANGE";
BA_ "SigType" SG_ 2147611923 TotalCumulativeDistance "RANGE";
BA_ "SigType" SG_ 2147611923 MeasurementTime "RANGE";
BA_ "SigType" SG_ 2147611923 MeasurementDate "SPECIFIC";
BA_ "SigType" SG_ 2147611915 Offset "RANGE";
BA_ "SigType" SG_ 2147611915 WaterDepthTransducer "RANGE";
BA_ "SigType" SG_ 2147611915 SID "SPECIFIC";
BA_ "SigType" SG_ 2147611907 SpeedGroundReferenced "RANGE";
BA_ "SigType" SG_ 2147611907 SpeedWaterReferenced "RANGE";
BA_ "SigType" SG_ 2147611907 SID "SPECIFIC";
BA_ "SigType" SG_ 2147611156 BatteryCaseTemp "RANGE";
BA_ "SigType" SG_ 2147611156 BatteryCurrent "RANGE";
BA_ "SigType" SG_ 2147611156 BatteryPotential "RANGE";
BA_ "SigType" SG_ 2147611156 BatteryInstance "SPECIFIC";
BA_ "SigType" SG_ 2147611153 FluidLevel "RANGE";
BA_ "SigType" SG_ 2147611153 FluidType "DISCRETE";
BA_ "SigType" SG_ 2147611153 FluidInstance "RANGE";
BA_ "SigType" SG_ 2147611150 Switch28 "DISCRETE";
BA_ "SigType" SG_ 2147611150 Switch27 "DISCRETE";
BA_ "SigType" SG_ 2147611150 Switch26 "DISCRETE";
BA_ "SigType" SG_ 2147611150 Switch25 "DISCRETE";
BA_ "SigType" SG_ 2147611150 Switch24 "DISCRETE";
BA_ "SigType" SG_ 2147611150 Switch23 "DISCRETE";
BA_ "SigType" SG_ 2147611150 Switch22 "DISCRETE";
BA_ "SigType" SG_ 2147611150 Switch21 "DISCRETE";
BA_ "SigType" SG_ 2147611150 Switch20 "DISCRETE";
BA_ "SigType" SG_ 2147611150 Switch19 "DISCRETE";
BA_ "SigType" SG_ 2147611150 Switch18 "DISCRETE";
BA_ "SigType" SG_ 2147611150 Switch17 "DISCRETE";
BA_ "SigType" SG_ 2147611150 Switch16 "DISCRETE";
BA_ "SigType" SG_ 2147611150 Switch15 "DISCRETE";
BA_ "SigType" SG_ 2147611150 Switch14 "DISCRETE";
BA_ "SigType" SG_ 2147611150 Switch13 "DISCRETE";
BA_ "SigType" SG_ 2147611150 Switch12 "DISCRETE";
BA_ "SigType" SG_ 2147611150 Switch11 "DISCRETE";
BA_ "SigType" SG_ 2147611150 Switch10 "DISCRETE";
BA_ "SigType" SG_ 2147611150 Switch9 "DISCRETE";
BA_ "SigType" SG_ 2147611150 Switch8 "DISCRETE";
BA_ "SigType" SG_ 2147611150 Switch7 "DISCRETE";
BA_ "SigType" SG_ 2147611150 Switch6 "DISCRETE";
BA_ "SigType" SG_ 2147611150 Switch5 "DISCRETE";
BA_ "SigType" SG_ 2147611150 Switch4 "DISCRETE";
BA_ "SigType" SG_ 2147611150 Switch3 "DISCRETE";
BA_ "SigType" SG_ 2147611150 Switch2 "DISCRETE";
BA_ "SigType" SG_ 2147611150 Switch1 "DISCRETE";
BA_ "SigType" SG_ 2147611150 SwitchBankInstance "SPECIFIC";
BA_ "SigType" SG_ 2147611149 Indicator28 "DISCRETE";
BA_ "SigType" SG_ 2147611149 Indicator27 "DISCRETE";
BA_ "SigType" SG_ 2147611149 Indicator26 "DISCRETE";
BA_ "SigType" SG_ 2147611149 Indicator25 "DISCRETE";
BA_ "SigType" SG_ 2147611149 Indicator24 "DISCRETE";
BA_ "SigType" SG_ 2147611149 Indicator23 "DISCRETE";
BA_ "SigType" SG_ 2147611149 Indicator22 "DISCRETE";
BA_ "SigType" SG_ 2147611149 Indicator21 "DISCRETE";
BA_ "SigType" SG_ 2147611149 Indicator20 "DISCRETE";
BA_ "SigType" SG_ 2147611149 Indicator19 "DISCRETE";
BA_ "SigType" SG_ 2147611149 Indicator18 "DISCRETE";
BA_ "SigType" SG_ 2147611149 Indicator17 "DISCRETE";
BA_ "SigType" SG_ 2147611149 Indicator16 "DISCRETE";
BA_ "SigType" SG_ 2147611149 Indicator15 "DISCRETE";
BA_ "SigType" SG_ 2147611149 Indicator14 "DISCRETE";
BA_ "SigType" SG_ 2147611149 Indicator13 "DISCRETE";
BA_ "SigType" SG_ 2147611149 Indicator12 "DISCRETE";
BA_ "SigType" SG_ 2147611149 Indicator11 "DISCRETE";
BA_ "SigType" SG_ 2147611149 Indicator10 "DISCRETE";
BA_ "SigType" SG_ 2147611149 Indicator9 "DISCRETE";
BA_ "SigType" SG_ 2147611149 Indicator8 "DISCRETE";
BA_ "SigType" SG_ 2147611149 Indicator7 "DISCRETE";
BA_ "SigType" SG_ 2147611149 Indicator6 "DISCRETE";
BA_ "SigType" SG_ 2147611149 Indicator5 "DISCRETE";
BA_ "SigType" SG_ 2147611149 Indicator4 "DISCRETE";
BA_ "SigType" SG_ 2147611149 Indicator3 "DISCRETE";
BA_ "SigType" SG_ 2147611149 Indicator2 "DISCRETE";
BA_ "SigType" SG_ 2147611149 Indicator1 "DISCRETE";
BA_ "SigType" SG_ 2147611149 IndicatorBankInstance "SPECIFIC";
BA_ "SigType" SG_ 2147611146 VIN "SPECIFIC";
BA_ "SigType" SG_ 2147611146 RatedEngineSpeed "RANGE";
BA_ "SigType" SG_ 2147611146 EngineInstance "RANGE";
BA_ "SigType" SG_ 2147611145 TripFuelUsed "RANGE";
BA_ "SigType" SG_ 2147611145 TripRunTime "RANGE";
BA_ "SigType" SG_ 2147611145 EngineInstance "SPECIFIC";
BA_ "SigType" SG_ 2147611141 SailDrive "DISCRETE";
BA_ "SigType" SG_ 2147611141 LowOilLevel "DISCRETE";
BA_ "SigType" SG_ 2147611141 LowOilPressure "DISCRETE";
BA_ "SigType" SG_ 2147611141 OverTemperature "DISCRETE";
BA_ "SigType" SG_ 2147611141 CheckTransmission "DISCRETE";
BA_ "SigType" SG_ 2147611141 TransOilTemperature "RANGE";
BA_ "SigType" SG_ 2147611141 TransOilPressure "RANGE";
BA_ "SigType" SG_ 2147611141 TransmissionGear "DISCRETE";
BA_ "SigType" SG_ 2147611141 TransmissionInstance "DISCRETE";
BA_ "SigType" SG_ 2147611137 EngineEmergencyStopMode "DISCRETE";
BA_ "SigType" SG_ 2147611137 ThrottlePositionSensor "DISCRETE";
BA_ "SigType" SG_ 2147611137 EGRSystem "DISCRETE";
BA_ "SigType" SG_ 2147611137 RevLimitExceeded "DISCRETE";
BA_ "SigType" SG_ 2147611137 HightBoostPressure "DISCRETE";
BA_ "SigType" SG_ 2147611137 PreheatIndicator "DISCRETE";
BA_ "SigType" SG_ 2147611137 ChargeIndicator "DISCRETE";
BA_ "SigType" SG_ 2147611137 WaterInFuel "DISCRETE";
BA_ "SigType" SG_ 2147611137 WaterFlow "DISCRETE";
BA_ "SigType" SG_ 2147611137 LowCoolantLevel "DISCRETE";
BA_ "SigType" SG_ 2147611137 LowSystemVoltage "DISCRETE";
BA_ "SigType" SG_ 2147611137 LowFuelPressure "DISCRETE";
BA_ "SigType" SG_ 2147611137 LowOilLevel "DISCRETE";
BA_ "SigType" SG_ 2147611137 LowOilPressure "DISCRETE";
BA_ "SigType" SG_ 2147611137 OverTemperature "DISCRETE";
BA_ "SigType" SG_ 2147611137 CheckEngine "DISCRETE";
BA_ "SigType" SG_ 2147611137 EngineTiltTrime "RANGE";
BA_ "SigType" SG_ 2147611137 FuelPressure "RANGE";
BA_ "SigType" SG_ 2147611137 EngineCoolantPressure "RANGE";
BA_ "SigType" SG_ 2147611137 TotalEngineHours "RANGE";
BA_ "SigType" SG_ 2147611137 FuelRate "RANGE";
BA_ "SigType" SG_ 2147611137 AlternatorPotential "RANGE";
BA_ "SigType" SG_ 2147611137 EngineCoolantTemp "RANGE";
BA_ "SigType" SG_ 2147611137 EngineOilTemp "RANGE";
BA_ "SigType" SG_ 2147611137 EngineOilPressure "RANGE";
BA_ "SigType" SG_ 2147611137 EngineInstance "DISCRETE";
BA_ "SigType" SG_ 2147611136 EngineBoostPressure "RANGE";
BA_ "SigType" SG_ 2147611136 EngineSpeed "RANGE";
BA_ "SigType" SG_ 2147611136 EngineInstance "DISCRETE";
BA_ "SigType" SG_ 2147610905 Roll "RANGE";
BA_ "SigType" SG_ 2147610905 Pitch "RANGE";
BA_ "SigType" SG_ 2147610905 Yaw "RANGE";
BA_ "SigType" SG_ 2147610905 SID "SPECIFIC";
BA_ "SigType" SG_ 2147610898 HeadingSensorRef "DISCRETE";
BA_ "SigType" SG_ 2147610898 Variation "RANGE";
BA_ "SigType" SG_ 2147610898 Deviation "RANGE";
BA_ "SigType" SG_ 2147610898 HeadingSensorReading "RANGE";
BA_ "SigType" SG_ 2147610898 SID "SPECIFIC";
BA_ "SigType" SG_ 2147610896 ControlStaionState "DISCRETE";
BA_ "SigType" SG_ 2147610896 ControlMethod "DISCRETE";
BA_ "SigType" SG_ 2147610896 ControlStationFunction "DISCRETE";
BA_ "SigType" SG_ 2147610896 ControlStaionNetworkAddress "SPECIFIC";
BA_ "SigType" SG_ 2147610893 Position "RANGE";
BA_ "SigType" SG_ 2147610893 AngleOrder "RANGE";
BA_ "SigType" SG_ 2147610893 DirectionOrder "DISCRETE";
BA_ "SigType" SG_ 2147610893 RudderInstance "DISCRETE";
BA_ "SigType" SG_ 2147610644 ManufacturersProductCode "SPECIFIC";
BA_ "SigType" SG_ 2147610644 NMEA2000Version "SPECIFIC";
BA_ "SigType" SG_ 2147610640 Time "RANGE";
BA_ "SigType" SG_ 2147610640 Date "RANGE";
BA_ "SigType" SG_ 2147610640 Source "SPECIFIC";
BA_ "SigType" SG_ 2147610640 SID "SPECIFIC";
BA_ "SigType" SG_ 2147610112 FirstPGNSupported "SPECIFIC";
BA_ "SigType" SG_ 2147610112 TransmittedPGNGroupFunctionCode "SPECIFIC";
BA_ "SigType" SG_ 2147609856 ValueofFirstRequestedParameter "SPECIFIC";
BA_ "SigType" SG_ 2147609856 FieldNumofReqParameter "SPECIFIC";
BA_ "SigType" SG_ 2147609856 NumPairsofReqParametersToFollow "SPECIFIC";
BA_ "SigType" SG_ 2147609856 TransmissionIntervalOffset "RANGE";
BA_ "SigType" SG_ 2147609856 ValueOfFirstCommandParameter "SPECIFIC";
BA_ "SigType" SG_ 2147609856 FieldNumFirstCommandParameter "SPECIFIC";
BA_ "SigType" SG_ 2147609856 FirstParameterErrorCode "DISCRETE";
BA_ "SigType" SG_ 2147609856 NumPairsCommandedParamFollow "SPECIFIC";
BA_ "SigType" SG_ 2147609856 NumberOfParameters "RANGE";
BA_ "SigType" SG_ 2147609856 TransmissionIntervalErrorCode "DISCRETE";
BA_ "SigType" SG_ 2147609856 TransmissionInterval "RANGE";
BA_ "SigType" SG_ 2147609856 PrioritySetting "SPECIFIC";
BA_ "SigType" SG_ 2147609856 PGNErrorCode "DISCRETE";
BA_ "SigType" SG_ 2147609856 CommandedPGN "SPECIFIC";
BA_ "SigType" SG_ 2147609856 RequestedPGN "SPECIFIC";
BA_ "SigType" SG_ 2147609856 AcknowledgedPGN "SPECIFIC";
BA_ "SigType" SG_ 2147609856 GroupFunctionCode "DISCRETE";
BA_ "SigType" SG_ 2147609088 RequestedPGN "SPECIFIC";
BA_ "SigType" SG_ 2147548888 AddressAssignment "SPECIFIC";
BA_ "SigType" SG_ 2147548888 SelfConfigurableAddress "SPECIFIC";
BA_ "SigType" SG_ 2147548888 IndustryGroup "SPECIFIC";
BA_ "SigType" SG_ 2147548888 DeviceClassInstance "SPECIFIC";
BA_ "SigType" SG_ 2147548888 DeviceClass "SPECIFIC";
BA_ "SigType" SG_ 2147548888 Function "SPECIFIC";
BA_ "SigType" SG_ 2147548888 FunctionInstance "SPECIFIC";
BA_ "SigType" SG_ 2147548888 ECUInstance "SPECIFIC";
BA_ "SigType" SG_ 2147548888 ManufacturerCode "SPECIFIC";
BA_ "SigType" SG_ 2147548888 IdentityNumber "SPECIFIC";
BA_ "SigType" SG_ 2147544576 SelfConfigurableAddress "SPECIFIC";
BA_ "SigType" SG_ 2147544576 TFX_IndustryGroup "SPECIFIC";
BA_ "SigType" SG_ 2147544576 DeviceClassInstance "SPECIFIC";
BA_ "SigType" SG_ 2147544576 DeviceClass "SPECIFIC";
BA_ "SigType" SG_ 2147544576 Function "SPECIFIC";
BA_ "SigType" SG_ 2147544576 FunctionInstance "SPECIFIC";
BA_ "SigType" SG_ 2147544576 ECUInstance "SPECIFIC";
BA_ "SigType" SG_ 2147544576 ManufacturerCode "SPECIFIC";
BA_ "SigType" SG_ 2147544576 IdentityNumber "SPECIFIC";
BA_ "SigType" SG_ 2147544064 PGNumber "SPECIFIC";
BA_ "SigType" SG_ 2147544064 RtsNoPackets "SPECIFIC";
BA_ "SigType" SG_ 2147544064 AckNoPackets "SPECIFIC";
BA_ "SigType" SG_ 2147544064 NextPacket "SPECIFIC";
BA_ "SigType" SG_ 2147544064 RtsMsgSize "SPECIFIC";
BA_ "SigType" SG_ 2147544064 SendPackets "SPECIFIC";
BA_ "SigType" SG_ 2147544064 AckMsgSize "SPECIFIC";
BA_ "SigType" SG_ 2147544064 ControlByte "DISCRETE";
BA_ "SigType" SG_ 2147543808 Data7 "SPECIFIC";
BA_ "SigType" SG_ 2147543808 Data6 "SPECIFIC";
BA_ "SigType" SG_ 2147543808 Data5 "SPECIFIC";
BA_ "SigType" SG_ 2147543808 Data4 "SPECIFIC";
BA_ "SigType" SG_ 2147543808 Data3 "SPECIFIC";
BA_ "SigType" SG_ 2147543808 Data2 "SPECIFIC";
BA_ "SigType" SG_ 2147543808 Data1 "SPECIFIC";
BA_ "SigType" SG_ 2147543808 SeqNumber "SPECIFIC";
BA_ "SigType" SG_ 2147543552 RqstedPGN "SPECIFIC";
BA_ "SigType" SG_ 2147543040 PGNumber "SPECIFIC";
BA_ "SigType" SG_ 2147543040 CtrlByte "DISCRETE";
VAL_ 2680225687 TFX_Helm_State 4 "Poweroff" 3 "Calibration" 2 "Wait For brake Release" 1 "Hardover" 0 "Steering" ;
VAL_ 2680225687 TFX_Helm_Brake_State 5 "Off" 4 "Reverse Polarity" 3 "Torque Reduction" 2 "Hold" 1 "Peak" 0 "Steering" ;
VAL_ 2680225621 TFX_DangerFault 1 "Active" 0 "Inactive" ;
VAL_ 2680225621 TFX_Warning_Fault 1 "Active" 0 "Inactive" ;
VAL_ 2680225621 TFX_SourceInstance 1 "Stbd" 0 "Port" ;
VAL_ 2680225621 TFX_IndustryGroup 5 "IndustrialProcess" 3 "Construction" 2 "AgriculturalAndForestry" 0 "Global" 1 "OnHighway" 4 "Marine" ;
VAL_ 2680225621 TFX_Header 1850 "Teleflex" ;
VAL_ 2680225616 TFX_PCM_Command 5 "Store Stbd Helm Cal HS" 4 "Store Port Helm Cal HS" 3 "Init Helm Cal" 2 "Reset" 1 "Powerdown" 0 "No Command" ;
VAL_ 2680225616 TFX_IndustryGroup 5 "IndustrialProcess" 3 "Construction" 2 "AgriculturalAndForestry" 0 "Global" 1 "OnHighway" 4 "Marine" ;
VAL_ 2680225616 TFX_Header 1850 "Teleflex" ;
VAL_ 2147610885 CommandedRudderDirection 2 "MovePort" 1 "MoveStarboard" 0 "NoOrder" ;
VAL_ 2147610885 HeadingReference 3 "Null" 2 "Error" 1 "Magnetic" 0 "True" ;
VAL_ 2147610885 TurnMode 2 "RadiusControlled" 1 "TurnRateControlled" 0 "RudderLimitControlled" ;
VAL_ 2147610885 SteerigMode 5 "TrackControl" 4 "HeadingControl" 3 "HeadingControlStandalone" 2 "FollowUpDevice" 1 "NonFollowUpDevice" 0 "MainSteering" ;
VAL_ 2147610885 Override 1 "YES" 0 "NO" ;
VAL_ 2147610885 OffTrackLimitExceeded 3 "Unavailable" 2 "Error" 1 "YES" 0 "NO" ;
VAL_ 2147610885 OffheadingLimitExceeded 3 "Unavailable" 2 "Error" 1 "YES" 0 "NO" ;
VAL_ 2147610885 RudderLimitExceeded 3 "Unavailable" 2 "Error" 1 "YES" 0 "NO" ;
VAL_ 2185297681 TFX_SyncModeActive 1 "Yes" 0 "No" ;
VAL_ 2185297681 TFX_Shift_Instance 1 "Stbd" 0 "Port" ;
VAL_ 2185297681 TFX_Shift_Group 5 "Shift" 4 "Throttle" 1 "Command" ;
VAL_ 2185297681 TFX_Shift_Gear 3 "Not Available" 2 "Reverse" 1 "Neutral" 0 "Forward" ;
VAL_ 2680225657 TFX_ToeAngle 127 "Ignore" ;
VAL_ 2680225657 TFX_HelmResInDockMode 255 "Ignore" ;
VAL_ 2680225657 TFX_InnerOuterRatio 65535 "Ignore" ;
VAL_ 2680225657 TFX_HelmResInAPMode 255 "Ignore" ;
VAL_ 2680225657 TFX_IndustryGroup 5 "IndustrialProcess" 3 "Construction" 2 "AgriculturalAndForestry" 0 "Global" 1 "OnHighway" 4 "Marine" ;
VAL_ 2680225657 TFX_Header 1850 "Teleflex" ;
VAL_ 2680225656 TFX_CANtrakAdjustScreen 3 "Ignore" 1 "Enabled" 0 "Disabled" ;
VAL_ 2680225656 TFX_OptimusSystemType 3 "Ignore" 1 "Optimus 360" 0 "Optimus" ;
VAL_ 2680225656 TFX_HelmResHigh 255 "Ignore" ;
VAL_ 2680225656 TFX_HelmResLow 255 "Ignore" ;
VAL_ 2680225656 TFX_HelmTurnsHigh 255 "Ignore" ;
VAL_ 2680225656 TFX_HelmTurnsLow 255 "Ignore" ;
VAL_ 2680225656 TFX_IndustryGroup 5 "IndustrialProcess" 3 "Construction" 2 "AgriculturalAndForestry" 0 "Global" 1 "OnHighway" 4 "Marine" ;
VAL_ 2680225656 TFX_Header 1850 "Teleflex" ;
VAL_ 2149646097 TFX_SyncModeActive 1 "Yes" 0 "No" ;
VAL_ 2149646097 TFX_Shift_Instance 1 "Stbd" 0 "Port" ;
VAL_ 2149646097 TFX_Shift_Group 5 "Shift" 4 "Throttle" 1 "Command" ;
VAL_ 2149646097 TFX_Shift_Gear 3 "Not Available" 2 "Reverse" 1 "Neutral" 0 "Forward" ;
VAL_ 2680225641 TFX_ControlState_Act 15 "Not Available" 14 "Error" 5 "Freeze" 4 "Active" 3 "Calibration" 2 "Power Down" 1 "Inactive" ;
VAL_ 2680225641 TFX_WarningFault 1 "Active" 0 "Inactive" ;
VAL_ 2680225641 TFX_ThrUpMotionFault 1 "Active" 0 "Inactive" ;
VAL_ 2680225641 TFX_ThrDwnMotionFault 1 "Active" 0 "Inactive" ;
VAL_ 2680225641 TFX_ShiftRevMotionFault 1 "Active" 0 "Inactive" ;
VAL_ 2680225641 TFX_ShiftNeutMotionFault 1 "Active" 0 "Inactive" ;
VAL_ 2680225641 TFX_ShiftFwdMotionFault 1 "Active" 0 "Inactive" ;
VAL_ 2680225641 TFX_CriticalFault 1 "Active" 0 "Inactive" ;
VAL_ 2680225641 TFX_ActuatorType 3 "Not Available" 2 "EST Gateway" 1 "Throttle" 0 "Shift" ;
VAL_ 2680225641 TFX_ActualTrollingValveValue 255 "Not Available" 254 "Error" ;
VAL_ 2680225641 TFX_ActualThrottleValue 65535 "Not Available" 65534 "Error" ;
VAL_ 2680225641 TFX_ActualGearValue 15 "Not Available" 14 "Error" 2 "Reverse" 1 "Neutral" 0 "Forward" ;
VAL_ 2680225641 TFX_SourceInstance 1 "Stbd" 0 "Port" ;
VAL_ 2680225641 TFX_IndustryGroup 5 "IndustrialProcess" 3 "Construction" 2 "AgriculturalAndForestry" 0 "Global" 1 "OnHighway" 4 "Marine" ;
VAL_ 2680225641 TFX_Header 1850 "Teleflex" ;
VAL_ 2350972777 TFX_ControlState_Act 15 "Other" 0 "Startup" 3 "Motion Fault / Ntl-Idle" 2 "Calibration" 1 "Active" ;
VAL_ 2350972777 TFX_WarningFault 1 "Active" 0 "Inactive" ;
VAL_ 2350972777 TFX_ThrUpMotionFault 1 "Active" 0 "Inactive" ;
VAL_ 2350972777 TFX_ThrDwnMotionFault 1 "Active" 0 "Inactive" ;
VAL_ 2350972777 TFX_ShiftRevMotionFault 1 "Active" 0 "Inactive" ;
VAL_ 2350972777 TFX_ShiftNeutMotionFault 1 "Active" 0 "Inactive" ;
VAL_ 2350972777 TFX_ShiftFwdMotionFault 1 "Active" 0 "Inactive" ;
VAL_ 2350972777 TFX_ActuatorType 1 "Throttle" 0 "Shift" ;
VAL_ 2350972777 TFX_ActualGearValue 15 "Not Available" 14 "Error" 2 "Reverse" 1 "Neutral" 0 "Forward" ;
VAL_ 2350972777 TFX_SourceInstance 1 "Stbd" 0 "Port" ;
VAL_ 2350972777 TFX_IndustryGroup 5 "IndustrialProcess" 3 "Construction" 2 "AgriculturalAndForestry" 0 "Global" 1 "OnHighway" 4 "Marine" ;
VAL_ 2350972777 TFX_Header 1850 "Teleflex" ;
VAL_ 2348875625 TFX_ControlState_Act 15 "Other" 0 "Startup" 3 "Motion Fault / Ntl-Idle" 2 "Calibration" 1 "Active" ;
VAL_ 2348875625 TFX_WarningFault 1 "Active" 0 "Inactive" ;
VAL_ 2348875625 TFX_ThrUpMotionFault 1 "Active" 0 "Inactive" ;
VAL_ 2348875625 TFX_ThrDwnMotionFault 1 "Active" 0 "Inactive" ;
VAL_ 2348875625 TFX_ShiftRevMotionFault 1 "Active" 0 "Inactive" ;
VAL_ 2348875625 TFX_ShiftNeutMotionFault 1 "Active" 0 "Inactive" ;
VAL_ 2348875625 TFX_ShiftFwdMotionFault 1 "Active" 0 "Inactive" ;
VAL_ 2348875625 TFX_ActuatorType 1 "Throttle" 0 "Shift" ;
VAL_ 2348875625 TFX_ActualGearValue 15 "Not Available" 14 "Error" 2 "Reverse" 1 "Neutral" 0 "Forward" ;
VAL_ 2348875625 TFX_SourceInstance 1 "Stbd" 0 "Port" ;
VAL_ 2348875625 TFX_IndustryGroup 5 "IndustrialProcess" 3 "Construction" 2 "AgriculturalAndForestry" 0 "Global" 1 "OnHighway" 4 "Marine" ;
VAL_ 2348875625 TFX_Header 1850 "Teleflex" ;
VAL_ 2680225653 TFX_TrollModeActive 1 "Yes" 0 "No" ;
VAL_ 2680225653 TFX_IndustryGroup 5 "IndustrialProcess" 3 "Construction" 2 "AgriculturalAndForestry" 0 "Global" 1 "OnHighway" 4 "Marine" ;
VAL_ 2680225653 TFX_Header 1850 "Teleflex" ;
VAL_ 2680225652 TFX_IndustryGroup 5 "IndustrialProcess" 3 "Construction" 2 "AgriculturalAndForestry" 0 "Global" 1 "OnHighway" 4 "Marine" ;
VAL_ 2680225652 TFX_Header 1850 "Teleflex" ;
VAL_ 2680225651 LeadLever 2 "Error" 3 "Not Available" 1 "Starboard" 0 "Port" ;
VAL_ 2680225651 TFX_StbdLeverThrPosition 255 "Not Available" 254 "Error" ;
VAL_ 2680225651 TFX_StbdLeverGearPosition 15 "Not Available" 14 "Error" 2 "Reverse" 1 "Neutral" 0 "Forward" ;
VAL_ 2680225651 TFX_SourceControlType 2 "EST Gateway" 15 "Not Available" 14 "Error" 1 "Joystick" 0 "Control Head" ;
VAL_ 2680225651 TFX_PortLeverThrPosition 255 "Not Available" 254 "Error" ;
VAL_ 2680225651 TFX_PortLeverGearPosition 15 "Not Available" 14 "Error" 2 "Reverse" 1 "Neutral" 0 "Forward" ;
VAL_ 2680225651 TFX_JoystickIsInNeutral 3 "Not Available" 2 "Error" 1 "No" 0 "Yes" ;
VAL_ 2680225651 TFX_IndustryGroup 5 "IndustrialProcess" 3 "Construction" 2 "AgriculturalAndForestry" 0 "Global" 1 "OnHighway" 4 "Marine" ;
VAL_ 2680225651 TFX_Header 1850 "Teleflex" ;
VAL_ 2680225649 TFX_TachometerSignalInvalid 1 "Active" 0 "Inactive" ;
VAL_ 2680225649 TFX_ShiftOutputFault_B 1 "Active" 0 "Inactive" ;
VAL_ 2680225649 TFX_ShiftOutputFault_A 1 "Active" 0 "Inactive" ;
VAL_ 2680225649 TFX_PosSensorShrtToGndFault 1 "Active" 0 "Inactive" ;
VAL_ 2680225649 TFX_PosSensorOpenFault 1 "Active" 0 "Inactive" ;
VAL_ 2680225649 TFX_PosSensorNotCalibratedFault 1 "Active" 0 "Inactive" ;
VAL_ 2680225649 TFX_MotorOverCurrentFault 1 "Active" 0 "Inactive" ;
VAL_ 2680225649 TFX_MotorOpenCircuitFault 1 "Active" 0 "Inactive" ;
VAL_ 2680225649 TFX_CHorJoystickHrtBtLoss 1 "Active" 0 "Inactive" ;
VAL_ 2680225649 TFX_BatteryVoltageTooLowFault 1 "Active" 0 "Inactive" ;
VAL_ 2680225649 TFX_BatteryVoltageTooHighFault 1 "Active" 0 "Inactive" ;
VAL_ 2680225649 TFX_ShiftRevMotionFault 1 "Active" 0 "Inactive" ;
VAL_ 2680225649 TFX_ShiftNeutMotionFault 1 "Active" 0 "Inactive" ;
VAL_ 2680225649 TFX_ShiftFwdMotionFault 1 "Active" 0 "Inactive" ;
VAL_ 2680225649 TFX_ActuatorType 3 "Not Available" 2 "EST Gateway" 1 "Throttle" 0 "Shift" ;
VAL_ 2680225649 TFX_ControlState 15 "Not Available" 14 "Error" 4 "Fault" 3 "Calibration" 2 "Active" 1 "Inactive" ;
VAL_ 2680225649 TFX_SourceInstance 1 "Stbd" 0 "Port" ;
VAL_ 2680225649 TFX_IndustryGroup 5 "IndustrialProcess" 3 "Construction" 2 "AgriculturalAndForestry" 0 "Global" 1 "OnHighway" 4 "Marine" ;
VAL_ 2680225649 TFX_Header 1850 "Teleflex" ;
VAL_ 2680225631 TFX_PCM_DashPanelSystem 1 "Dash Panel System" 0 "Not a Dash Panel System" ;
VAL_ 2680225631 TFX_LimpHomeMode 3 "Mode 4" 2 "Mode 2" 1 "Mode 1" 0 "Off" ;
VAL_ 2680225631 TFX_WarningFault 1 "Active" 0 "Inactive" ;
VAL_ 2680225631 TFX_DangerFault 1 "Active" 0 "Inactive" ;
VAL_ 2680225631 TFX_ControlState_PCM 0 "Unknown" 10 "Open Loop Steering" 9 "Reset" 15 "Not Available" 14 "Error" 8 "Auto-Pilot" 7 "Steering" 6 "Docking" 5 "Freeze" 4 "Purge" 3 "Calibration" 2 "Powerdown" 1 "Inactive" ;
VAL_ 2680225631 TFX_IndustryGroup 5 "IndustrialProcess" 3 "Construction" 2 "AgriculturalAndForestry" 0 "Global" 1 "OnHighway" 4 "Marine" ;
VAL_ 2680225631 TFX_Header 1850 "Teleflex" ;
VAL_ 2680225647 TFX_SS_AckReq 1 "Ack Requested" 0 "No Ack Requested" ;
VAL_ 2680225647 TFX_JoystickMode 3 "Position and Heading Hold" 2 "Heading Hold" 1 "Position Hold" 0 "Manual" ;
VAL_ 2680225647 TFX_MasterJoystick 3 "Not Available" 2 "Not Available" 1 "Master Joystick" 0 "Non-Master Joystick" ;
VAL_ 2680225647 TFX_TransferRqstToESTGateway 3 "Fault Transfer" 2 "Engine Stalled Transfer" 1 "Transfer to Gateway" 0 "No Request" ;
VAL_ 2680225647 TFX_WarningFault 1 "Active" 0 "Inactive" ;
VAL_ 2680225647 TFX_DangerFault 1 "Active" 0 "Inactive" ;
VAL_ 2680225647 TFX_JoystickYpos 127 "Not Available" 126 "Error" ;
VAL_ 2680225647 TFX_JoystickXpos 127 "Not Available" 126 "Error" ;
VAL_ 2680225647 TFX_JoystickThetaPos 127 "Not Available" 126 "Error" ;
VAL_ 2680225647 TFX_JoystickControlling 1 "True" 0 "False" ;
VAL_ 2680225647 TFX_BoostModeActive 1 "True" 0 "False" ;
VAL_ 2680225647 TFX_SourceInstance 15 "Not Available" 14 "Error" ;
VAL_ 2680225647 TFX_IndustryGroup 5 "IndustrialProcess" 3 "Construction" 2 "AgriculturalAndForestry" 0 "Global" 1 "OnHighway" 4 "Marine" ;
VAL_ 2680225647 TFX_Header 1850 "Teleflex" ;
VAL_ 2680225646 TFX_DangerFault 1 "Active" 0 "Inactive" ;
VAL_ 2680225646 TFX_WarningFault 1 "Active" 0 "Inactive" ;
VAL_ 2680225646 TFX_SyncModeActive 1 "Yes" 0 "No" ;
VAL_ 2680225646 TFX_StbdNTWactive 1 "Yes" 0 "No" ;
VAL_ 2680225646 TFX_StbdLeverGearPosition 15 "Not Available" 14 "Error" 2 "Reverse" 1 "Neutral" 0 "Forward" ;
VAL_ 2680225646 TFX_PortLeverGearPosition 15 "Not Available" 14 "Error" 2 "Reverse" 1 "Neutral" 0 "Forward" ;
VAL_ 2680225646 TFX_PortNTWactive 1 "Yes" 0 "No" ;
VAL_ 2680225646 TFX_CHcontrolling 1 "Yes" 0 "No" ;
VAL_ 2680225646 TFX_SourceInstance 1 "Stbd" 0 "Port" ;
VAL_ 2680225646 TFX_IndustryGroup 5 "IndustrialProcess" 3 "Construction" 2 "AgriculturalAndForestry" 0 "Global" 1 "OnHighway" 4 "Marine" ;
VAL_ 2680225646 TFX_Header 1850 "Teleflex" ;
VAL_ 2680225637 TFX_IndustryGroup 5 "IndustrialProcess" 3 "Construction" 2 "AgriculturalAndForestry" 0 "Global" 1 "OnHighway" 4 "Marine" ;
VAL_ 2680225637 TFX_GearCommand_1 3 "Not Available" 2 "Reverse" 1 "Neutral" 0 "Forward" ;
VAL_ 2680225637 TFX_Header 1850 "Teleflex" ;
VAL_ 2680225696 TFX_StbdShftFbk 3 "Not Available" 2 "Reverse" 1 "Neutral" 0 "Forward" ;
VAL_ 2680225696 TFX_PrtShftFbk 3 "Not Available" 2 "Reverse" 1 "Neutral" 0 "Forward" ;
VAL_ 2680225696 TFX_StbdShftCmd 3 "Not Available" 2 "Reverse" 1 "Neutral" 0 "Forward" ;
VAL_ 2680225696 TFX_PrtShftCmd 3 "Not Available" 2 "Reverse" 1 "Neutral" 0 "Forward" ;
VAL_ 2680225677 TFX_JS_CL_State_Stbd 2 "Latched" 1 "Enabled" 0 "Disabled" ;
VAL_ 2680225677 TFX_JS_CL_State_Port 2 "Latched" 1 "Enabled" 0 "Disabled" ;
VAL_ 2680225676 TFX_GearFbk_StbdInternal 3 "Not Available" 2 "Reverse" 1 "Neutral" 0 "Forward" ;
VAL_ 2680225676 TFX_GearFbk_PortInternal 3 "Not Available" 2 "Reverse" 1 "Neutral" 0 "Forward" ;
VAL_ 2680225676 TFX_GearCmd_StbdInternal 3 "Not Available" 2 "Reverse" 1 "Neutral" 0 "Forward" ;
VAL_ 2680225676 TFX_GearCmd_PortInternal 3 "Not Available" 2 "Reverse" 1 "Neutral" 0 "Forward" ;
VAL_ 2680225676 TFX_VC_State 10 "Power Down" 9 "Limp Home" 8 "Fault" 7 "Vessel Calibration" 6 "Active" 5 "Pre-Active" 4 "Inactive" 3 "Station Select" 2 "Lamp Test" 1 "Joystick Calibration" 0 "Startup" ;
VAL_ 2680225676 TFX_VC_ControlState 6 "CCW" 5 "CW" 4 "Port" 3 "Reverse" 2 "Starboard" 1 "Forward" 0 "Neutral" ;
VAL_ 2680225636 TFX_IndustryGroup 5 "IndustrialProcess" 3 "Construction" 2 "AgriculturalAndForestry" 0 "Global" 1 "OnHighway" 4 "Marine" ;
VAL_ 2680225636 TFX_GearCommand_0 3 "Not Available" 2 "Reverse" 1 "Neutral" 0 "Forward" ;
VAL_ 2680225636 TFX_Header 1850 "Teleflex" ;
VAL_ 2680225630 TFX_SCM_PortCriticalFault 1 "Active" 0 "Inactive" ;
VAL_ 2680225630 TFX_SCM_CriticalFault 1 "Active" 0 "Inactive" ;
VAL_ 2680225630 TFX_SCM_StbdCriticalFault 1 "Active" 0 "Inactive" ;
VAL_ 2680225630 TFX_SourceInstance 1 "Stbd" 0 "Port" ;
VAL_ 2680225630 TFX_IndustryGroup 5 "IndustrialProcess" 3 "Construction" 2 "AgriculturalAndForestry" 0 "Global" 1 "OnHighway" 4 "Marine" ;
VAL_ 2680225630 TFX_Header 1850 "Teleflex" ;
VAL_ 2680225626 TFX_CommandType 1 "Steering" 0 "Rudder" ;
VAL_ 2680225626 TFX_IndustryGroup 5 "IndustrialProcess" 3 "Construction" 2 "AgriculturalAndForestry" 0 "Global" 1 "OnHighway" 4 "Marine" ;
VAL_ 2680225626 TFX_Header 1850 "Teleflex" ;
VAL_ 2147614225 SetCOGheadingRef 3 "Null" 2 "Error" 1 "Magnetic" 0 "True" ;
VAL_ 2147614225 DataMode 15 "DatNotAvail" 14 "Error" 13 "Undefined" 12 "Undefined" 11 "Undefined" 10 "Undefined" 9 "Undefined" 8 "Undefined" 7 "Undefined" 6 "Undefined" 5 "Undefined" 4 "Manual" 3 "Simulator" 2 "Estimator" 1 "Differential" 0 "Autonomous" ;
VAL_ 2147613972 WaterTemperature 3 "Null" 2 "Error" 1 "Magnetic" 0 "True" ;
VAL_ 2147613972 AirTemperature 3 "Null" 2 "Error" 1 "Magnetic" 0 "True" ;
VAL_ 2147613972 PressureTendencyRate 3 "Null" 2 "Error" 1 "Magnetic" 0 "True" ;
VAL_ 2147613972 AtmosphericPressure 3 "Null" 2 "Error" 1 "Magnetic" 0 "True" ;
VAL_ 2147613972 DominantWavePeriod 3 "Null" 2 "Error" 1 "Magnetic" 0 "True" ;
VAL_ 2147613972 WaveHeight 3 "Null" 2 "Error" 1 "Magnetic" 0 "True" ;
VAL_ 2147613972 WindGusts 3 "Null" 2 "Error" 1 "Magnetic" 0 "True" ;
VAL_ 2147613972 WindReference 7 "Null" 6 "Error" 5 "Reserved" 4 "Reserved" 3 "True (boat referenced)" 2 "Apparent" 1 "Magnetic" 0 "True (reference to North)" ;
VAL_ 2147613971 AirTemperature 3 "" 2 "" 1 "" 0 "" ;
VAL_ 2147613971 AtmosphericPressure 3 "" 2 "" 1 "" 0 "" ;
VAL_ 2147613971 WindGusts 3 "" 2 "" 1 "" 0 "" ;
VAL_ 2147613971 WindReference 7 "Null" 6 "Error" 5 "Reserved" 4 "Reserved" 3 "True (boat referenced)" 2 "Apparent" 1 "Magnetic" 0 "True (reference to North)" ;
VAL_ 2147613954 WindReference 7 "Null" 6 "Error" 5 "Reserved" 4 "Reserved" 3 "True (boat referenced)" 2 "Apparent" 1 "Magnetic" 0 "True (referenced to north)" ;
VAL_ 2147613199 UsedAsCorrectionSource 3 "unavailable" 2 "Error" 1 "YES" 0 "NO" ;
VAL_ 2147613199 BitRate 31 "Null" 30 "Error" 12 "38400bps" 11 "19200bps" 10 "9600bps" 9 "4800bps" 8 "2400bps" 7 "1200bps" 6 "500bps" 5 "300bps" 4 "200bps" 2 "50bps" 3 "100bps" 1 "25bps" 0 "Auto detect" ;
VAL_ 2147613199 StationID 15 "" 14 "" 3 "" 1 "" 0 "" ;
VAL_ 2147613199 StationType 15 "Null" 14 "Error" 3 "Reserved" 1 "GLONASS" 0 "GPS" ;
VAL_ 2147613198 DifferentialOperationMode 15 "NoSelection" 14 "Error" 3 "Reserve" 2 "AutoRange" 1 "AutoPower" 0 "Manual" ;
VAL_ 2147613198 Mode 3 "Error" 2 "Reserve" 1 "ManualBitRateSet" 0 "AutoBitRateSet" ;
VAL_ 2147613198 BitRate 31 "Null" 30 "Error" 12 "38400bps" 11 "19200bps" 10 "9600bps" 9 "4800bps" 8 "2400bps" 7 "1200bps" 6 "500bps" 5 "300bps" 4 "200bps" 2 "50bps" 3 "100bps" 1 "25bps" 0 "Auto detect" ;
VAL_ 2147613197 StationHealth 15 "Null" 4 "In Test mode" 3 "Healthy & in test mode" 2 "Healthy & operational" 1 "Unmonitored" 0 "Not working" ;
VAL_ 2147613197 ReferenceStationType 15 "Null" 14 "Error" 1 "GLONASS" 0 "GPS" ;
VAL_ 2147613193 IntegrityFlag 3 "Unsafe" 2 "Caution" 1 "Safe" 0 "No integrity checking" ;
VAL_ 2147613188 PNRStatus2 15 "NoSelection" 14 "Error" 5 "UsedWithDifflCorrections" 4 "TrackedWithDifflCorrections" 3 "DiffCorrectionsAvailable" 2 "UsedInSolWODiffCorrections" 1 "TrackedButNotUsedInSolution" 0 "NotTracked" ;
VAL_ 2147613188 PNRStatus1 15 "NoSelection" 14 "Error" 5 "UsedWithDifflCorrections" 4 "TrackedWithDifflCorrections" 3 "DiffCorrectionsAvailable" 2 "UsedInSolWODiffCorrections" 1 "TrackedButNotUsedInSolution" 0 "NotTracked" ;
VAL_ 2147613188 Mode 3 "Null" 2 "Error" 1 "range residuals were calculated " 0 "range resifuals were used to cal" ;
VAL_ 2147613187 OpMode 7 "Null" 6 "Error" 5 "Reserve" 4 "Reserve" 3 "Auto" 2 "D3" 1 "D2" 0 "D1" ;
VAL_ 2147613187 SetMode 7 "Null" 6 "Error" 5 "Reserve" 4 "Reserve" 3 "Auto" 2 "D3" 1 "D2" 0 "D1" ;
VAL_ 2147613186 UseAntennaAltitudeFor2DMode 3 "Unavailable" 2 "Error" 1 "Yes" 0 "No" ;
VAL_ 2147613186 PositionVelocityFilter 3 "UnavailableUnknown" 2 "Error" 1 "YesOnEnabled" 0 "NoOffDisabled" ;
VAL_ 2147613186 GNNSMode 7 "NULL" 6 "Error" 5 "Res2" 4 "Res1" 3 "Auto" 2 "D3" 1 "D2" 0 "D1" ;
VAL_ 2147612950 DestinationMarkType 15 "Null" 14 "Error" 4 "Waypoint" 3 "Reference (general)" 2 "Reference point" 1 "Turning point" 0 "Collision" ;
VAL_ 2147612950 OriginMarkType 15 "Null" 14 "Error" 4 "Waypoint" 3 "Reference (general)" 2 "Reference point" 1 "Turning point" 0 "Collision" ;
VAL_ 2147612950 BearingRef 3 "NULL" 2 "Error" 1 "Magnetic" 0 "True" ;
VAL_ 2147612949 MarkType 4 "Waypoint" 3 "WheelOver" 1 "TurningPoint" 2 "Reference" 0 "Collision" ;
VAL_ 2147612939 SetRef 3 "NULL" 2 "Error" 1 "Magnetic" 0 "True" ;
VAL_ 2147612932 CalculationType 3 "Unknown" 2 "Error" 1 "RhumbLine" 0 "GreatCircle" ;
VAL_ 2147612932 ArrivalCircleEnterd 3 "Unknown" 2 "Error" 1 "YesOnEnabledSet" 0 "NoOffDisabledReset" ;
VAL_ 2147612932 PerpendCrossed 3 "Unknown" 2 "Error" 1 "YesOnEnabledSet" 0 "NoOffDisableReset" ;
VAL_ 2147612932 CourseBearingRef 3 "Null" 2 "Error" 1 "Magnetic" 0 "True" ;
VAL_ 2147612931 HeadingRef 3 "NULL" 2 "Error" 1 "Magnetic" 0 "True" ;
VAL_ 2147612931 XTEMode 2 "Estimated" 1 "DifferentialEnhanced" 0 "Autonomous" ;
VAL_ 2147612677 RefStationType2 1 "GLONASS" 0 "GPS" ;
VAL_ 2147612677 RefStationType1 15 "Null" 14 "Error" 1 "GLONASS" 0 "GPS" ;
VAL_ 2147612677 GNSSIntegrity 3 "Unsafe" 2 "Caution" 1 "Safe" 0 "No integrity check" ;
VAL_ 2147612677 MethodGNSS 15 "Null" 14 "Error" 8 "Simulated mode" 7 "Manual input" 6 "Estimated (DR) mode" 5 "RTK float" 4 "RTK fixed integer" 3 "Precise GNSS" 2 "DGNSS fix" 1 "GNSS fix" 0 "no GPS" ;
VAL_ 2147612677 TypeOfSystem 4 "GPS+SBAS+GLONASS" 3 "GPS+SBAS(WAAS)" 2 "GPS+GLONASS" 1 "GLONASS" 0 "GPS" ;
VAL_ 2147612674 COGReference 3 "Null" 2 "Error" 1 "Magnetic" 0 "True" ;
VAL_ 2147612173 ElectronicPositionFixingDevice 15 "Null" 14 "Error" 8 "Reserved" 7 "Surveyed" 6 "IntegratedNavigationSystem" 5 "Chayka" 4 "LoranC" 3 "CombinedGPS_GLONOSS" 2 "GLONASS" 1 "GPS" 0 "Undefined" ;
VAL_ 2147612172 UAISReserveBits 15 "DataNotAvailable" 14 "Error" 4 "ManualMode" 3 "SimulatorMode" 2 "EstimatedMode" 1 "DifferentialMode" 0 "AutonomousMode" ;
VAL_ 2147612172 PositionalMode 15 "DataNotAvailable" 14 "Error" 4 "ManualMode" 3 "SimulatorMode" 2 "EstimatedMode" 1 "DifferentialMode" 0 "AutonomousMode" ;
VAL_ 2147612172 RepeatIndicator 7 "Null" 6 "Error" 4 "Reserved" 1 "Repeated" 0 "ShipborneMessage" ;
VAL_ 2147612172 CommunicationsState 15 "Null" 14 "Error" 13 "Reserved" 12 "Reserved" 11 "Reserved" 10 "Reserved" 9 "Reserved" 8 "Reserved" 7 "Reserved" 6 "Reserved" 5 "Reserved" 4 "GPSAttitudeDeterminationSystem" 3 "FluxGateCompass" 2 "HallEffectCompass" 1 "MagneticCompass" 0 "Gyro" ;
VAL_ 2147612172 HeadingSource 15 "Null" 14 "Error" 13 "Reserved" 12 "Reserved" 11 "Reserved" 10 "Reserved" 9 "Reserved" 8 "Reserved" 7 "Reserved" 6 "Reserved" 5 "Reserved" 4 "GPSAttitudeDeterminationSystem" 3 "FluxGateCompass" 2 "HallEffectCompass" 1 "MagneticCompass" 0 "Gyro" ;
VAL_ 2147612172 HeadingReference 3 "Null" 2 "Error" 1 "Magnetic" 0 "True" ;
VAL_ 2147612172 NavigationStatus 7 "Unknown" 6 "Error" 5 "Undefined" 4 "Undefined" 3 "RestrictedManeuverability" 2 "NotUnderWay" 1 "AtAnchor" 0 "UnderWay" ;
VAL_ 2147612172 DataAvailable 3 "Unavailable" 2 "Error" 1 "Yes" 0 "No" ;
VAL_ 2147612172 DataTerminalEquipmentAvailable 3 "Unavailable" 2 "Error" 1 "Yes" 0 "No" ;
VAL_ 2147612168 BearingReference 3 "Relative" 2 "Error" 1 "Magnetic" 0 "True" ;
VAL_ 2147612168 TrackStatus 3 "Lost target" 2 "Tracking target" 1 "Initial acquisition target" 0 "Cancelled or not available" ;
VAL_ 2147611153 FluidType 15 "Data not available" 14 "Error" 3 "Live well" 2 "Waste water" 1 "Fresh water" 0 "Fuel" ;
VAL_ 2147611150 Switch28 3 "NoAction" 2 "ToggleExistingState" 1 "TurnOn" 0 "TurnOff" ;
VAL_ 2147611150 Switch27 3 "NoAction" 2 "ToggleExistingState" 1 "TurnOn" 0 "TurnOff" ;
VAL_ 2147611150 Switch26 3 "NoAction" 2 "ToggleExistingState" 1 "TurnOn" 0 "TurnOff" ;
VAL_ 2147611150 Switch25 3 "NoAction" 2 "ToggleExistingState" 1 "TurnOn" 0 "TurnOff" ;
VAL_ 2147611150 Switch24 3 "NoAction" 2 "ToggleExistingState" 1 "TurnOn" 0 "TurnOff" ;
VAL_ 2147611150 Switch23 3 "NoAction" 2 "ToggleExistingState" 1 "TurnOn" 0 "TurnOff" ;
VAL_ 2147611150 Switch22 3 "NoAction" 2 "ToggleExistingState" 1 "TurnOn" 0 "TurnOff" ;
VAL_ 2147611150 Switch21 3 "NoAction" 2 "ToggleExistingState" 1 "TurnOn" 0 "TurnOff" ;
VAL_ 2147611150 Switch20 3 "NoAction" 2 "ToggleExistingState" 1 "TurnOn" 0 "TurnOff" ;
VAL_ 2147611150 Switch19 3 "NoAction" 2 "ToggleExistingState" 1 "TurnOn" 0 "TurnOff" ;
VAL_ 2147611150 Switch18 3 "NoAction" 2 "ToggleExistingState" 1 "TurnOn" 0 "TurnOff" ;
VAL_ 2147611150 Switch17 3 "NoAction" 2 "ToggleExistingState" 1 "TurnOn" 0 "TurnOff" ;
VAL_ 2147611150 Switch16 3 "NoAction" 2 "ToggleExistingState" 1 "TurnOn" 0 "TurnOff" ;
VAL_ 2147611150 Switch15 3 "NoAction" 2 "ToggleExistingState" 1 "TurnOn" 0 "TurnOff" ;
VAL_ 2147611150 Switch14 3 "NoAction" 2 "ToggleExistingState" 1 "TurnOn" 0 "TurnOff" ;
VAL_ 2147611150 Switch13 3 "NoAction" 2 "ToggleExistingState" 1 "TurnOn" 0 "TurnOff" ;
VAL_ 2147611150 Switch12 3 "NoAction" 2 "ToggleExistingState" 1 "TurnOn" 0 "TurnOff" ;
VAL_ 2147611150 Switch11 3 "NoAction" 2 "ToggleExistingState" 1 "TurnOn" 0 "TurnOff" ;
VAL_ 2147611150 Switch10 3 "NoAction" 2 "ToggleExistingState" 1 "TurnOn" 0 "TurnOff" ;
VAL_ 2147611150 Switch9 3 "NoAction" 2 "ToggleExistingState" 1 "TurnOn" 0 "TurnOff" ;
VAL_ 2147611150 Switch8 3 "NoAction" 2 "ToggleExistingState" 1 "TurnOn" 0 "TurnOff" ;
VAL_ 2147611150 Switch7 3 "NoAction" 2 "ToggleExistingState" 1 "TurnOn" 0 "TurnOff" ;
VAL_ 2147611150 Switch6 3 "NoAction" 2 "ToggleExistingState" 1 "TurnOn" 0 "TurnOff" ;
VAL_ 2147611150 Switch5 3 "NoAction" 2 "ToggleExistingState" 1 "TurnOn" 0 "TurnOff" ;
VAL_ 2147611150 Switch4 3 "NoAction" 2 "ToggleExistingState" 1 "TurnOn" 0 "TurnOff" ;
VAL_ 2147611150 Switch3 3 "NoAction" 2 "ToggleExistingState" 1 "TurnOn" 0 "TurnOff" ;
VAL_ 2147611150 Switch2 3 "NoAction" 2 "ToggleExistingState" 1 "TurnOn" 0 "TurnOff" ;
VAL_ 2147611150 Switch1 3 "NoAction" 2 "ToggleExistingState" 1 "TurnOn" 0 "TurnOff" ;
VAL_ 2147611146 EngineInstance 7 "NotAvailable" 6 "Error" 5 "Reserved" 4 "All" 3 "Instance3" 2 "Instance2" 1 "Instance1" 0 "Instance0" ;
VAL_ 2147611145 EngineInstance 7 "NotAvailable" 6 "Error" 5 "Reserved" 4 "All" 3 "Instance3" 2 "Instance2" 1 "Instance1" 0 "Instance0" ;
VAL_ 2147611141 TransmissionGear 3 "Unavailable" 2 "Reverse" 1 "Neutral" 0 "Forward" ;
VAL_ 2147610898 HeadingSensorRef 3 "Null" 2 "Error" 1 "Magnetic" 0 "True" ;
VAL_ 2147610896 ControlStaionState 6 "RefuseControl" 5 "ReleaseControl" 4 "AcceptControl" 3 "RequestControl" 2 "OfferControl" 1 "AssignControl" 0 "CurrentControl" ;
VAL_ 2147610896 ControlMethod 5 "TrackControl" 4 "HeadingControl" 3 "HeadingControlStandalone" 2 "FollowUpDevice" 1 "NonFollowUpDevice" 0 "MainSteeringOutsideSystem" ;
VAL_ 2147610896 ControlStationFunction 4 "Propulsion" 2 "VoyageManagement" 1 "Steering" 0 "Reserved" ;
VAL_ 2147610893 DirectionOrder 2 "MoveToPort" 1 "MoveToStarboard" 0 "NoOrder" ;
VAL_ 2147609856 PGNErrorCode 3 "Access denied" 2 "PGN temporarily not available" 1 "PGN not supported" 0 "No Error/Acknowledge" ;
VAL_ 2147609088 RequestedPGN 255 "NotAvailable" ;
VAL_ 2147548888 IndustryGroup 5 "IndustrialProcess" 3 "Construction" 2 "AgriculturalAndForestry" 0 "Global" 1 "OnHighway" 4 "Marine" ;
VAL_ 2147548888 ManufacturerCode 1861 "Vector" 1860 "MetalMarine" 1859 "Kvaser" 1858 "LittonMarine" 1857 "Simrad" 1856 "Trimble" 1855 "Furuno" 1854 "NorthStar" 1853 "JapanRadioCorp" 1852 "Navionics" 1851 "RaytheonMarine" 1850 "TeleflexMarine" ;
VAL_ 2147544576 TFX_IndustryGroup 5 "IndustrialProcess" 3 "Construction" 2 "AgriculturalAndForestry" 0 "Global" 1 "OnHighway" 4 "Marine" ;
VAL_ 2147544576 ManufacturerCode 1861 "Vector" 1860 "MetalMarine" 1859 "Kvaser" 1858 "LittonMarine" 1857 "Simrad" 1856 "Trimble" 1855 "Furuno" 1854 "NorthStar" 1853 "JapanRadioCorp" 1852 "Navionics" 1851 "RaytheonMarine" 1850 "TeleflexMarine" ;
VAL_ 2147544064 ControlByte 37 "Abort" 25 "EoMA" 23 "CTS" 22 "RTS" ;
VAL_ 2147543040 CtrlByte 2 "PGNsupported_accessdenied" 1 "NegativeAcknowledgement" 0 "PositiveAcknowledgement" ;
SIG_VALTYPE_ 2147613969 Salinity : 1;
SIG_VALTYPE_ 2147612693 EllipsoidSemiMajorAxis : 1;
SIG_VALTYPE_ 2147612693 Scale : 1;
SIG_VALTYPE_ 2147612693 RotationZ : 1;
SIG_VALTYPE_ 2147612693 RotationY : 1;
SIG_VALTYPE_ 2147612693 RotationX : 1;
